VERSION ""

NS_ :

BS_:

BU_: PowertrainControlModule AtmosphericSensor SafetyRestraintSystem2 Aftertreatment_2_GasOutlet Aftertreatment_2_GasIntake DieselParticulateFilterControl Turbocharger SafetyRestraintSystem1 CabDisplay2 Aftertreatment_1_GasOutlet Aftertreatment_1_GasIntake OnBoardDataLogger OffBoardDiagnosticTool2 OffBoardDiagnosticTool1 FileServer ParkingBrakeController SeatController2 FanDriveController SteeringColumnUnit CommunicationUnitRadio CommunicationUnitSatellite CommunicationUnitCellular PropulsionBatteryCharger ChassisController2 ChassisController1 EngineValveControl AuxiliaryHeater2 AuxiliaryHeater1 ClutchUnit RampControl InformationSystem1 SuspensionSystemController2 OilSensor VehicleDynamicStability ExhaustEmissionController TransmissionDisplay2 TransmissionDisplay1 ClimateControl2 WaterPumpController RearAxleSteeringController LightingOperatorControl SeatController1 IgnitionController2 IgnitionController1 TirePressureController CabController2 CabController1 PneumaticSystemController SuspensionSystemController1 HydraulicPumpController EnduranceBrakingSystem RetarderExhaustEngine2 OnBoardDiagnosticUnit HeadwayController RetarderExhaustEngine1 CabDisplay1 ManagementComputer VirtualTerminal OffVehicleGateway PowerTakeOffFront HitchControl AuxiliaryValveControl BodyController TractorTrailerBridge1 StarterSystem ElectricalSystem VehicleSecurity VehicleNavigation AerodynamicControl ElectricalChargingSystem ClimateControl1 TripRecorder InstrumentCluster SuspensionDriveAxle2 SuspensionDriveAxle1 SuspensionSteerAxle SteeringController FuelSystem CruiseControl RetarderDriveline RetarderEngine BrakesDriveAxle2 BrakesDriveAxle1 BrakesSystemController BrakesSteerAxle AxleDrive2 AxleDrive1 AxleSteering PowerTakeOff ShiftConsoleSecondary ShiftConsolePrimary Transmission2 Transmission1 Engine2 Engine1

BO_ 2633669886 HVESP23HIST: 19 Vector__XXX
 SG_ TotalEnergyOut : 120|32@1+ (1,0) [0|4211081215] "kWh" Vector__XXX
 SG_ TotalEnergyInput : 88|32@1+ (1,0) [0|4211081215] "kWh" Vector__XXX
 SG_ TotalAccumulatedCharge : 56|32@1+ (100,0) [0|421108121500] "Ah" Vector__XXX
 SG_ TotalEnergyThroughput : 24|32@1+ (100,0) [0|421108121500] "Wh" Vector__XXX
 SG_ ContactorOpenUnderLoadCount : 8|16@1+ (1,0) [0|64255] "" Vector__XXX
 SG_ StOfHealth : 0|8@1+ (0.4,0) [0|100] "%" Vector__XXX

BO_ 2566560766 HVESP22CFG: 19 Vector__XXX
 SG_ NomRatedCapacity : 128|24@1+ (0.001,0) [0|16449.535] "kWh" Vector__XXX
 SG_ CellMinVLmt : 120|8@1+ (0.02044,0) [0|5.11] "V" Vector__XXX
 SG_ CellMaxVLmt : 112|8@1+ (0.02044,0) [0|5.11] "V" Vector__XXX
 SG_ RecommendedMinOperatingTemp : 96|16@1+ (0.03125,-273) [-273|1734.96875] "°C" Vector__XXX
 SG_ RecommendedMaxOperatingTemp : 80|16@1+ (0.03125,-273) [-273|1734.96875] "°C" Vector__XXX
 SG_ RecommendedMaxStOfCharge : 64|16@1+ (0.0015625,0) [0|100.3984375] "%" Vector__XXX
 SG_ RecommendedMinStOfCharge : 48|16@1+ (0.0015625,0) [0|100.3984375] "%" Vector__XXX
 SG_ RecommendedMaxOperatingV : 32|16@1+ (0.05,0) [0|3212.75] "V" Vector__XXX
 SG_ RecommendedMinOperatingV : 16|16@1+ (0.05,0) [0|3212.75] "V" Vector__XXX
 SG_ NomV : 0|16@1+ (0.05,0) [0|3212.75] "V" Vector__XXX

BO_ 2633669374 HVESP22HIST: 19 Vector__XXX
 SG_ TotalEnergyOut : 120|32@1+ (1,0) [0|4211081215] "kWh" Vector__XXX
 SG_ TotalEnergyInput : 88|32@1+ (1,0) [0|4211081215] "kWh" Vector__XXX
 SG_ TotalAccumulatedCharge : 56|32@1+ (100,0) [0|421108121500] "Ah" Vector__XXX
 SG_ TotalEnergyThroughput : 24|32@1+ (100,0) [0|421108121500] "Wh" Vector__XXX
 SG_ ContactorOpenUnderLoadCount : 8|16@1+ (1,0) [0|64255] "" Vector__XXX
 SG_ StOfHealth : 0|8@1+ (0.4,0) [0|100] "%" Vector__XXX

BO_ 2566560254 HVESP21CFG: 19 Vector__XXX
 SG_ NomRatedCapacity : 128|24@1+ (0.001,0) [0|16449.535] "kWh" Vector__XXX
 SG_ CellMinVLmt : 120|8@1+ (0.02044,0) [0|5.11] "V" Vector__XXX
 SG_ CellMaxVLmt : 112|8@1+ (0.02044,0) [0|5.11] "V" Vector__XXX
 SG_ RecommendedMinOperatingTemp : 96|16@1+ (0.03125,-273) [-273|1734.96875] "°C" Vector__XXX
 SG_ RecommendedMaxOperatingTemp : 80|16@1+ (0.03125,-273) [-273|1734.96875] "°C" Vector__XXX
 SG_ RecommendedMaxStOfCharge : 64|16@1+ (0.0015625,0) [0|100.3984375] "%" Vector__XXX
 SG_ RecommendedMinStOfCharge : 48|16@1+ (0.0015625,0) [0|100.3984375] "%" Vector__XXX
 SG_ RecommendedMaxOperatingV : 32|16@1+ (0.05,0) [0|3212.75] "V" Vector__XXX
 SG_ RecommendedMinOperatingV : 16|16@1+ (0.05,0) [0|3212.75] "V" Vector__XXX
 SG_ NomV : 0|16@1+ (0.05,0) [0|3212.75] "V" Vector__XXX

BO_ 2633668862 HVESP21HIST: 19 Vector__XXX
 SG_ TotalEnergyOut : 120|32@1+ (1,0) [0|4211081215] "kWh" Vector__XXX
 SG_ TotalEnergyInput : 88|32@1+ (1,0) [0|4211081215] "kWh" Vector__XXX
 SG_ TotalAccumulatedCharge : 56|32@1+ (100,0) [0|421108121500] "Ah" Vector__XXX
 SG_ TotalEnergyThroughput : 24|32@1+ (100,0) [0|421108121500] "Wh" Vector__XXX
 SG_ ContactorOpenUnderLoadCount : 8|16@1+ (1,0) [0|64255] "" Vector__XXX
 SG_ StOfHealth : 0|8@1+ (0.4,0) [0|100] "%" Vector__XXX

BO_ 2566559742 HVESP20CFG: 19 Vector__XXX
 SG_ NomRatedCapacity : 128|24@1+ (0.001,0) [0|16449.535] "kWh" Vector__XXX
 SG_ CellMinVLmt : 120|8@1+ (0.02044,0) [0|5.11] "V" Vector__XXX
 SG_ CellMaxVLmt : 112|8@1+ (0.02044,0) [0|5.11] "V" Vector__XXX
 SG_ RecommendedMinOperatingTemp : 96|16@1+ (0.03125,-273) [-273|1734.96875] "°C" Vector__XXX
 SG_ RecommendedMaxOperatingTemp : 80|16@1+ (0.03125,-273) [-273|1734.96875] "°C" Vector__XXX
 SG_ RecommendedMaxStOfCharge : 64|16@1+ (0.0015625,0) [0|100.3984375] "%" Vector__XXX
 SG_ RecommendedMinStOfCharge : 48|16@1+ (0.0015625,0) [0|100.3984375] "%" Vector__XXX
 SG_ RecommendedMaxOperatingV : 32|16@1+ (0.05,0) [0|3212.75] "V" Vector__XXX
 SG_ RecommendedMinOperatingV : 16|16@1+ (0.05,0) [0|3212.75] "V" Vector__XXX
 SG_ NomV : 0|16@1+ (0.05,0) [0|3212.75] "V" Vector__XXX

BO_ 2633668350 HVESP20HIST: 19 Vector__XXX
 SG_ TotalEnergyOut : 120|32@1+ (1,0) [0|4211081215] "kWh" Vector__XXX
 SG_ TotalEnergyInput : 88|32@1+ (1,0) [0|4211081215] "kWh" Vector__XXX
 SG_ TotalAccumulatedCharge : 56|32@1+ (100,0) [0|421108121500] "Ah" Vector__XXX
 SG_ TotalEnergyThroughput : 24|32@1+ (100,0) [0|421108121500] "Wh" Vector__XXX
 SG_ ContactorOpenUnderLoadCount : 8|16@1+ (1,0) [0|64255] "" Vector__XXX
 SG_ StOfHealth : 0|8@1+ (0.4,0) [0|100] "%" Vector__XXX

BO_ 2566559230 HVESP19CFG: 19 Vector__XXX
 SG_ NomRatedCapacity : 128|24@1+ (0.001,0) [0|16449.535] "kWh" Vector__XXX
 SG_ CellMinVLmt : 120|8@1+ (0.02044,0) [0|5.11] "V" Vector__XXX
 SG_ CellMaxVLmt : 112|8@1+ (0.02044,0) [0|5.11] "V" Vector__XXX
 SG_ RecommendedMinOperatingTemp : 96|16@1+ (0.03125,-273) [-273|1734.96875] "°C" Vector__XXX
 SG_ RecommendedMaxOperatingTemp : 80|16@1+ (0.03125,-273) [-273|1734.96875] "°C" Vector__XXX
 SG_ RecommendedMaxStOfCharge : 64|16@1+ (0.0015625,0) [0|100.3984375] "%" Vector__XXX
 SG_ RecommendedMinStOfCharge : 48|16@1+ (0.0015625,0) [0|100.3984375] "%" Vector__XXX
 SG_ RecommendedMaxOperatingV : 32|16@1+ (0.05,0) [0|3212.75] "V" Vector__XXX
 SG_ RecommendedMinOperatingV : 16|16@1+ (0.05,0) [0|3212.75] "V" Vector__XXX
 SG_ NomV : 0|16@1+ (0.05,0) [0|3212.75] "V" Vector__XXX

BO_ 2633667838 HVESP19HIST: 19 Vector__XXX
 SG_ TotalEnergyOut : 120|32@1+ (1,0) [0|4211081215] "kWh" Vector__XXX
 SG_ TotalEnergyInput : 88|32@1+ (1,0) [0|4211081215] "kWh" Vector__XXX
 SG_ TotalAccumulatedCharge : 56|32@1+ (100,0) [0|421108121500] "Ah" Vector__XXX
 SG_ TotalEnergyThroughput : 24|32@1+ (100,0) [0|421108121500] "Wh" Vector__XXX
 SG_ ContactorOpenUnderLoadCount : 8|16@1+ (1,0) [0|64255] "" Vector__XXX
 SG_ StOfHealth : 0|8@1+ (0.4,0) [0|100] "%" Vector__XXX

BO_ 2566558718 HVESP18CFG: 19 Vector__XXX
 SG_ NomRatedCapacity : 128|24@1+ (0.001,0) [0|16449.535] "kWh" Vector__XXX
 SG_ CellMinVLmt : 120|8@1+ (0.02044,0) [0|5.11] "V" Vector__XXX
 SG_ CellMaxVLmt : 112|8@1+ (0.02044,0) [0|5.11] "V" Vector__XXX
 SG_ RecommendedMinOperatingTemp : 96|16@1+ (0.03125,-273) [-273|1734.96875] "°C" Vector__XXX
 SG_ RecommendedMaxOperatingTemp : 80|16@1+ (0.03125,-273) [-273|1734.96875] "°C" Vector__XXX
 SG_ RecommendedMaxStOfCharge : 64|16@1+ (0.0015625,0) [0|100.3984375] "%" Vector__XXX
 SG_ RecommendedMinStOfCharge : 48|16@1+ (0.0015625,0) [0|100.3984375] "%" Vector__XXX
 SG_ RecommendedMaxOperatingV : 32|16@1+ (0.05,0) [0|3212.75] "V" Vector__XXX
 SG_ RecommendedMinOperatingV : 16|16@1+ (0.05,0) [0|3212.75] "V" Vector__XXX
 SG_ NomV : 0|16@1+ (0.05,0) [0|3212.75] "V" Vector__XXX

BO_ 2633667326 HVESP18HIST: 19 Vector__XXX
 SG_ TotalEnergyOut : 120|32@1+ (1,0) [0|4211081215] "kWh" Vector__XXX
 SG_ TotalEnergyInput : 88|32@1+ (1,0) [0|4211081215] "kWh" Vector__XXX
 SG_ TotalAccumulatedCharge : 56|32@1+ (100,0) [0|421108121500] "Ah" Vector__XXX
 SG_ TotalEnergyThroughput : 24|32@1+ (100,0) [0|421108121500] "Wh" Vector__XXX
 SG_ ContactorOpenUnderLoadCount : 8|16@1+ (1,0) [0|64255] "" Vector__XXX
 SG_ StOfHealth : 0|8@1+ (0.4,0) [0|100] "%" Vector__XXX

BO_ 2566558206 HVESP17CFG: 19 Vector__XXX
 SG_ NomRatedCapacity : 128|24@1+ (0.001,0) [0|16449.535] "kWh" Vector__XXX
 SG_ CellMinVLmt : 120|8@1+ (0.02044,0) [0|5.11] "V" Vector__XXX
 SG_ CellMaxVLmt : 112|8@1+ (0.02044,0) [0|5.11] "V" Vector__XXX
 SG_ RecommendedMinOperatingTemp : 96|16@1+ (0.03125,-273) [-273|1734.96875] "°C" Vector__XXX
 SG_ RecommendedMaxOperatingTemp : 80|16@1+ (0.03125,-273) [-273|1734.96875] "°C" Vector__XXX
 SG_ RecommendedMaxStOfCharge : 64|16@1+ (0.0015625,0) [0|100.3984375] "%" Vector__XXX
 SG_ RecommendedMinStOfCharge : 48|16@1+ (0.0015625,0) [0|100.3984375] "%" Vector__XXX
 SG_ RecommendedMaxOperatingV : 32|16@1+ (0.05,0) [0|3212.75] "V" Vector__XXX
 SG_ RecommendedMinOperatingV : 16|16@1+ (0.05,0) [0|3212.75] "V" Vector__XXX
 SG_ NomV : 0|16@1+ (0.05,0) [0|3212.75] "V" Vector__XXX

BO_ 2633666814 HVESP17HIST: 19 Vector__XXX
 SG_ TotalEnergyOut : 120|32@1+ (1,0) [0|4211081215] "kWh" Vector__XXX
 SG_ TotalEnergyInput : 88|32@1+ (1,0) [0|4211081215] "kWh" Vector__XXX
 SG_ TotalAccumulatedCharge : 56|32@1+ (100,0) [0|421108121500] "Ah" Vector__XXX
 SG_ TotalEnergyThroughput : 24|32@1+ (100,0) [0|421108121500] "Wh" Vector__XXX
 SG_ ContactorOpenUnderLoadCount : 8|16@1+ (1,0) [0|64255] "" Vector__XXX
 SG_ StOfHealth : 0|8@1+ (0.4,0) [0|100] "%" Vector__XXX

BO_ 2566557694 HVESP16CFG: 19 Vector__XXX
 SG_ NomRatedCapacity : 128|24@1+ (0.001,0) [0|16449.535] "kWh" Vector__XXX
 SG_ CellMinVLmt : 120|8@1+ (0.02044,0) [0|5.11] "V" Vector__XXX
 SG_ CellMaxVLmt : 112|8@1+ (0.02044,0) [0|5.11] "V" Vector__XXX
 SG_ RecommendedMinOperatingTemp : 96|16@1+ (0.03125,-273) [-273|1734.96875] "°C" Vector__XXX
 SG_ RecommendedMaxOperatingTemp : 80|16@1+ (0.03125,-273) [-273|1734.96875] "°C" Vector__XXX
 SG_ RecommendedMaxStOfCharge : 64|16@1+ (0.0015625,0) [0|100.3984375] "%" Vector__XXX
 SG_ RecommendedMinStOfCharge : 48|16@1+ (0.0015625,0) [0|100.3984375] "%" Vector__XXX
 SG_ RecommendedMaxOperatingV : 32|16@1+ (0.05,0) [0|3212.75] "V" Vector__XXX
 SG_ RecommendedMinOperatingV : 16|16@1+ (0.05,0) [0|3212.75] "V" Vector__XXX
 SG_ NomV : 0|16@1+ (0.05,0) [0|3212.75] "V" Vector__XXX

BO_ 2633666302 HVESP16HIST: 19 Vector__XXX
 SG_ TotalEnergyOut : 120|32@1+ (1,0) [0|4211081215] "kWh" Vector__XXX
 SG_ TotalEnergyInput : 88|32@1+ (1,0) [0|4211081215] "kWh" Vector__XXX
 SG_ TotalAccumulatedCharge : 56|32@1+ (100,0) [0|421108121500] "Ah" Vector__XXX
 SG_ TotalEnergyThroughput : 24|32@1+ (100,0) [0|421108121500] "Wh" Vector__XXX
 SG_ ContactorOpenUnderLoadCount : 8|16@1+ (1,0) [0|64255] "" Vector__XXX
 SG_ StOfHealth : 0|8@1+ (0.4,0) [0|100] "%" Vector__XXX

BO_ 2566557182 HVESP15CFG: 19 Vector__XXX
 SG_ NomRatedCapacity : 128|24@1+ (0.001,0) [0|16449.535] "kWh" Vector__XXX
 SG_ CellMinVLmt : 120|8@1+ (0.02044,0) [0|5.11] "V" Vector__XXX
 SG_ CellMaxVLmt : 112|8@1+ (0.02044,0) [0|5.11] "V" Vector__XXX
 SG_ RecommendedMinOperatingTemp : 96|16@1+ (0.03125,-273) [-273|1734.96875] "°C" Vector__XXX
 SG_ RecommendedMaxOperatingTemp : 80|16@1+ (0.03125,-273) [-273|1734.96875] "°C" Vector__XXX
 SG_ RecommendedMaxStOfCharge : 64|16@1+ (0.0015625,0) [0|100.3984375] "%" Vector__XXX
 SG_ RecommendedMinStOfCharge : 48|16@1+ (0.0015625,0) [0|100.3984375] "%" Vector__XXX
 SG_ RecommendedMaxOperatingV : 32|16@1+ (0.05,0) [0|3212.75] "V" Vector__XXX
 SG_ RecommendedMinOperatingV : 16|16@1+ (0.05,0) [0|3212.75] "V" Vector__XXX
 SG_ NomV : 0|16@1+ (0.05,0) [0|3212.75] "V" Vector__XXX

BO_ 2633665790 HVESP15HIST: 19 Vector__XXX
 SG_ TotalEnergyOut : 120|32@1+ (1,0) [0|4211081215] "kWh" Vector__XXX
 SG_ TotalEnergyInput : 88|32@1+ (1,0) [0|4211081215] "kWh" Vector__XXX
 SG_ TotalAccumulatedCharge : 56|32@1+ (100,0) [0|421108121500] "Ah" Vector__XXX
 SG_ TotalEnergyThroughput : 24|32@1+ (100,0) [0|421108121500] "Wh" Vector__XXX
 SG_ ContactorOpenUnderLoadCount : 8|16@1+ (1,0) [0|64255] "" Vector__XXX
 SG_ StOfHealth : 0|8@1+ (0.4,0) [0|100] "%" Vector__XXX

BO_ 2566556670 HVESP14CFG: 19 Vector__XXX
 SG_ NomRatedCapacity : 128|24@1+ (0.001,0) [0|16449.535] "kWh" Vector__XXX
 SG_ CellMinVLmt : 120|8@1+ (0.02044,0) [0|5.11] "V" Vector__XXX
 SG_ CellMaxVLmt : 112|8@1+ (0.02044,0) [0|5.11] "V" Vector__XXX
 SG_ RecommendedMinOperatingTemp : 96|16@1+ (0.03125,-273) [-273|1734.96875] "°C" Vector__XXX
 SG_ RecommendedMaxOperatingTemp : 80|16@1+ (0.03125,-273) [-273|1734.96875] "°C" Vector__XXX
 SG_ RecommendedMaxStOfCharge : 64|16@1+ (0.0015625,0) [0|100.3984375] "%" Vector__XXX
 SG_ RecommendedMinStOfCharge : 48|16@1+ (0.0015625,0) [0|100.3984375] "%" Vector__XXX
 SG_ RecommendedMaxOperatingV : 32|16@1+ (0.05,0) [0|3212.75] "V" Vector__XXX
 SG_ RecommendedMinOperatingV : 16|16@1+ (0.05,0) [0|3212.75] "V" Vector__XXX
 SG_ NomV : 0|16@1+ (0.05,0) [0|3212.75] "V" Vector__XXX

BO_ 2633665278 HVESP14HIST: 19 Vector__XXX
 SG_ TotalEnergyOut : 120|32@1+ (1,0) [0|4211081215] "kWh" Vector__XXX
 SG_ TotalEnergyInput : 88|32@1+ (1,0) [0|4211081215] "kWh" Vector__XXX
 SG_ TotalAccumulatedCharge : 56|32@1+ (100,0) [0|421108121500] "Ah" Vector__XXX
 SG_ TotalEnergyThroughput : 24|32@1+ (100,0) [0|421108121500] "Wh" Vector__XXX
 SG_ ContactorOpenUnderLoadCount : 8|16@1+ (1,0) [0|64255] "" Vector__XXX
 SG_ StOfHealth : 0|8@1+ (0.4,0) [0|100] "%" Vector__XXX

BO_ 2566556158 HVESP13CFG: 19 Vector__XXX
 SG_ NomRatedCapacity : 128|24@1+ (0.001,0) [0|16449.535] "kWh" Vector__XXX
 SG_ CellMinVLmt : 120|8@1+ (0.02044,0) [0|5.11] "V" Vector__XXX
 SG_ CellMaxVLmt : 112|8@1+ (0.02044,0) [0|5.11] "V" Vector__XXX
 SG_ RecommendedMinOperatingTemp : 96|16@1+ (0.03125,-273) [-273|1734.96875] "°C" Vector__XXX
 SG_ RecommendedMaxOperatingTemp : 80|16@1+ (0.03125,-273) [-273|1734.96875] "°C" Vector__XXX
 SG_ RecommendedMaxStOfCharge : 64|16@1+ (0.0015625,0) [0|100.3984375] "%" Vector__XXX
 SG_ RecommendedMinStOfCharge : 48|16@1+ (0.0015625,0) [0|100.3984375] "%" Vector__XXX
 SG_ RecommendedMaxOperatingV : 32|16@1+ (0.05,0) [0|3212.75] "V" Vector__XXX
 SG_ RecommendedMinOperatingV : 16|16@1+ (0.05,0) [0|3212.75] "V" Vector__XXX
 SG_ NomV : 0|16@1+ (0.05,0) [0|3212.75] "V" Vector__XXX

BO_ 2633664766 HVESP13HIST: 19 Vector__XXX
 SG_ TotalEnergyOut : 120|32@1+ (1,0) [0|4211081215] "kWh" Vector__XXX
 SG_ TotalEnergyInput : 88|32@1+ (1,0) [0|4211081215] "kWh" Vector__XXX
 SG_ TotalAccumulatedCharge : 56|32@1+ (100,0) [0|421108121500] "Ah" Vector__XXX
 SG_ TotalEnergyThroughput : 24|32@1+ (100,0) [0|421108121500] "Wh" Vector__XXX
 SG_ ContactorOpenUnderLoadCount : 8|16@1+ (1,0) [0|64255] "" Vector__XXX
 SG_ StOfHealth : 0|8@1+ (0.4,0) [0|100] "%" Vector__XXX

BO_ 2566555646 HVESP12CFG: 19 Vector__XXX
 SG_ NomRatedCapacity : 128|24@1+ (0.001,0) [0|16449.535] "kWh" Vector__XXX
 SG_ CellMinVLmt : 120|8@1+ (0.02044,0) [0|5.11] "V" Vector__XXX
 SG_ CellMaxVLmt : 112|8@1+ (0.02044,0) [0|5.11] "V" Vector__XXX
 SG_ RecommendedMinOperatingTemp : 96|16@1+ (0.03125,-273) [-273|1734.96875] "°C" Vector__XXX
 SG_ RecommendedMaxOperatingTemp : 80|16@1+ (0.03125,-273) [-273|1734.96875] "°C" Vector__XXX
 SG_ RecommendedMaxStOfCharge : 64|16@1+ (0.0015625,0) [0|100.3984375] "%" Vector__XXX
 SG_ RecommendedMinStOfCharge : 48|16@1+ (0.0015625,0) [0|100.3984375] "%" Vector__XXX
 SG_ RecommendedMaxOperatingV : 32|16@1+ (0.05,0) [0|3212.75] "V" Vector__XXX
 SG_ RecommendedMinOperatingV : 16|16@1+ (0.05,0) [0|3212.75] "V" Vector__XXX
 SG_ NomV : 0|16@1+ (0.05,0) [0|3212.75] "V" Vector__XXX

BO_ 2633664254 HVESP12HIST: 19 Vector__XXX
 SG_ TotalEnergyOut : 120|32@1+ (1,0) [0|4211081215] "kWh" Vector__XXX
 SG_ TotalEnergyInput : 88|32@1+ (1,0) [0|4211081215] "kWh" Vector__XXX
 SG_ TotalAccumulatedCharge : 56|32@1+ (100,0) [0|421108121500] "Ah" Vector__XXX
 SG_ TotalEnergyThroughput : 24|32@1+ (100,0) [0|421108121500] "Wh" Vector__XXX
 SG_ ContactorOpenUnderLoadCount : 8|16@1+ (1,0) [0|64255] "" Vector__XXX
 SG_ StOfHealth : 0|8@1+ (0.4,0) [0|100] "%" Vector__XXX

BO_ 2566555134 HVESP11CFG: 19 Vector__XXX
 SG_ NomRatedCapacity : 128|24@1+ (0.001,0) [0|16449.535] "kWh" Vector__XXX
 SG_ CellMinVLmt : 120|8@1+ (0.02044,0) [0|5.11] "V" Vector__XXX
 SG_ CellMaxVLmt : 112|8@1+ (0.02044,0) [0|5.11] "V" Vector__XXX
 SG_ RecommendedMinOperatingTemp : 96|16@1+ (0.03125,-273) [-273|1734.96875] "°C" Vector__XXX
 SG_ RecommendedMaxOperatingTemp : 80|16@1+ (0.03125,-273) [-273|1734.96875] "°C" Vector__XXX
 SG_ RecommendedMaxStOfCharge : 64|16@1+ (0.0015625,0) [0|100.3984375] "%" Vector__XXX
 SG_ RecommendedMinStOfCharge : 48|16@1+ (0.0015625,0) [0|100.3984375] "%" Vector__XXX
 SG_ RecommendedMaxOperatingV : 32|16@1+ (0.05,0) [0|3212.75] "V" Vector__XXX
 SG_ RecommendedMinOperatingV : 16|16@1+ (0.05,0) [0|3212.75] "V" Vector__XXX
 SG_ NomV : 0|16@1+ (0.05,0) [0|3212.75] "V" Vector__XXX

BO_ 2633663742 HVESP11HIST: 19 Vector__XXX
 SG_ TotalEnergyOut : 120|32@1+ (1,0) [0|4211081215] "kWh" Vector__XXX
 SG_ TotalEnergyInput : 88|32@1+ (1,0) [0|4211081215] "kWh" Vector__XXX
 SG_ TotalAccumulatedCharge : 56|32@1+ (100,0) [0|421108121500] "Ah" Vector__XXX
 SG_ TotalEnergyThroughput : 24|32@1+ (100,0) [0|421108121500] "Wh" Vector__XXX
 SG_ ContactorOpenUnderLoadCount : 8|16@1+ (1,0) [0|64255] "" Vector__XXX
 SG_ StOfHealth : 0|8@1+ (0.4,0) [0|100] "%" Vector__XXX

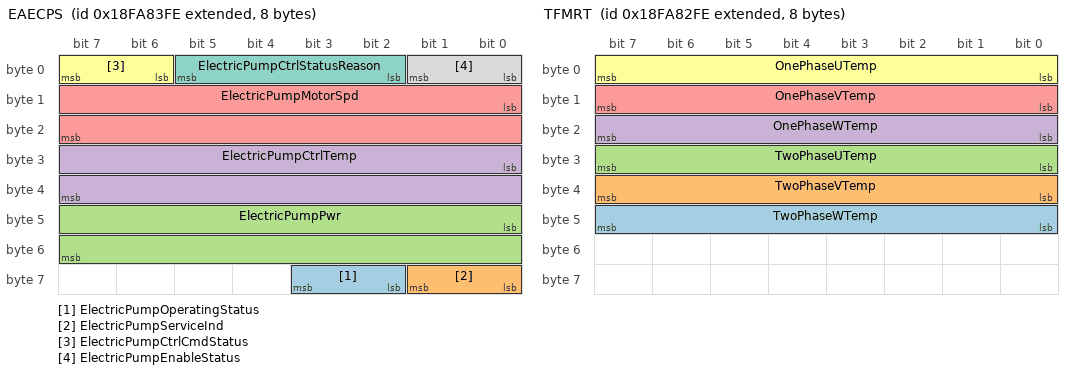
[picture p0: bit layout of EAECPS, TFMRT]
BO_ 2566554622 EAECPS: 8 Vector__XXX
 SG_ ElectricPumpOperatingStatus : 58|2@1+ (1,0) [0|3] "" Vector__XXX
 SG_ ElectricPumpServiceInd : 56|2@1+ (1,0) [0|3] "" Vector__XXX
 SG_ ElectricPumpPwr : 40|16@1+ (0.5,0) [0|32127.5] "W" Vector__XXX
 SG_ ElectricPumpCtrlTemp : 24|16@1+ (0.03125,-273) [-273|1734.96875] "°C" Vector__XXX
 SG_ ElectricPumpMotorSpd : 8|16@1+ (0.5,0) [0|32127.5] "rpm" Vector__XXX
 SG_ ElectricPumpCtrlCmdStatus : 6|2@1+ (1,0) [0|3] "" Vector__XXX
 SG_ ElectricPumpCtrlStatusReason : 2|4@1+ (1,0) [0|15] "" Vector__XXX
 SG_ ElectricPumpEnableStatus : 0|2@1+ (1,0) [0|3] "" Vector__XXX

BO_ 2566554366 TFMRT: 8 Vector__XXX
 SG_ TwoPhaseWTemp : 40|8@1+ (1,-40) [-40|210] "°C" Vector__XXX
 SG_ TwoPhaseVTemp : 32|8@1+ (1,-40) [-40|210] "°C" Vector__XXX
 SG_ TwoPhaseUTemp : 24|8@1+ (1,-40) [-40|210] "°C" Vector__XXX
 SG_ OnePhaseWTemp : 16|8@1+ (1,-40) [-40|210] "°C" Vector__XXX
 SG_ OnePhaseVTemp : 8|8@1+ (1,-40) [-40|210] "°C" Vector__XXX
 SG_ OnePhaseUTemp : 0|8@1+ (1,-40) [-40|210] "°C" Vector__XXX

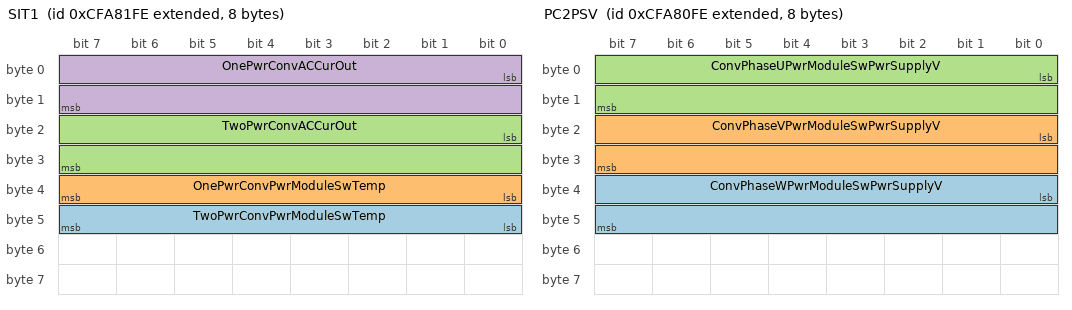
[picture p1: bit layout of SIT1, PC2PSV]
BO_ 2365227518 SIT1: 8 Vector__XXX
 SG_ TwoPwrConvPwrModuleSwTemp : 40|8@1+ (1,-40) [-40|210] "°C" Vector__XXX
 SG_ OnePwrConvPwrModuleSwTemp : 32|8@1+ (1,-40) [-40|210] "°C" Vector__XXX
 SG_ TwoPwrConvACCurOut : 16|16@1+ (0.125,0) [0|8031.875] "A" Vector__XXX
 SG_ OnePwrConvACCurOut : 0|16@1+ (0.125,0) [0|8031.875] "A" Vector__XXX

BO_ 2365227262 PC2PSV: 8 Vector__XXX
 SG_ ConvPhaseWPwrModuleSwPwrSupplyV : 32|16@1+ (0.125,0) [0|8031.875] "V" Vector__XXX
 SG_ ConvPhaseVPwrModuleSwPwrSupplyV : 16|16@1+ (0.125,0) [0|8031.875] "V" Vector__XXX
 SG_ ConvPhaseUPwrModuleSwPwrSupplyV : 0|16@1+ (0.125,0) [0|8031.875] "V" Vector__XXX

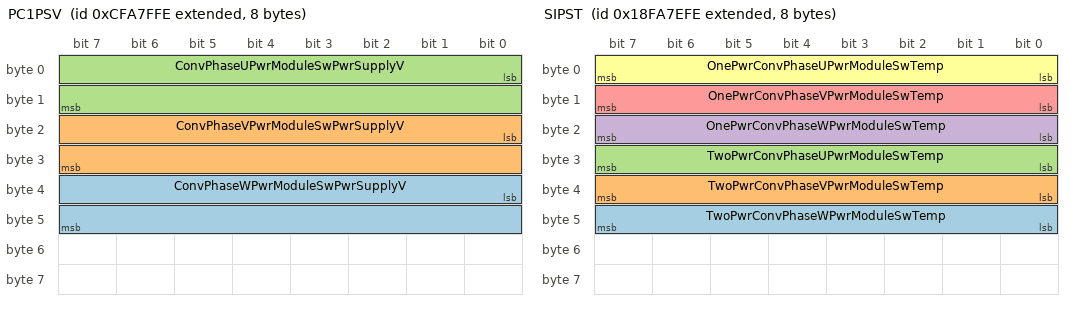
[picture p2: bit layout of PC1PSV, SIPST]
BO_ 2365227006 PC1PSV: 8 Vector__XXX
 SG_ ConvPhaseWPwrModuleSwPwrSupplyV : 32|16@1+ (0.125,0) [0|8031.875] "V" Vector__XXX
 SG_ ConvPhaseVPwrModuleSwPwrSupplyV : 16|16@1+ (0.125,0) [0|8031.875] "V" Vector__XXX
 SG_ ConvPhaseUPwrModuleSwPwrSupplyV : 0|16@1+ (0.125,0) [0|8031.875] "V" Vector__XXX

BO_ 2566553342 SIPST: 8 Vector__XXX
 SG_ TwoPwrConvPhaseWPwrModuleSwTemp : 40|8@1+ (1,-40) [-40|210] "°C" Vector__XXX
 SG_ TwoPwrConvPhaseVPwrModuleSwTemp : 32|8@1+ (1,-40) [-40|210] "°C" Vector__XXX
 SG_ TwoPwrConvPhaseUPwrModuleSwTemp : 24|8@1+ (1,-40) [-40|210] "°C" Vector__XXX
 SG_ OnePwrConvPhaseWPwrModuleSwTemp : 16|8@1+ (1,-40) [-40|210] "°C" Vector__XXX
 SG_ OnePwrConvPhaseVPwrModuleSwTemp : 8|8@1+ (1,-40) [-40|210] "°C" Vector__XXX
 SG_ OnePwrConvPhaseUPwrModuleSwTemp : 0|8@1+ (1,-40) [-40|210] "°C" Vector__XXX

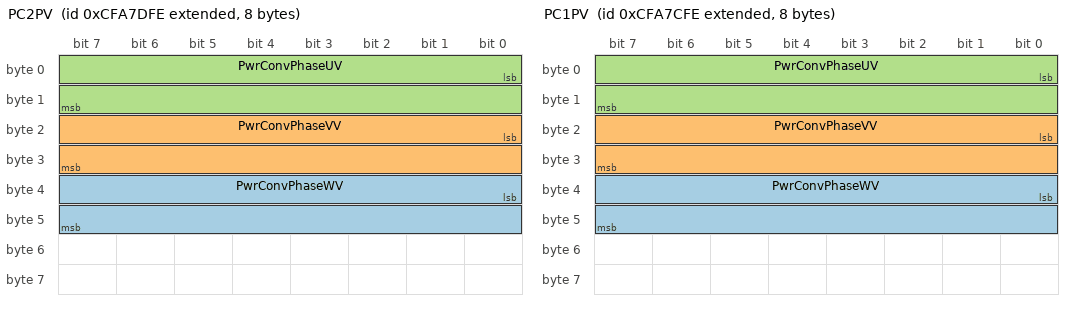
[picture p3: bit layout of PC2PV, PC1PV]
BO_ 2365226494 PC2PV: 8 Vector__XXX
 SG_ PwrConvPhaseWV : 32|16@1+ (0.125,0) [0|8031.875] "V" Vector__XXX
 SG_ PwrConvPhaseVV : 16|16@1+ (0.125,0) [0|8031.875] "V" Vector__XXX
 SG_ PwrConvPhaseUV : 0|16@1+ (0.125,0) [0|8031.875] "V" Vector__XXX

BO_ 2365226238 PC1PV: 8 Vector__XXX
 SG_ PwrConvPhaseWV : 32|16@1+ (0.125,0) [0|8031.875] "V" Vector__XXX
 SG_ PwrConvPhaseVV : 16|16@1+ (0.125,0) [0|8031.875] "V" Vector__XXX
 SG_ PwrConvPhaseUV : 0|16@1+ (0.125,0) [0|8031.875] "V" Vector__XXX

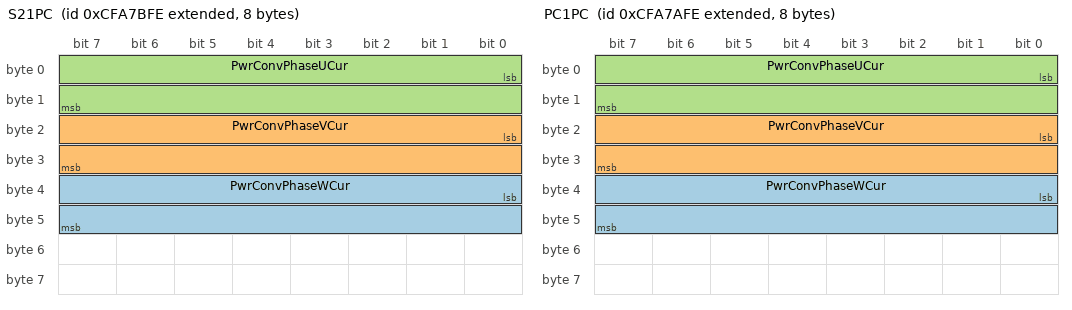
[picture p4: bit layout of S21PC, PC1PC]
BO_ 2365225982 S21PC: 8 Vector__XXX
 SG_ PwrConvPhaseWCur : 32|16@1+ (0.125,0) [0|8031.875] "A" Vector__XXX
 SG_ PwrConvPhaseVCur : 16|16@1+ (0.125,0) [0|8031.875] "A" Vector__XXX
 SG_ PwrConvPhaseUCur : 0|16@1+ (0.125,0) [0|8031.875] "A" Vector__XXX

BO_ 2365225726 PC1PC: 8 Vector__XXX
 SG_ PwrConvPhaseWCur : 32|16@1+ (0.125,0) [0|8031.875] "A" Vector__XXX
 SG_ PwrConvPhaseVCur : 16|16@1+ (0.125,0) [0|8031.875] "A" Vector__XXX
 SG_ PwrConvPhaseUCur : 0|16@1+ (0.125,0) [0|8031.875] "A" Vector__XXX

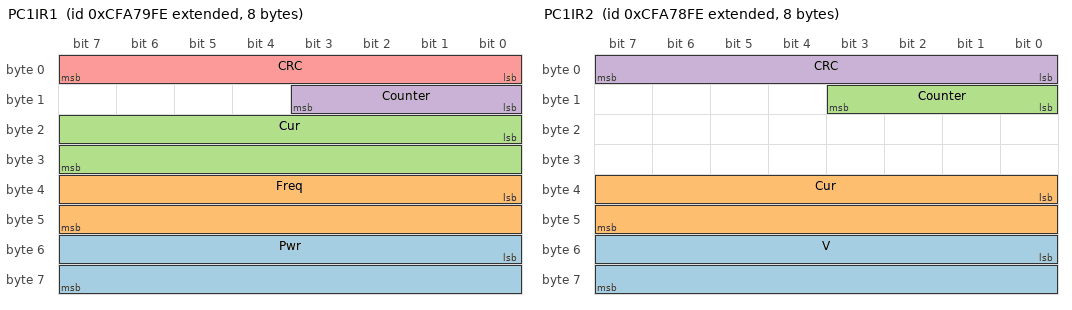
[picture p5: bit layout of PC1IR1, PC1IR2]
BO_ 2365225470 PC1IR1: 8 Vector__XXX
 SG_ Pwr : 48|16@1+ (0.0625,0) [0|4015.9375] "kW" Vector__XXX
 SG_ Freq : 32|16@1+ (4,0) [0|257020] "rpm" Vector__XXX
 SG_ Cur : 16|16@1+ (0.5,0) [0|32127.5] "Nm" Vector__XXX
 SG_ Counter : 8|4@1+ (1,0) [0|15] "" Vector__XXX
 SG_ CRC : 0|8@1+ (1,0) [0|255] "" Vector__XXX

BO_ 2365225214 PC1IR2: 8 Vector__XXX
 SG_ V : 48|16@1+ (0.125,0) [0|8031.875] "V" Vector__XXX
 SG_ Cur : 32|16@1+ (0.125,0) [0|8031.875] "A" Vector__XXX
 SG_ Counter : 8|4@1+ (1,0) [0|15] "" Vector__XXX
 SG_ CRC : 0|8@1+ (1,0) [0|255] "" Vector__XXX

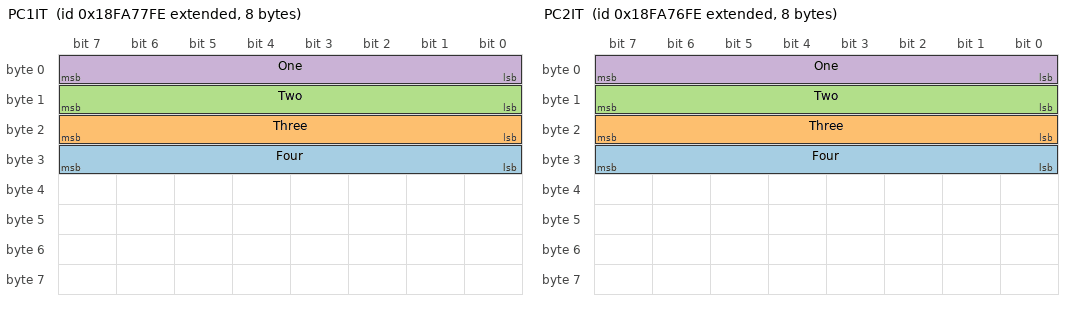
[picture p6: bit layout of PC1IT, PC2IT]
BO_ 2566551550 PC1IT: 8 Vector__XXX
 SG_ Four : 24|8@1+ (1,-40) [-40|210] "°C" Vector__XXX
 SG_ Three : 16|8@1+ (1,-40) [-40|210] "°C" Vector__XXX
 SG_ Two : 8|8@1+ (1,-40) [-40|210] "°C" Vector__XXX
 SG_ One : 0|8@1+ (1,-40) [-40|210] "°C" Vector__XXX

BO_ 2566551294 PC2IT: 8 Vector__XXX
 SG_ Four : 24|8@1+ (1,-40) [-40|210] "°C" Vector__XXX
 SG_ Three : 16|8@1+ (1,-40) [-40|210] "°C" Vector__XXX
 SG_ Two : 8|8@1+ (1,-40) [-40|210] "°C" Vector__XXX
 SG_ One : 0|8@1+ (1,-40) [-40|210] "°C" Vector__XXX

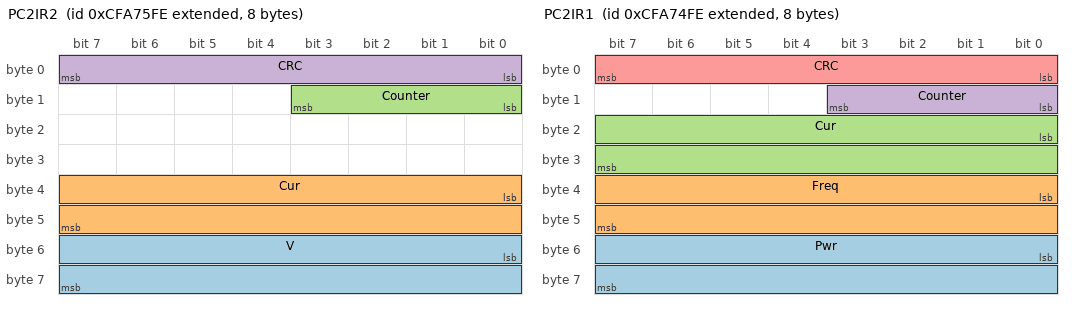
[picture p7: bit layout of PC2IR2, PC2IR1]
BO_ 2365224446 PC2IR2: 8 Vector__XXX
 SG_ V : 48|16@1+ (0.125,0) [0|8031.875] "V" Vector__XXX
 SG_ Cur : 32|16@1+ (0.125,0) [0|8031.875] "A" Vector__XXX
 SG_ Counter : 8|4@1+ (1,0) [0|15] "" Vector__XXX
 SG_ CRC : 0|8@1+ (1,0) [0|255] "" Vector__XXX

BO_ 2365224190 PC2IR1: 8 Vector__XXX
 SG_ Pwr : 48|16@1+ (0.0625,0) [0|4015.9375] "kW" Vector__XXX
 SG_ Freq : 32|16@1+ (4,0) [0|257020] "rpm" Vector__XXX
 SG_ Cur : 16|16@1+ (0.5,0) [0|32127.5] "Nm" Vector__XXX
 SG_ Counter : 8|4@1+ (1,0) [0|15] "" Vector__XXX
 SG_ CRC : 0|8@1+ (1,0) [0|255] "" Vector__XXX

BO_ 2566550526 PC1IAPL: 8 Vector__XXX
 SG_ CurLimDueToMachineCharac : 38|2@1+ (1,0) [0|3] "" Vector__XXX
 SG_ PLedDueToActiveCurRateLmt : 34|2@1+ (1,0) [0|3] "" Vector__XXX
 SG_ PLedDueToFaultCondition : 32|2@1+ (1,0) [0|3] "" Vector__XXX
 SG_ PLedDueToTemp : 30|2@1+ (1,0) [0|3] "" Vector__XXX
 SG_ PLedDueToInvTemp : 28|2@1+ (1,0) [0|3] "" Vector__XXX
 SG_ PLedDueToFreqMin : 24|2@1+ (1,0) [0|3] "" Vector__XXX
 SG_ PLedDueToFreqMax : 22|2@1+ (1,0) [0|3] "" Vector__XXX
 SG_ PLedDueToCurMin : 20|2@1+ (1,0) [0|3] "" Vector__XXX
 SG_ PLedDueToCurMax : 18|2@1+ (1,0) [0|3] "" Vector__XXX
 SG_ PLedDueToDCES1PwrMin : 16|2@1+ (1,0) [0|3] "" Vector__XXX
 SG_ PLedDueToDCES1PwrMax : 14|2@1+ (1,0) [0|3] "" Vector__XXX
 SG_ PLedDueToElectricalPwrMin : 12|2@1+ (1,0) [0|3] "" Vector__XXX
 SG_ PLedDueToElectricalPwrMax : 10|2@1+ (1,0) [0|3] "" Vector__XXX
 SG_ PLedDueToDCES1VMin : 8|2@1+ (1,0) [0|3] "" Vector__XXX
 SG_ PLedDueToDCES1VMax : 6|2@1+ (1,0) [0|3] "" Vector__XXX
 SG_ PLedDueToDCES1CurMin : 4|2@1+ (1,0) [0|3] "" Vector__XXX
 SG_ PLedDueToDCES1CurMax : 2|2@1+ (1,0) [0|3] "" Vector__XXX
 SG_ PLedDueToUndefinedReason : 0|2@1+ (1,0) [0|3] "" Vector__XXX

BO_ 2566550270 PC2IAPL: 8 Vector__XXX
 SG_ CurLimDueToMachineCharac : 38|2@1+ (1,0) [0|3] "" Vector__XXX
 SG_ PLedDueToActiveCurRateLmt : 34|2@1+ (1,0) [0|3] "" Vector__XXX
 SG_ PLedDueToFaultCondition : 32|2@1+ (1,0) [0|3] "" Vector__XXX
 SG_ PLedDueToTemp : 30|2@1+ (1,0) [0|3] "" Vector__XXX
 SG_ PLedDueToInvTemp : 28|2@1+ (1,0) [0|3] "" Vector__XXX
 SG_ PLedDueToFreqMin : 24|2@1+ (1,0) [0|3] "" Vector__XXX
 SG_ PLedDueToFreqMax : 22|2@1+ (1,0) [0|3] "" Vector__XXX
 SG_ PLedDueToCurMin : 20|2@1+ (1,0) [0|3] "" Vector__XXX
 SG_ PLedDueToCurMax : 18|2@1+ (1,0) [0|3] "" Vector__XXX
 SG_ PLedDueToDCES1PwrMin : 16|2@1+ (1,0) [0|3] "" Vector__XXX
 SG_ PLedDueToDCES1PwrMax : 14|2@1+ (1,0) [0|3] "" Vector__XXX
 SG_ PLedDueToElectricalPwrMin : 12|2@1+ (1,0) [0|3] "" Vector__XXX
 SG_ PLedDueToElectricalPwrMax : 10|2@1+ (1,0) [0|3] "" Vector__XXX
 SG_ PLedDueToDCES1VMin : 8|2@1+ (1,0) [0|3] "" Vector__XXX
 SG_ PLedDueToDCES1VMax : 6|2@1+ (1,0) [0|3] "" Vector__XXX
 SG_ PLedDueToDCES1CurMin : 4|2@1+ (1,0) [0|3] "" Vector__XXX
 SG_ PLedDueToDCES1CurMax : 2|2@1+ (1,0) [0|3] "" Vector__XXX
 SG_ PLedDueToUndefinedReason : 0|2@1+ (1,0) [0|3] "" Vector__XXX

BO_ 2566550014 PC2LD: 16 Vector__XXX
 SG_ PwrConv2TotalChargeGenerated : 96|32@1+ (100,0) [0|421108121500] "Ah" Vector__XXX
 SG_ PwrConv2TotalChargeConsumed : 64|32@1+ (100,0) [0|421108121500] "Ah" Vector__XXX
 SG_ PwrConv2TotalEnergyGenerated : 32|32@1+ (100,0) [0|421108121500] "Wh" Vector__XXX
 SG_ PwrConv2TotalEnergyConsumed : 0|32@1+ (100,0) [0|421108121500] "Wh" Vector__XXX

BO_ 2566549758 PC1LD: 16 Vector__XXX
 SG_ PwrConv1TotalChargeGenerated : 96|32@1+ (100,0) [0|421108121500] "Ah" Vector__XXX
 SG_ PwrConv1TotalChargeConsumed : 64|32@1+ (100,0) [0|421108121500] "Ah" Vector__XXX
 SG_ PwrConv1TotalEnergyGenerated : 32|32@1+ (100,0) [0|421108121500] "Wh" Vector__XXX
 SG_ PwrConv1TotalEnergyConsumed : 0|32@1+ (100,0) [0|421108121500] "Wh" Vector__XXX

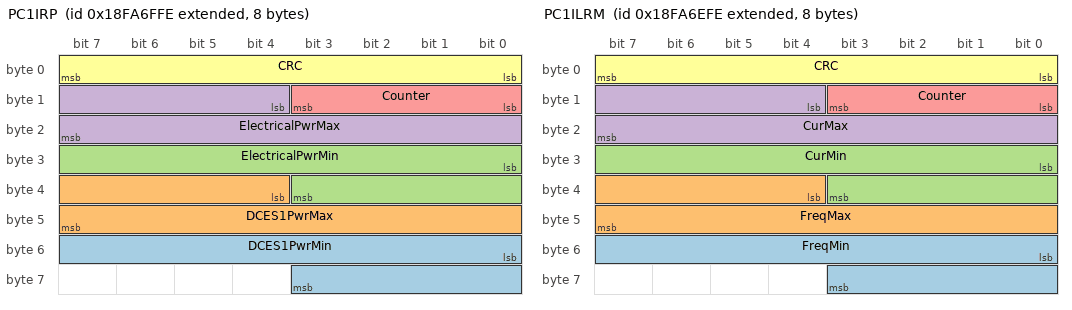
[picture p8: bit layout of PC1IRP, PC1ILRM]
BO_ 2566549502 PC1IRP: 8 Vector__XXX
 SG_ DCES1PwrMin : 48|12@1+ (0.0625,-125) [-125|125.9375] "%" Vector__XXX
 SG_ DCES1PwrMax : 36|12@1+ (0.0625,-125) [-125|125.9375] "%" Vector__XXX
 SG_ ElectricalPwrMin : 24|12@1+ (0.0625,-125) [-125|125.9375] "%" Vector__XXX
 SG_ ElectricalPwrMax : 12|12@1+ (0.0625,-125) [-125|125.9375] "%" Vector__XXX
 SG_ Counter : 8|4@1+ (1,0) [0|15] "" Vector__XXX
 SG_ CRC : 0|8@1+ (1,0) [0|255] "" Vector__XXX

BO_ 2566549246 PC1ILRM: 8 Vector__XXX
 SG_ FreqMin : 48|12@1+ (0.0625,-125) [-125|125.9375] "%" Vector__XXX
 SG_ FreqMax : 36|12@1+ (0.0625,-125) [-125|125.9375] "%" Vector__XXX
 SG_ CurMin : 24|12@1+ (0.0625,-125) [-125|125.9375] "%" Vector__XXX
 SG_ CurMax : 12|12@1+ (0.0625,-125) [-125|125.9375] "%" Vector__XXX
 SG_ Counter : 8|4@1+ (1,0) [0|15] "" Vector__XXX
 SG_ CRC : 0|8@1+ (1,0) [0|255] "" Vector__XXX

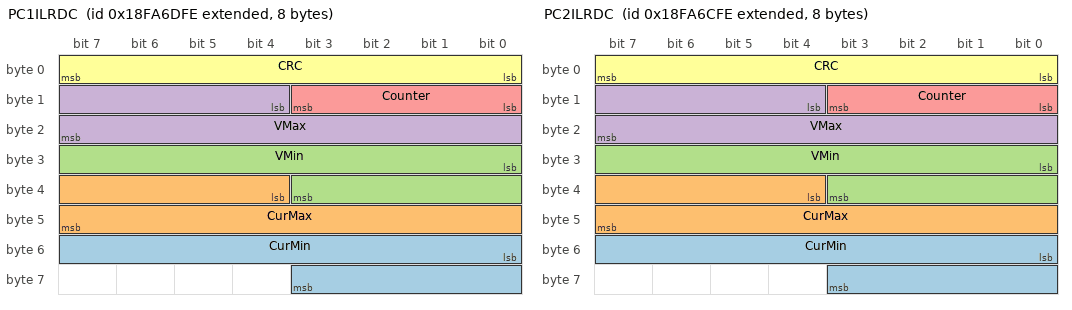
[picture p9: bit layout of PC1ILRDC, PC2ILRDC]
BO_ 2566548990 PC1ILRDC: 8 Vector__XXX
 SG_ CurMin : 48|12@1+ (0.0625,-125) [-125|125.9375] "%" Vector__XXX
 SG_ CurMax : 36|12@1+ (0.0625,-125) [-125|125.9375] "%" Vector__XXX
 SG_ VMin : 24|12@1+ (0.0625,-125) [-125|125.9375] "%" Vector__XXX
 SG_ VMax : 12|12@1+ (0.0625,-125) [-125|125.9375] "%" Vector__XXX
 SG_ Counter : 8|4@1+ (1,0) [0|15] "" Vector__XXX
 SG_ CRC : 0|8@1+ (1,0) [0|255] "" Vector__XXX

BO_ 2566548734 PC2ILRDC: 8 Vector__XXX
 SG_ CurMin : 48|12@1+ (0.0625,-125) [-125|125.9375] "%" Vector__XXX
 SG_ CurMax : 36|12@1+ (0.0625,-125) [-125|125.9375] "%" Vector__XXX
 SG_ VMin : 24|12@1+ (0.0625,-125) [-125|125.9375] "%" Vector__XXX
 SG_ VMax : 12|12@1+ (0.0625,-125) [-125|125.9375] "%" Vector__XXX
 SG_ Counter : 8|4@1+ (1,0) [0|15] "" Vector__XXX
 SG_ CRC : 0|8@1+ (1,0) [0|255] "" Vector__XXX

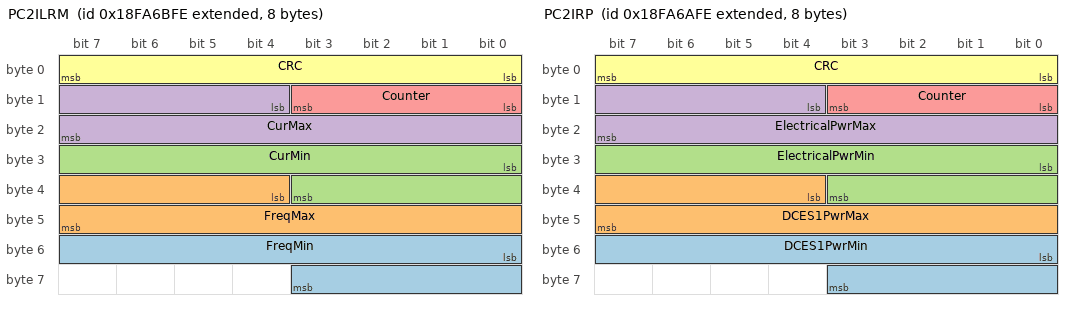
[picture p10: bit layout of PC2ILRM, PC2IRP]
BO_ 2566548478 PC2ILRM: 8 Vector__XXX
 SG_ FreqMin : 48|12@1+ (0.0625,-125) [-125|125.9375] "%" Vector__XXX
 SG_ FreqMax : 36|12@1+ (0.0625,-125) [-125|125.9375] "%" Vector__XXX
 SG_ CurMin : 24|12@1+ (0.0625,-125) [-125|125.9375] "%" Vector__XXX
 SG_ CurMax : 12|12@1+ (0.0625,-125) [-125|125.9375] "%" Vector__XXX
 SG_ Counter : 8|4@1+ (1,0) [0|15] "" Vector__XXX
 SG_ CRC : 0|8@1+ (1,0) [0|255] "" Vector__XXX

BO_ 2566548222 PC2IRP: 8 Vector__XXX
 SG_ DCES1PwrMin : 48|12@1+ (0.0625,-125) [-125|125.9375] "%" Vector__XXX
 SG_ DCES1PwrMax : 36|12@1+ (0.0625,-125) [-125|125.9375] "%" Vector__XXX
 SG_ ElectricalPwrMin : 24|12@1+ (0.0625,-125) [-125|125.9375] "%" Vector__XXX
 SG_ ElectricalPwrMax : 12|12@1+ (0.0625,-125) [-125|125.9375] "%" Vector__XXX
 SG_ Counter : 8|4@1+ (1,0) [0|15] "" Vector__XXX
 SG_ CRC : 0|8@1+ (1,0) [0|255] "" Vector__XXX

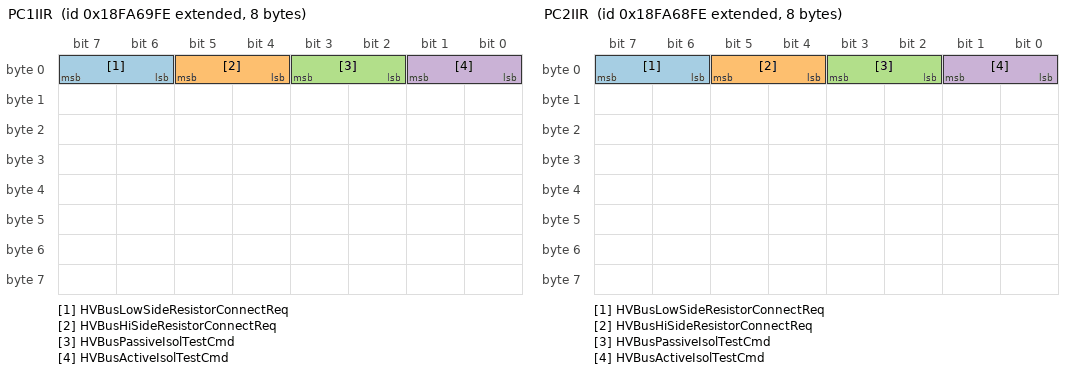
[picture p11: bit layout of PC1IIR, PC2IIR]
BO_ 2566547966 PC1IIR: 8 Vector__XXX
 SG_ HVBusLowSideResistorConnectReq : 6|2@1+ (1,0) [0|3] "" Vector__XXX
 SG_ HVBusHiSideResistorConnectReq : 4|2@1+ (1,0) [0|3] "" Vector__XXX
 SG_ HVBusPassiveIsolTestCmd : 2|2@1+ (1,0) [0|3] "" Vector__XXX
 SG_ HVBusActiveIsolTestCmd : 0|2@1+ (1,0) [0|3] "" Vector__XXX

BO_ 2566547710 PC2IIR: 8 Vector__XXX
 SG_ HVBusLowSideResistorConnectReq : 6|2@1+ (1,0) [0|3] "" Vector__XXX
 SG_ HVBusHiSideResistorConnectReq : 4|2@1+ (1,0) [0|3] "" Vector__XXX
 SG_ HVBusPassiveIsolTestCmd : 2|2@1+ (1,0) [0|3] "" Vector__XXX
 SG_ HVBusActiveIsolTestCmd : 0|2@1+ (1,0) [0|3] "" Vector__XXX

BO_ 2633656318 FR1: 8 Vector__XXX
 SG_ HydOilRes : 32|32@1+ (1000,0) [0|4211081215000] "Ohm" Vector__XXX
 SG_ EngOilRes : 0|32@1+ (1000,0) [0|4211081215000] "Ohm" Vector__XXX

BO_ 2566547198 ASI3: 8 Vector__XXX
 SG_ DEFQualityMalfunctionCount : 32|32@1+ (1,0) [0|4211081215] "" Vector__XXX
 SG_ DEFTank1EmptyCount : 0|32@1+ (1,0) [0|4211081215] "" Vector__XXX

BO_ 2566546942 ASI4: 8 Vector__XXX
 SG_ DEFFrozenCount : 32|32@1+ (1,0) [0|4211081215] "" Vector__XXX
 SG_ SCRMalfunctionCount : 0|32@1+ (1,0) [0|4211081215] "" Vector__XXX

BO_ 2566546686 ASI5: 8 Vector__XXX
 SG_ OneTotalEventCountWithNoDEFDel : 32|32@1+ (1,0) [0|4211081215] "" Vector__XXX
 SG_ OneSCRInHiTempCount : 0|32@1+ (1,0) [0|4211081215] "" Vector__XXX

BO_ 2365219838 LCMD2: 8 Vector__XXX
 SG_ TractorHazardLightsCmd : 2|2@1+ (1,0) [0|3] "" Vector__XXX
 SG_ Data2ReqCmd : 0|2@1+ (1,0) [0|3] "" Vector__XXX

BO_ 2566546174 LD2: 8 Vector__XXX
 SG_ TractorHazardLights : 0|2@1+ (1,0) [0|3] "" Vector__XXX

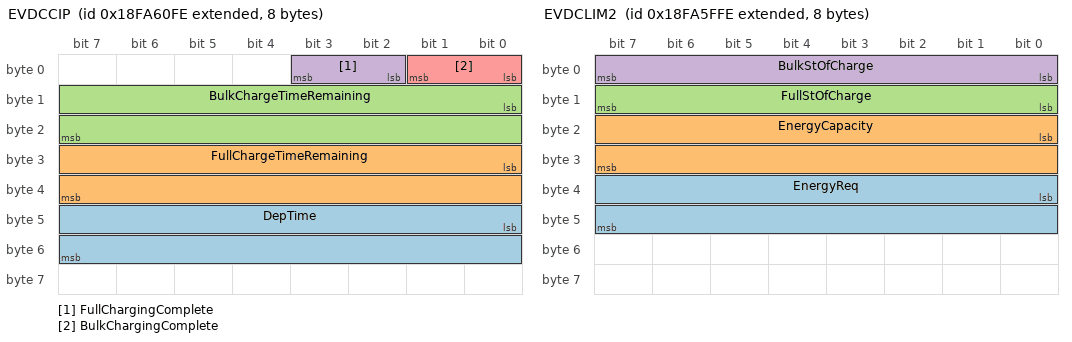
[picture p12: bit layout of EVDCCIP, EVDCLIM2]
BO_ 2566545662 EVDCCIP: 8 Vector__XXX
 SG_ DepTime : 40|16@1+ (10,0) [0|642550] "s" Vector__XXX
 SG_ FullChargeTimeRemaining : 24|16@1+ (10,0) [0|642550] "s" Vector__XXX
 SG_ BulkChargeTimeRemaining : 8|16@1+ (10,0) [0|642550] "s" Vector__XXX
 SG_ FullChargingComplete : 2|2@1+ (1,0) [0|3] "" Vector__XXX
 SG_ BulkChargingComplete : 0|2@1+ (1,0) [0|3] "" Vector__XXX

BO_ 2566545406 EVDCLIM2: 8 Vector__XXX
 SG_ EnergyReq : 32|16@1+ (1,0) [0|64255] "kWh" Vector__XXX
 SG_ EnergyCapacity : 16|16@1+ (1,0) [0|64255] "kWh" Vector__XXX
 SG_ FullStOfCharge : 8|8@1+ (0.5,0) [0|125] "%" Vector__XXX
 SG_ BulkStOfCharge : 0|8@1+ (0.5,0) [0|125] "%" Vector__XXX

BO_ 2566545150 EVCHGPROF: 8 Vector__XXX
 SG_ ProfileEntryStart : 0|32@1+ (1,0) [0|4211081215] "s" Vector__XXX
 SG_ ProfileEntryMaxPwr : 0|32@1+ (1,-2000000000) [-2000000000|2211081215] "W" Vector__XXX
 SG_ SelectedScheduleID : 0|16@1+ (1,0) [0|65535] "" Vector__XXX

BO_ 2566544894 EVSESCHED: 8 Vector__XXX
 SG_ EntryDur : 0|32@1+ (1,0) [0|4211081215] "s" Vector__XXX
 SG_ EntryStartTime : 0|32@1+ (1,0) [0|4211081215] "s" Vector__XXX
 SG_ EntryPwrMax : 0|32@1+ (1,-2000000000) [-2000000000|2211081215] "W" Vector__XXX
 SG_ PMaxScheduleId : 32|16@1+ (1,0) [0|65535] "" Vector__XXX
 SG_ ScheduleId : 16|16@1+ (1,0) [0|65535] "" Vector__XXX
 SG_ MaxScheduleIndex : 8|8@1+ (1,0) [0|250] "" Vector__XXX
 SG_ ScheduleIndex : 0|8@1+ (1,0) [0|250] "" Vector__XXX

BO_ 2566544638 EVSEDCLIM3: 8 Vector__XXX
 SG_ EnergyToBeDelivered : 0|24@1+ (0.001,0) [0|16449.535] "kWh" Vector__XXX

CM_ BO_ 2633669886 "High Voltage Energy Storage Pack 23 History
Historical data for High Voltage Energy Storage Pack 23.";
CM_ SG_ 2633669886 TotalEnergyOut "The cumulative energy which has flowed out of this High Voltage Energy Storage Pack instance over the lifetime of the battery pack. This parameter is the sum of the Energy out of this HVES instance. This value is reset when the pack is replaced. For ...";
CM_ SG_ 2633669886 TotalEnergyInput "The cumulative energy which has flowed into this High Voltage Energy Storage Pack instance over the lifetime of the battery pack. This parameter is the sum of the Energy into this HVES instance.
This value is reset when the pack is replaced. For ...";
CM_ SG_ 2633669886 TotalAccumulatedCharge "The total accumulated amp hours which have flowed through this High Voltage Energy Storage Pack instance.  This parameter is the sum of the absolute values of the Ampere hours into and out of this HVES instance.
This parameter is for one of ...";
CM_ SG_ 2633669886 TotalEnergyThroughput "The total energy throughput which has flowed through this High Voltage Energy Storage Pack instance.  This parameter is the sum of the absolute values of the Energy into and out of this HVES instance.
This parameter is for one of multiple packs in ...";
CM_ SG_ 2633669886 ContactorOpenUnderLoadCount "This signal represents the number of times the contactors inside this High Voltage Energy Storage Pack instance have opened while current is flowing through them.  The current level (that determines if an opening event will be counted) shall be ...";
CM_ SG_ 2633669886 StOfHealth "This signal represents the expected remaining \"Life\" of this High Voltage Energy Storage Pack instance, in percent.  Battery life is a manufacturer-specific measure of how well the energy storage system is functioning relative to its nominal (rated) ...";
CM_ BO_ 2566560766 "High Voltage Energy Storage Pack 22 Configuration
Configuration data for High Voltage Energy Storage Pack 22.  Note that configuration data should not dynamically change during vehicle operation.";
CM_ SG_ 2566560766 NomRatedCapacity "Per the HVES manufacturer, this is the manufacturer's nominal rated capacity of this instance of the energy storage system.  The rated capacity does not change over the life of the HVES.
This parameter is for one of multiple packs in an HVESS.  If ...";
CM_ SG_ 2566560766 CellMinVLmt "Per the HVES manufacturer, this is the minimum cell voltage for this High Voltage Energy Storage Pack instance operation.  Operating below this value may damage HVES hardware, or compromise HVES life.
This parameter is for one of multiple packs in ...";
CM_ SG_ 2566560766 CellMaxVLmt "Per the HVES manufacturer, this is the maximum cell voltage for this High Voltage Energy Storage Pack instance operation.  Operating above this value may damage HVES hardware, or compromise HVES life.
This parameter is for one of multiple packs in ...";
CM_ SG_ 2566560766 RecommendedMinOperatingTemp "Per the HVES manufacturer, this is the recommended minimum temperature for this High Voltage Energy Storage Pack instance operation.  Operating below this value may damage HVES hardware, or compromise HVES life.
This parameter is for one of ...";
CM_ SG_ 2566560766 RecommendedMaxOperatingTemp "Per the HVES manufacturer, this is the recommended maximum temperature for this High Voltage Energy Storage Pack instance operation.  Operating above this value may damage HVES hardware, or compromise HVES life.
This parameter is for one of ...";
CM_ SG_ 2566560766 RecommendedMaxStOfCharge "Per the HVES manufacturer, this is the recommended maximum state of charge for this High Voltage Energy Storage Pack instance operation.  Operating above this value may compromise HVES life.
This parameter is for one of multiple packs in an HVESS ...";
CM_ SG_ 2566560766 RecommendedMinStOfCharge "Per the HVES manufacturer, this is the recommended minimum state of charge for this High Voltage Energy Storage Pack instance operation.  Operating below this value may compromise HVES life.
This parameter is for one of multiple packs in an HVESS ...";
CM_ SG_ 2566560766 RecommendedMaxOperatingV "Per the HVES manufacturer, this is the maximum recommended voltage level for this High Voltage Energy Storage Pack instance operation.  Operating above this value may compromise HVES life.
This parameter is for one of multiple packs in an HVESS ...";
CM_ SG_ 2566560766 RecommendedMinOperatingV "Per the HVES manufacturer, this is the minimum recommended voltage level for this High Voltage Energy Storage Pack instance operation.  Operating below this value may compromise HVES life.
This parameter is for one of multiple packs in an HVESS ...";
CM_ SG_ 2566560766 NomV "Per the HVES manufacturer, this is the nominal operating voltage of this High Voltage Energy Storage Pack instance, e.g. “300V” or “600V”.
This parameter is for one of multiple packs in an HVESS.  If there is only one pack in the system, the HVESS ...";
CM_ BO_ 2633669374 "High Voltage Energy Storage Pack 22 History
Historical data for High Voltage Energy Storage Pack 22.";
CM_ SG_ 2633669374 TotalEnergyOut "The cumulative energy which has flowed out of this High Voltage Energy Storage Pack instance over the lifetime of the battery pack. This parameter is the sum of the Energy out of this HVES instance. This value is reset when the pack is replaced. For ...";
CM_ SG_ 2633669374 TotalEnergyInput "The cumulative energy which has flowed into this High Voltage Energy Storage Pack instance over the lifetime of the battery pack. This parameter is the sum of the Energy into this HVES instance.
This value is reset when the pack is replaced. For ...";
CM_ SG_ 2633669374 TotalAccumulatedCharge "The total accumulated amp hours which have flowed through this High Voltage Energy Storage Pack instance.  This parameter is the sum of the absolute values of the Ampere hours into and out of this HVES instance.
This parameter is for one of ...";
CM_ SG_ 2633669374 TotalEnergyThroughput "The total energy throughput which has flowed through this High Voltage Energy Storage Pack instance.  This parameter is the sum of the absolute values of the Energy into and out of this HVES instance.
This parameter is for one of multiple packs in ...";
CM_ SG_ 2633669374 ContactorOpenUnderLoadCount "This signal represents the number of times the contactors inside this High Voltage Energy Storage Pack instance have opened while current is flowing through them.  The current level (that determines if an opening event will be counted) shall be ...";
CM_ SG_ 2633669374 StOfHealth "This signal represents the expected remaining \"Life\" of this High Voltage Energy Storage Pack instance, in percent.  Battery life is a manufacturer-specific measure of how well the energy storage system is functioning relative to its nominal (rated) ...";
CM_ BO_ 2566560254 "High Voltage Energy Storage Pack 21 Configuration
Configuration data for High Voltage Energy Storage Pack 21.  Note that configuration data should not dynamically change during vehicle operation.";
CM_ SG_ 2566560254 NomRatedCapacity "Per the HVES manufacturer, this is the manufacturer's nominal rated capacity of this instance of the energy storage system.  The rated capacity does not change over the life of the HVES.
This parameter is for one of multiple packs in an HVESS.  If ...";
CM_ SG_ 2566560254 CellMinVLmt "Per the HVES manufacturer, this is the minimum cell voltage for this High Voltage Energy Storage Pack instance operation.  Operating below this value may damage HVES hardware, or compromise HVES life.
This parameter is for one of multiple packs in ...";
CM_ SG_ 2566560254 CellMaxVLmt "Per the HVES manufacturer, this is the maximum cell voltage for this High Voltage Energy Storage Pack instance operation.  Operating above this value may damage HVES hardware, or compromise HVES life.
This parameter is for one of multiple packs in ...";
CM_ SG_ 2566560254 RecommendedMinOperatingTemp "Per the HVES manufacturer, this is the recommended minimum temperature for this High Voltage Energy Storage Pack instance operation.  Operating below this value may damage HVES hardware, or compromise HVES life.
This parameter is for one of ...";
CM_ SG_ 2566560254 RecommendedMaxOperatingTemp "Per the HVES manufacturer, this is the recommended maximum temperature for this High Voltage Energy Storage Pack instance operation.  Operating above this value may damage HVES hardware, or compromise HVES life.
This parameter is for one of ...";
CM_ SG_ 2566560254 RecommendedMaxStOfCharge "Per the HVES manufacturer, this is the recommended maximum state of charge for this High Voltage Energy Storage Pack instance operation.  Operating above this value may compromise HVES life.
This parameter is for one of multiple packs in an HVESS ...";
CM_ SG_ 2566560254 RecommendedMinStOfCharge "Per the HVES manufacturer, this is the recommended minimum state of charge for this High Voltage Energy Storage Pack instance operation.  Operating below this value may compromise HVES life.
This parameter is for one of multiple packs in an HVESS ...";
CM_ SG_ 2566560254 RecommendedMaxOperatingV "Per the HVES manufacturer, this is the maximum recommended voltage level for this High Voltage Energy Storage Pack instance operation.  Operating above this value may compromise HVES life.
This parameter is for one of multiple packs in an HVESS ...";
CM_ SG_ 2566560254 RecommendedMinOperatingV "Per the HVES manufacturer, this is the minimum recommended voltage level for this High Voltage Energy Storage Pack instance operation.  Operating below this value may compromise HVES life.
This parameter is for one of multiple packs in an HVESS ...";
CM_ SG_ 2566560254 NomV "Per the HVES manufacturer, this is the nominal operating voltage of this High Voltage Energy Storage Pack instance, e.g. “300V” or “600V”.
This parameter is for one of multiple packs in an HVESS.  If there is only one pack in the system, the HVESS ...";
CM_ BO_ 2633668862 "High Voltage Energy Storage Pack 21 History
Historical data for High Voltage Energy Storage Pack 21.";
CM_ SG_ 2633668862 TotalEnergyOut "The cumulative energy which has flowed out of this High Voltage Energy Storage Pack instance over the lifetime of the battery pack. This parameter is the sum of the Energy out of this HVES instance. This value is reset when the pack is replaced. For ...";
CM_ SG_ 2633668862 TotalEnergyInput "The cumulative energy which has flowed into this High Voltage Energy Storage Pack instance over the lifetime of the battery pack. This parameter is the sum of the Energy into this HVES instance.
This value is reset when the pack is replaced. For ...";
CM_ SG_ 2633668862 TotalAccumulatedCharge "The total accumulated amp hours which have flowed through this High Voltage Energy Storage Pack instance.  This parameter is the sum of the absolute values of the Ampere hours into and out of this HVES instance.
This parameter is for one of ...";
CM_ SG_ 2633668862 TotalEnergyThroughput "The total energy throughput which has flowed through this High Voltage Energy Storage Pack instance.  This parameter is the sum of the absolute values of the Energy into and out of this HVES instance.
This parameter is for one of multiple packs in ...";
CM_ SG_ 2633668862 ContactorOpenUnderLoadCount "This signal represents the number of times the contactors inside this High Voltage Energy Storage Pack instance have opened while current is flowing through them.  The current level (that determines if an opening event will be counted) shall be ...";
CM_ SG_ 2633668862 StOfHealth "This signal represents the expected remaining \"Life\" of this High Voltage Energy Storage Pack instance, in percent.  Battery life is a manufacturer-specific measure of how well the energy storage system is functioning relative to its nominal (rated) ...";
CM_ BO_ 2566559742 "High Voltage Energy Storage Pack 20 Configuration
Configuration data for High Voltage Energy Storage Pack 20.  Note that configuration data should not dynamically change during vehicle operation.";
CM_ SG_ 2566559742 NomRatedCapacity "Per the HVES manufacturer, this is the manufacturer's nominal rated capacity of this instance of the energy storage system.  The rated capacity does not change over the life of the HVES.
This parameter is for one of multiple packs in an HVESS.  If ...";
CM_ SG_ 2566559742 CellMinVLmt "Per the HVES manufacturer, this is the minimum cell voltage for this High Voltage Energy Storage Pack instance operation.  Operating below this value may damage HVES hardware, or compromise HVES life.
This parameter is for one of multiple packs in ...";
CM_ SG_ 2566559742 CellMaxVLmt "Per the HVES manufacturer, this is the maximum cell voltage for this High Voltage Energy Storage Pack instance operation.  Operating above this value may damage HVES hardware, or compromise HVES life.
This parameter is for one of multiple packs in ...";
CM_ SG_ 2566559742 RecommendedMinOperatingTemp "Per the HVES manufacturer, this is the recommended minimum temperature for this High Voltage Energy Storage Pack instance operation.  Operating below this value may damage HVES hardware, or compromise HVES life.
This parameter is for one of ...";
CM_ SG_ 2566559742 RecommendedMaxOperatingTemp "Per the HVES manufacturer, this is the recommended maximum temperature for this High Voltage Energy Storage Pack instance operation.  Operating above this value may damage HVES hardware, or compromise HVES life.
This parameter is for one of ...";
CM_ SG_ 2566559742 RecommendedMaxStOfCharge "Per the HVES manufacturer, this is the recommended maximum state of charge for this High Voltage Energy Storage Pack instance operation.  Operating above this value may compromise HVES life.
This parameter is for one of multiple packs in an HVESS ...";
CM_ SG_ 2566559742 RecommendedMinStOfCharge "Per the HVES manufacturer, this is the recommended minimum state of charge for this High Voltage Energy Storage Pack instance operation.  Operating below this value may compromise HVES life.
This parameter is for one of multiple packs in an HVESS ...";
CM_ SG_ 2566559742 RecommendedMaxOperatingV "Per the HVES manufacturer, this is the maximum recommended voltage level for this High Voltage Energy Storage Pack instance operation.  Operating above this value may compromise HVES life.
This parameter is for one of multiple packs in an HVESS ...";
CM_ SG_ 2566559742 RecommendedMinOperatingV "Per the HVES manufacturer, this is the minimum recommended voltage level for this High Voltage Energy Storage Pack instance operation.  Operating below this value may compromise HVES life.
This parameter is for one of multiple packs in an HVESS ...";
CM_ SG_ 2566559742 NomV "Per the HVES manufacturer, this is the nominal operating voltage of this High Voltage Energy Storage Pack instance, e.g. “300V” or “600V”.
This parameter is for one of multiple packs in an HVESS.  If there is only one pack in the system, the HVESS ...";
CM_ BO_ 2633668350 "High Voltage Energy Storage Pack 20 History
Historical data for High Voltage Energy Storage Pack 20.";
CM_ SG_ 2633668350 TotalEnergyOut "The cumulative energy which has flowed out of this High Voltage Energy Storage Pack instance over the lifetime of the battery pack. This parameter is the sum of the Energy out of this HVES instance. This value is reset when the pack is replaced. For ...";
CM_ SG_ 2633668350 TotalEnergyInput "The cumulative energy which has flowed into this High Voltage Energy Storage Pack instance over the lifetime of the battery pack. This parameter is the sum of the Energy into this HVES instance.
This value is reset when the pack is replaced. For ...";
CM_ SG_ 2633668350 TotalAccumulatedCharge "The total accumulated amp hours which have flowed through this High Voltage Energy Storage Pack instance.  This parameter is the sum of the absolute values of the Ampere hours into and out of this HVES instance.
This parameter is for one of ...";
CM_ SG_ 2633668350 TotalEnergyThroughput "The total energy throughput which has flowed through this High Voltage Energy Storage Pack instance.  This parameter is the sum of the absolute values of the Energy into and out of this HVES instance.
This parameter is for one of multiple packs in ...";
CM_ SG_ 2633668350 ContactorOpenUnderLoadCount "This signal represents the number of times the contactors inside this High Voltage Energy Storage Pack instance have opened while current is flowing through them.  The current level (that determines if an opening event will be counted) shall be ...";
CM_ SG_ 2633668350 StOfHealth "This signal represents the expected remaining \"Life\" of this High Voltage Energy Storage Pack instance, in percent.  Battery life is a manufacturer-specific measure of how well the energy storage system is functioning relative to its nominal (rated) ...";
CM_ BO_ 2566559230 "High Voltage Energy Storage Pack 19 Configuration
Configuration data for High Voltage Energy Storage Pack 19.  Note that configuration data should not dynamically change during vehicle operation.";
CM_ SG_ 2566559230 NomRatedCapacity "Per the HVES manufacturer, this is the manufacturer's nominal rated capacity of this instance of the energy storage system.  The rated capacity does not change over the life of the HVES.
This parameter is for one of multiple packs in an HVESS.  If ...";
CM_ SG_ 2566559230 CellMinVLmt "Per the HVES manufacturer, this is the minimum cell voltage for this High Voltage Energy Storage Pack instance operation.  Operating below this value may damage HVES hardware, or compromise HVES life.
This parameter is for one of multiple packs in ...";
CM_ SG_ 2566559230 CellMaxVLmt "Per the HVES manufacturer, this is the maximum cell voltage for this High Voltage Energy Storage Pack instance operation.  Operating above this value may damage HVES hardware, or compromise HVES life.
This parameter is for one of multiple packs in ...";
CM_ SG_ 2566559230 RecommendedMinOperatingTemp "Per the HVES manufacturer, this is the recommended minimum temperature for this High Voltage Energy Storage Pack instance operation.  Operating below this value may damage HVES hardware, or compromise HVES life.
This parameter is for one of ...";
CM_ SG_ 2566559230 RecommendedMaxOperatingTemp "Per the HVES manufacturer, this is the recommended maximum temperature for this High Voltage Energy Storage Pack instance operation.  Operating above this value may damage HVES hardware, or compromise HVES life.
This parameter is for one of ...";
CM_ SG_ 2566559230 RecommendedMaxStOfCharge "Per the HVES manufacturer, this is the recommended maximum state of charge for this High Voltage Energy Storage Pack instance operation.  Operating above this value may compromise HVES life.
This parameter is for one of multiple packs in an HVESS ...";
CM_ SG_ 2566559230 RecommendedMinStOfCharge "Per the HVES manufacturer, this is the recommended minimum state of charge for this High Voltage Energy Storage Pack instance operation.  Operating below this value may compromise HVES life.
This parameter is for one of multiple packs in an HVESS ...";
CM_ SG_ 2566559230 RecommendedMaxOperatingV "Per the HVES manufacturer, this is the maximum recommended voltage level for this High Voltage Energy Storage Pack instance operation.  Operating above this value may compromise HVES life.
This parameter is for one of multiple packs in an HVESS ...";
CM_ SG_ 2566559230 RecommendedMinOperatingV "Per the HVES manufacturer, this is the minimum recommended voltage level for this High Voltage Energy Storage Pack instance operation.  Operating below this value may compromise HVES life.
This parameter is for one of multiple packs in an HVESS ...";
CM_ SG_ 2566559230 NomV "Per the HVES manufacturer, this is the nominal operating voltage of this High Voltage Energy Storage Pack instance, e.g. “300V” or “600V”.
This parameter is for one of multiple packs in an HVESS.  If there is only one pack in the system, the HVESS ...";
CM_ BO_ 2633667838 "High Voltage Energy Storage Pack 19 History
Historical data for High Voltage Energy Storage Pack 19.";
CM_ SG_ 2633667838 TotalEnergyOut "The cumulative energy which has flowed out of this High Voltage Energy Storage Pack instance over the lifetime of the battery pack. This parameter is the sum of the Energy out of this HVES instance. This value is reset when the pack is replaced. For ...";
CM_ SG_ 2633667838 TotalEnergyInput "The cumulative energy which has flowed into this High Voltage Energy Storage Pack instance over the lifetime of the battery pack. This parameter is the sum of the Energy into this HVES instance.
This value is reset when the pack is replaced. For ...";
CM_ SG_ 2633667838 TotalAccumulatedCharge "The total accumulated amp hours which have flowed through this High Voltage Energy Storage Pack instance.  This parameter is the sum of the absolute values of the Ampere hours into and out of this HVES instance.
This parameter is for one of ...";
CM_ SG_ 2633667838 TotalEnergyThroughput "The total energy throughput which has flowed through this High Voltage Energy Storage Pack instance.  This parameter is the sum of the absolute values of the Energy into and out of this HVES instance.
This parameter is for one of multiple packs in ...";
CM_ SG_ 2633667838 ContactorOpenUnderLoadCount "This signal represents the number of times the contactors inside this High Voltage Energy Storage Pack instance have opened while current is flowing through them.  The current level (that determines if an opening event will be counted) shall be ...";
CM_ SG_ 2633667838 StOfHealth "This signal represents the expected remaining \"Life\" of this High Voltage Energy Storage Pack instance, in percent.  Battery life is a manufacturer-specific measure of how well the energy storage system is functioning relative to its nominal (rated) ...";
CM_ BO_ 2566558718 "High Voltage Energy Storage Pack 18 Configuration
Configuration data for High Voltage Energy Storage Pack 18.  Note that configuration data should not dynamically change during vehicle operation.";
CM_ SG_ 2566558718 NomRatedCapacity "Per the HVES manufacturer, this is the manufacturer's nominal rated capacity of this instance of the energy storage system.  The rated capacity does not change over the life of the HVES.
This parameter is for one of multiple packs in an HVESS.  If ...";
CM_ SG_ 2566558718 CellMinVLmt "Per the HVES manufacturer, this is the minimum cell voltage for this High Voltage Energy Storage Pack instance operation.  Operating below this value may damage HVES hardware, or compromise HVES life.
This parameter is for one of multiple packs in ...";
CM_ SG_ 2566558718 CellMaxVLmt "Per the HVES manufacturer, this is the maximum cell voltage for this High Voltage Energy Storage Pack instance operation.  Operating above this value may damage HVES hardware, or compromise HVES life.
This parameter is for one of multiple packs in ...";
CM_ SG_ 2566558718 RecommendedMinOperatingTemp "Per the HVES manufacturer, this is the recommended minimum temperature for this High Voltage Energy Storage Pack instance operation.  Operating below this value may damage HVES hardware, or compromise HVES life.
This parameter is for one of ...";
CM_ SG_ 2566558718 RecommendedMaxOperatingTemp "Per the HVES manufacturer, this is the recommended maximum temperature for this High Voltage Energy Storage Pack instance operation.  Operating above this value may damage HVES hardware, or compromise HVES life.
This parameter is for one of ...";
CM_ SG_ 2566558718 RecommendedMaxStOfCharge "Per the HVES manufacturer, this is the recommended maximum state of charge for this High Voltage Energy Storage Pack instance operation.  Operating above this value may compromise HVES life.
This parameter is for one of multiple packs in an HVESS ...";
CM_ SG_ 2566558718 RecommendedMinStOfCharge "Per the HVES manufacturer, this is the recommended minimum state of charge for this High Voltage Energy Storage Pack instance operation.  Operating below this value may compromise HVES life.
This parameter is for one of multiple packs in an HVESS ...";
CM_ SG_ 2566558718 RecommendedMaxOperatingV "Per the HVES manufacturer, this is the maximum recommended voltage level for this High Voltage Energy Storage Pack instance operation.  Operating above this value may compromise HVES life.
This parameter is for one of multiple packs in an HVESS ...";
CM_ SG_ 2566558718 RecommendedMinOperatingV "Per the HVES manufacturer, this is the minimum recommended voltage level for this High Voltage Energy Storage Pack instance operation.  Operating below this value may compromise HVES life.
This parameter is for one of multiple packs in an HVESS ...";
CM_ SG_ 2566558718 NomV "Per the HVES manufacturer, this is the nominal operating voltage of this High Voltage Energy Storage Pack instance, e.g. “300V” or “600V”.
This parameter is for one of multiple packs in an HVESS.  If there is only one pack in the system, the HVESS ...";
CM_ BO_ 2633667326 "High Voltage Energy Storage Pack 18 History
Historical data for High Voltage Energy Storage Pack 18.";
CM_ SG_ 2633667326 TotalEnergyOut "The cumulative energy which has flowed out of this High Voltage Energy Storage Pack instance over the lifetime of the battery pack. This parameter is the sum of the Energy out of this HVES instance. This value is reset when the pack is replaced. For ...";
CM_ SG_ 2633667326 TotalEnergyInput "The cumulative energy which has flowed into this High Voltage Energy Storage Pack instance over the lifetime of the battery pack. This parameter is the sum of the Energy into this HVES instance.
This value is reset when the pack is replaced. For ...";
CM_ SG_ 2633667326 TotalAccumulatedCharge "The total accumulated amp hours which have flowed through this High Voltage Energy Storage Pack instance.  This parameter is the sum of the absolute values of the Ampere hours into and out of this HVES instance.
This parameter is for one of ...";
CM_ SG_ 2633667326 TotalEnergyThroughput "The total energy throughput which has flowed through this High Voltage Energy Storage Pack instance.  This parameter is the sum of the absolute values of the Energy into and out of this HVES instance.
This parameter is for one of multiple packs in ...";
CM_ SG_ 2633667326 ContactorOpenUnderLoadCount "This signal represents the number of times the contactors inside this High Voltage Energy Storage Pack instance have opened while current is flowing through them.  The current level (that determines if an opening event will be counted) shall be ...";
CM_ SG_ 2633667326 StOfHealth "This signal represents the expected remaining \"Life\" of this High Voltage Energy Storage Pack instance, in percent.  Battery life is a manufacturer-specific measure of how well the energy storage system is functioning relative to its nominal (rated) ...";
CM_ BO_ 2566558206 "High Voltage Energy Storage Pack 17 Configuration
Configuration data for High Voltage Energy Storage Pack 17.  Note that configuration data should not dynamically change during vehicle operation.";
CM_ SG_ 2566558206 NomRatedCapacity "Per the HVES manufacturer, this is the manufacturer's nominal rated capacity of this instance of the energy storage system.  The rated capacity does not change over the life of the HVES.
This parameter is for one of multiple packs in an HVESS.  If ...";
CM_ SG_ 2566558206 CellMinVLmt "Per the HVES manufacturer, this is the minimum cell voltage for this High Voltage Energy Storage Pack instance operation.  Operating below this value may damage HVES hardware, or compromise HVES life.
This parameter is for one of multiple packs in ...";
CM_ SG_ 2566558206 CellMaxVLmt "Per the HVES manufacturer, this is the maximum cell voltage for this High Voltage Energy Storage Pack instance operation.  Operating above this value may damage HVES hardware, or compromise HVES life.
This parameter is for one of multiple packs in ...";
CM_ SG_ 2566558206 RecommendedMinOperatingTemp "Per the HVES manufacturer, this is the recommended minimum temperature for this High Voltage Energy Storage Pack instance operation.  Operating below this value may damage HVES hardware, or compromise HVES life.
This parameter is for one of ...";
CM_ SG_ 2566558206 RecommendedMaxOperatingTemp "Per the HVES manufacturer, this is the recommended maximum temperature for this High Voltage Energy Storage Pack instance operation.  Operating above this value may damage HVES hardware, or compromise HVES life.
This parameter is for one of ...";
CM_ SG_ 2566558206 RecommendedMaxStOfCharge "Per the HVES manufacturer, this is the recommended maximum state of charge for this High Voltage Energy Storage Pack instance operation.  Operating above this value may compromise HVES life.
This parameter is for one of multiple packs in an HVESS ...";
CM_ SG_ 2566558206 RecommendedMinStOfCharge "Per the HVES manufacturer, this is the recommended minimum state of charge for this High Voltage Energy Storage Pack instance operation.  Operating below this value may compromise HVES life.
This parameter is for one of multiple packs in an HVESS ...";
CM_ SG_ 2566558206 RecommendedMaxOperatingV "Per the HVES manufacturer, this is the maximum recommended voltage level for this High Voltage Energy Storage Pack instance operation.  Operating above this value may compromise HVES life.
This parameter is for one of multiple packs in an HVESS ...";
CM_ SG_ 2566558206 RecommendedMinOperatingV "Per the HVES manufacturer, this is the minimum recommended voltage level for this High Voltage Energy Storage Pack instance operation.  Operating below this value may compromise HVES life.
This parameter is for one of multiple packs in an HVESS ...";
CM_ SG_ 2566558206 NomV "Per the HVES manufacturer, this is the nominal operating voltage of this High Voltage Energy Storage Pack instance, e.g. “300V” or “600V”.
This parameter is for one of multiple packs in an HVESS.  If there is only one pack in the system, the HVESS ...";
CM_ BO_ 2633666814 "High Voltage Energy Storage Pack 17 History
Historical data for High Voltage Energy Storage Pack 17.";
CM_ SG_ 2633666814 TotalEnergyOut "The cumulative energy which has flowed out of this High Voltage Energy Storage Pack instance over the lifetime of the battery pack. This parameter is the sum of the Energy out of this HVES instance. This value is reset when the pack is replaced. For ...";
CM_ SG_ 2633666814 TotalEnergyInput "The cumulative energy which has flowed into this High Voltage Energy Storage Pack instance over the lifetime of the battery pack. This parameter is the sum of the Energy into this HVES instance.
This value is reset when the pack is replaced. For ...";
CM_ SG_ 2633666814 TotalAccumulatedCharge "The total accumulated amp hours which have flowed through this High Voltage Energy Storage Pack instance.  This parameter is the sum of the absolute values of the Ampere hours into and out of this HVES instance.
This parameter is for one of ...";
CM_ SG_ 2633666814 TotalEnergyThroughput "The total energy throughput which has flowed through this High Voltage Energy Storage Pack instance.  This parameter is the sum of the absolute values of the Energy into and out of this HVES instance.
This parameter is for one of multiple packs in ...";
CM_ SG_ 2633666814 ContactorOpenUnderLoadCount "This signal represents the number of times the contactors inside this High Voltage Energy Storage Pack instance have opened while current is flowing through them.  The current level (that determines if an opening event will be counted) shall be ...";
CM_ SG_ 2633666814 StOfHealth "This signal represents the expected remaining \"Life\" of this High Voltage Energy Storage Pack instance, in percent.  Battery life is a manufacturer-specific measure of how well the energy storage system is functioning relative to its nominal (rated) ...";
CM_ BO_ 2566557694 "High Voltage Energy Storage Pack 16 Configuration
Configuration data for High Voltage Energy Storage Pack 16.  Note that configuration data should not dynamically change during vehicle operation.";
CM_ SG_ 2566557694 NomRatedCapacity "Per the HVES manufacturer, this is the manufacturer's nominal rated capacity of this instance of the energy storage system.  The rated capacity does not change over the life of the HVES.
This parameter is for one of multiple packs in an HVESS.  If ...";
CM_ SG_ 2566557694 CellMinVLmt "Per the HVES manufacturer, this is the minimum cell voltage for this High Voltage Energy Storage Pack instance operation.  Operating below this value may damage HVES hardware, or compromise HVES life.
This parameter is for one of multiple packs in ...";
CM_ SG_ 2566557694 CellMaxVLmt "Per the HVES manufacturer, this is the maximum cell voltage for this High Voltage Energy Storage Pack instance operation.  Operating above this value may damage HVES hardware, or compromise HVES life.
This parameter is for one of multiple packs in ...";
CM_ SG_ 2566557694 RecommendedMinOperatingTemp "Per the HVES manufacturer, this is the recommended minimum temperature for this High Voltage Energy Storage Pack instance operation.  Operating below this value may damage HVES hardware, or compromise HVES life.
This parameter is for one of ...";
CM_ SG_ 2566557694 RecommendedMaxOperatingTemp "Per the HVES manufacturer, this is the recommended maximum temperature for this High Voltage Energy Storage Pack instance operation.  Operating above this value may damage HVES hardware, or compromise HVES life.
This parameter is for one of ...";
CM_ SG_ 2566557694 RecommendedMaxStOfCharge "Per the HVES manufacturer, this is the recommended maximum state of charge for this High Voltage Energy Storage Pack instance operation.  Operating above this value may compromise HVES life.
This parameter is for one of multiple packs in an HVESS ...";
CM_ SG_ 2566557694 RecommendedMinStOfCharge "Per the HVES manufacturer, this is the recommended minimum state of charge for this High Voltage Energy Storage Pack instance operation.  Operating below this value may compromise HVES life.
This parameter is for one of multiple packs in an HVESS ...";
CM_ SG_ 2566557694 RecommendedMaxOperatingV "Per the HVES manufacturer, this is the maximum recommended voltage level for this High Voltage Energy Storage Pack instance operation.  Operating above this value may compromise HVES life.
This parameter is for one of multiple packs in an HVESS ...";
CM_ SG_ 2566557694 RecommendedMinOperatingV "Per the HVES manufacturer, this is the minimum recommended voltage level for this High Voltage Energy Storage Pack instance operation.  Operating below this value may compromise HVES life.
This parameter is for one of multiple packs in an HVESS ...";
CM_ SG_ 2566557694 NomV "Per the HVES manufacturer, this is the nominal operating voltage of this High Voltage Energy Storage Pack instance, e.g. “300V” or “600V”.
This parameter is for one of multiple packs in an HVESS.  If there is only one pack in the system, the HVESS ...";
CM_ BO_ 2633666302 "High Voltage Energy Storage Pack 16 History
Historical data for High Voltage Energy Storage Pack 16.";
CM_ SG_ 2633666302 TotalEnergyOut "The cumulative energy which has flowed out of this High Voltage Energy Storage Pack instance over the lifetime of the battery pack. This parameter is the sum of the Energy out of this HVES instance. This value is reset when the pack is replaced. For ...";
CM_ SG_ 2633666302 TotalEnergyInput "The cumulative energy which has flowed into this High Voltage Energy Storage Pack instance over the lifetime of the battery pack. This parameter is the sum of the Energy into this HVES instance.
This value is reset when the pack is replaced. For ...";
CM_ SG_ 2633666302 TotalAccumulatedCharge "The total accumulated amp hours which have flowed through this High Voltage Energy Storage Pack instance.  This parameter is the sum of the absolute values of the Ampere hours into and out of this HVES instance.
This parameter is for one of ...";
CM_ SG_ 2633666302 TotalEnergyThroughput "The total energy throughput which has flowed through this High Voltage Energy Storage Pack instance.  This parameter is the sum of the absolute values of the Energy into and out of this HVES instance.
This parameter is for one of multiple packs in ...";
CM_ SG_ 2633666302 ContactorOpenUnderLoadCount "This signal represents the number of times the contactors inside this High Voltage Energy Storage Pack instance have opened while current is flowing through them.  The current level (that determines if an opening event will be counted) shall be ...";
CM_ SG_ 2633666302 StOfHealth "This signal represents the expected remaining \"Life\" of this High Voltage Energy Storage Pack instance, in percent.  Battery life is a manufacturer-specific measure of how well the energy storage system is functioning relative to its nominal (rated) ...";
CM_ BO_ 2566557182 "High Voltage Energy Storage Pack 15 Configuration
Configuration data for High Voltage Energy Storage Pack 15.  Note that configuration data should not dynamically change during vehicle operation.";
CM_ SG_ 2566557182 NomRatedCapacity "Per the HVES manufacturer, this is the manufacturer's nominal rated capacity of this instance of the energy storage system.  The rated capacity does not change over the life of the HVES.
This parameter is for one of multiple packs in an HVESS.  If ...";
CM_ SG_ 2566557182 CellMinVLmt "Per the HVES manufacturer, this is the minimum cell voltage for this High Voltage Energy Storage Pack instance operation.  Operating below this value may damage HVES hardware, or compromise HVES life.
This parameter is for one of multiple packs in ...";
CM_ SG_ 2566557182 CellMaxVLmt "Per the HVES manufacturer, this is the maximum cell voltage for this High Voltage Energy Storage Pack instance operation.  Operating above this value may damage HVES hardware, or compromise HVES life.
This parameter is for one of multiple packs in ...";
CM_ SG_ 2566557182 RecommendedMinOperatingTemp "Per the HVES manufacturer, this is the recommended minimum temperature for this High Voltage Energy Storage Pack instance operation.  Operating below this value may damage HVES hardware, or compromise HVES life.
This parameter is for one of ...";
CM_ SG_ 2566557182 RecommendedMaxOperatingTemp "Per the HVES manufacturer, this is the recommended maximum temperature for this High Voltage Energy Storage Pack instance operation.  Operating above this value may damage HVES hardware, or compromise HVES life.
This parameter is for one of ...";
CM_ SG_ 2566557182 RecommendedMaxStOfCharge "Per the HVES manufacturer, this is the recommended maximum state of charge for this High Voltage Energy Storage Pack instance operation.  Operating above this value may compromise HVES life.
This parameter is for one of multiple packs in an HVESS ...";
CM_ SG_ 2566557182 RecommendedMinStOfCharge "Per the HVES manufacturer, this is the recommended minimum state of charge for this High Voltage Energy Storage Pack instance operation.  Operating below this value may compromise HVES life.
This parameter is for one of multiple packs in an HVESS ...";
CM_ SG_ 2566557182 RecommendedMaxOperatingV "Per the HVES manufacturer, this is the maximum recommended voltage level for this High Voltage Energy Storage Pack instance operation.  Operating above this value may compromise HVES life.
This parameter is for one of multiple packs in an HVESS ...";
CM_ SG_ 2566557182 RecommendedMinOperatingV "Per the HVES manufacturer, this is the minimum recommended voltage level for this High Voltage Energy Storage Pack instance operation.  Operating below this value may compromise HVES life.
This parameter is for one of multiple packs in an HVESS ...";
CM_ SG_ 2566557182 NomV "Per the HVES manufacturer, this is the nominal operating voltage of this High Voltage Energy Storage Pack instance, e.g. “300V” or “600V”.
This parameter is for one of multiple packs in an HVESS.  If there is only one pack in the system, the HVESS ...";
CM_ BO_ 2633665790 "High Voltage Energy Storage Pack 15 History
Historical data for High Voltage Energy Storage Pack 15.";
CM_ SG_ 2633665790 TotalEnergyOut "The cumulative energy which has flowed out of this High Voltage Energy Storage Pack instance over the lifetime of the battery pack. This parameter is the sum of the Energy out of this HVES instance. This value is reset when the pack is replaced. For ...";
CM_ SG_ 2633665790 TotalEnergyInput "The cumulative energy which has flowed into this High Voltage Energy Storage Pack instance over the lifetime of the battery pack. This parameter is the sum of the Energy into this HVES instance.
This value is reset when the pack is replaced. For ...";
CM_ SG_ 2633665790 TotalAccumulatedCharge "The total accumulated amp hours which have flowed through this High Voltage Energy Storage Pack instance.  This parameter is the sum of the absolute values of the Ampere hours into and out of this HVES instance.
This parameter is for one of ...";
CM_ SG_ 2633665790 TotalEnergyThroughput "The total energy throughput which has flowed through this High Voltage Energy Storage Pack instance.  This parameter is the sum of the absolute values of the Energy into and out of this HVES instance.
This parameter is for one of multiple packs in ...";
CM_ SG_ 2633665790 ContactorOpenUnderLoadCount "This signal represents the number of times the contactors inside this High Voltage Energy Storage Pack instance have opened while current is flowing through them.  The current level (that determines if an opening event will be counted) shall be ...";
CM_ SG_ 2633665790 StOfHealth "This signal represents the expected remaining \"Life\" of this High Voltage Energy Storage Pack instance, in percent.  Battery life is a manufacturer-specific measure of how well the energy storage system is functioning relative to its nominal (rated) ...";
CM_ BO_ 2566556670 "High Voltage Energy Storage Pack 14 Configuration
Configuration data for High Voltage Energy Storage Pack 14.  Note that configuration data should not dynamically change during vehicle operation.";
CM_ SG_ 2566556670 NomRatedCapacity "Per the HVES manufacturer, this is the manufacturer's nominal rated capacity of this instance of the energy storage system.  The rated capacity does not change over the life of the HVES.
This parameter is for one of multiple packs in an HVESS.  If ...";
CM_ SG_ 2566556670 CellMinVLmt "Per the HVES manufacturer, this is the minimum cell voltage for this High Voltage Energy Storage Pack instance operation.  Operating below this value may damage HVES hardware, or compromise HVES life.
This parameter is for one of multiple packs in ...";
CM_ SG_ 2566556670 CellMaxVLmt "Per the HVES manufacturer, this is the maximum cell voltage for this High Voltage Energy Storage Pack instance operation.  Operating above this value may damage HVES hardware, or compromise HVES life.
This parameter is for one of multiple packs in ...";
CM_ SG_ 2566556670 RecommendedMinOperatingTemp "Per the HVES manufacturer, this is the recommended minimum temperature for this High Voltage Energy Storage Pack instance operation.  Operating below this value may damage HVES hardware, or compromise HVES life.
This parameter is for one of ...";
CM_ SG_ 2566556670 RecommendedMaxOperatingTemp "Per the HVES manufacturer, this is the recommended maximum temperature for this High Voltage Energy Storage Pack instance operation.  Operating above this value may damage HVES hardware, or compromise HVES life.
This parameter is for one of ...";
CM_ SG_ 2566556670 RecommendedMaxStOfCharge "Per the HVES manufacturer, this is the recommended maximum state of charge for this High Voltage Energy Storage Pack instance operation.  Operating above this value may compromise HVES life.
This parameter is for one of multiple packs in an HVESS ...";
CM_ SG_ 2566556670 RecommendedMinStOfCharge "Per the HVES manufacturer, this is the recommended minimum state of charge for this High Voltage Energy Storage Pack instance operation.  Operating below this value may compromise HVES life.
This parameter is for one of multiple packs in an HVESS ...";
CM_ SG_ 2566556670 RecommendedMaxOperatingV "Per the HVES manufacturer, this is the maximum recommended voltage level for this High Voltage Energy Storage Pack instance operation.  Operating above this value may compromise HVES life.
This parameter is for one of multiple packs in an HVESS ...";
CM_ SG_ 2566556670 RecommendedMinOperatingV "Per the HVES manufacturer, this is the minimum recommended voltage level for this High Voltage Energy Storage Pack instance operation.  Operating below this value may compromise HVES life.
This parameter is for one of multiple packs in an HVESS ...";
CM_ SG_ 2566556670 NomV "Per the HVES manufacturer, this is the nominal operating voltage of this High Voltage Energy Storage Pack instance, e.g. “300V” or “600V”.
This parameter is for one of multiple packs in an HVESS.  If there is only one pack in the system, the HVESS ...";
CM_ BO_ 2633665278 "High Voltage Energy Storage Pack 14 History
Historical data for High Voltage Energy Storage Pack 14.";
CM_ SG_ 2633665278 TotalEnergyOut "The cumulative energy which has flowed out of this High Voltage Energy Storage Pack instance over the lifetime of the battery pack. This parameter is the sum of the Energy out of this HVES instance. This value is reset when the pack is replaced. For ...";
CM_ SG_ 2633665278 TotalEnergyInput "The cumulative energy which has flowed into this High Voltage Energy Storage Pack instance over the lifetime of the battery pack. This parameter is the sum of the Energy into this HVES instance.
This value is reset when the pack is replaced. For ...";
CM_ SG_ 2633665278 TotalAccumulatedCharge "The total accumulated amp hours which have flowed through this High Voltage Energy Storage Pack instance.  This parameter is the sum of the absolute values of the Ampere hours into and out of this HVES instance.
This parameter is for one of ...";
CM_ SG_ 2633665278 TotalEnergyThroughput "The total energy throughput which has flowed through this High Voltage Energy Storage Pack instance.  This parameter is the sum of the absolute values of the Energy into and out of this HVES instance.
This parameter is for one of multiple packs in ...";
CM_ SG_ 2633665278 ContactorOpenUnderLoadCount "This signal represents the number of times the contactors inside this High Voltage Energy Storage Pack instance have opened while current is flowing through them.  The current level (that determines if an opening event will be counted) shall be ...";
CM_ SG_ 2633665278 StOfHealth "This signal represents the expected remaining \"Life\" of this High Voltage Energy Storage Pack instance, in percent.  Battery life is a manufacturer-specific measure of how well the energy storage system is functioning relative to its nominal (rated) ...";
CM_ BO_ 2566556158 "High Voltage Energy Storage Pack 13 Configuration
Configuration data for High Voltage Energy Storage Pack 13.  Note that configuration data should not dynamically change during vehicle operation.";
CM_ SG_ 2566556158 NomRatedCapacity "Per the HVES manufacturer, this is the manufacturer's nominal rated capacity of this instance of the energy storage system.  The rated capacity does not change over the life of the HVES.
This parameter is for one of multiple packs in an HVESS.  If ...";
CM_ SG_ 2566556158 CellMinVLmt "Per the HVES manufacturer, this is the minimum cell voltage for this High Voltage Energy Storage Pack instance operation.  Operating below this value may damage HVES hardware, or compromise HVES life.
This parameter is for one of multiple packs in ...";
CM_ SG_ 2566556158 CellMaxVLmt "Per the HVES manufacturer, this is the maximum cell voltage for this High Voltage Energy Storage Pack instance operation.  Operating above this value may damage HVES hardware, or compromise HVES life.
This parameter is for one of multiple packs in ...";
CM_ SG_ 2566556158 RecommendedMinOperatingTemp "Per the HVES manufacturer, this is the recommended minimum temperature for this High Voltage Energy Storage Pack instance operation.  Operating below this value may damage HVES hardware, or compromise HVES life.
This parameter is for one of ...";
CM_ SG_ 2566556158 RecommendedMaxOperatingTemp "Per the HVES manufacturer, this is the recommended maximum temperature for this High Voltage Energy Storage Pack instance operation.  Operating above this value may damage HVES hardware, or compromise HVES life.
This parameter is for one of ...";
CM_ SG_ 2566556158 RecommendedMaxStOfCharge "Per the HVES manufacturer, this is the recommended maximum state of charge for this High Voltage Energy Storage Pack instance operation.  Operating above this value may compromise HVES life.
This parameter is for one of multiple packs in an HVESS ...";
CM_ SG_ 2566556158 RecommendedMinStOfCharge "Per the HVES manufacturer, this is the recommended minimum state of charge for this High Voltage Energy Storage Pack instance operation.  Operating below this value may compromise HVES life.
This parameter is for one of multiple packs in an HVESS ...";
CM_ SG_ 2566556158 RecommendedMaxOperatingV "Per the HVES manufacturer, this is the maximum recommended voltage level for this High Voltage Energy Storage Pack instance operation.  Operating above this value may compromise HVES life.
This parameter is for one of multiple packs in an HVESS ...";
CM_ SG_ 2566556158 RecommendedMinOperatingV "Per the HVES manufacturer, this is the minimum recommended voltage level for this High Voltage Energy Storage Pack instance operation.  Operating below this value may compromise HVES life.
This parameter is for one of multiple packs in an HVESS ...";
CM_ SG_ 2566556158 NomV "Per the HVES manufacturer, this is the nominal operating voltage of this High Voltage Energy Storage Pack instance, e.g. “300V” or “600V”.
This parameter is for one of multiple packs in an HVESS.  If there is only one pack in the system, the HVESS ...";
CM_ BO_ 2633664766 "High Voltage Energy Storage Pack 13 History
Historical data for High Voltage Energy Storage Pack 13.";
CM_ SG_ 2633664766 TotalEnergyOut "The cumulative energy which has flowed out of this High Voltage Energy Storage Pack instance over the lifetime of the battery pack. This parameter is the sum of the Energy out of this HVES instance. This value is reset when the pack is replaced. For ...";
CM_ SG_ 2633664766 TotalEnergyInput "The cumulative energy which has flowed into this High Voltage Energy Storage Pack instance over the lifetime of the battery pack. This parameter is the sum of the Energy into this HVES instance.
This value is reset when the pack is replaced. For ...";
CM_ SG_ 2633664766 TotalAccumulatedCharge "The total accumulated amp hours which have flowed through this High Voltage Energy Storage Pack instance.  This parameter is the sum of the absolute values of the Ampere hours into and out of this HVES instance.
This parameter is for one of ...";
CM_ SG_ 2633664766 TotalEnergyThroughput "The total energy throughput which has flowed through this High Voltage Energy Storage Pack instance.  This parameter is the sum of the absolute values of the Energy into and out of this HVES instance.
This parameter is for one of multiple packs in ...";
CM_ SG_ 2633664766 ContactorOpenUnderLoadCount "This signal represents the number of times the contactors inside this High Voltage Energy Storage Pack instance have opened while current is flowing through them.  The current level (that determines if an opening event will be counted) shall be ...";
CM_ SG_ 2633664766 StOfHealth "This signal represents the expected remaining \"Life\" of this High Voltage Energy Storage Pack instance, in percent.  Battery life is a manufacturer-specific measure of how well the energy storage system is functioning relative to its nominal (rated) ...";
CM_ BO_ 2566555646 "High Voltage Energy Storage Pack 12 Configuration
Configuration data for High Voltage Energy Storage Pack 12.  Note that configuration data should not dynamically change during vehicle operation.";
CM_ SG_ 2566555646 NomRatedCapacity "Per the HVES manufacturer, this is the manufacturer's nominal rated capacity of this instance of the energy storage system.  The rated capacity does not change over the life of the HVES.
This parameter is for one of multiple packs in an HVESS.  If ...";
CM_ SG_ 2566555646 CellMinVLmt "Per the HVES manufacturer, this is the minimum cell voltage for this High Voltage Energy Storage Pack instance operation.  Operating below this value may damage HVES hardware, or compromise HVES life.
This parameter is for one of multiple packs in ...";
CM_ SG_ 2566555646 CellMaxVLmt "Per the HVES manufacturer, this is the maximum cell voltage for this High Voltage Energy Storage Pack instance operation.  Operating above this value may damage HVES hardware, or compromise HVES life.
This parameter is for one of multiple packs in ...";
CM_ SG_ 2566555646 RecommendedMinOperatingTemp "Per the HVES manufacturer, this is the recommended minimum temperature for this High Voltage Energy Storage Pack instance operation.  Operating below this value may damage HVES hardware, or compromise HVES life.
This parameter is for one of ...";
CM_ SG_ 2566555646 RecommendedMaxOperatingTemp "Per the HVES manufacturer, this is the recommended maximum temperature for this High Voltage Energy Storage Pack instance operation.  Operating above this value may damage HVES hardware, or compromise HVES life.
This parameter is for one of ...";
CM_ SG_ 2566555646 RecommendedMaxStOfCharge "Per the HVES manufacturer, this is the recommended maximum state of charge for this High Voltage Energy Storage Pack instance operation.  Operating above this value may compromise HVES life.
This parameter is for one of multiple packs in an HVESS ...";
CM_ SG_ 2566555646 RecommendedMinStOfCharge "Per the HVES manufacturer, this is the recommended minimum state of charge for this High Voltage Energy Storage Pack instance operation.  Operating below this value may compromise HVES life.
This parameter is for one of multiple packs in an HVESS ...";
CM_ SG_ 2566555646 RecommendedMaxOperatingV "Per the HVES manufacturer, this is the maximum recommended voltage level for this High Voltage Energy Storage Pack instance operation.  Operating above this value may compromise HVES life.
This parameter is for one of multiple packs in an HVESS ...";
CM_ SG_ 2566555646 RecommendedMinOperatingV "Per the HVES manufacturer, this is the minimum recommended voltage level for this High Voltage Energy Storage Pack instance operation.  Operating below this value may compromise HVES life.
This parameter is for one of multiple packs in an HVESS ...";
CM_ SG_ 2566555646 NomV "Per the HVES manufacturer, this is the nominal operating voltage of this High Voltage Energy Storage Pack instance, e.g. “300V” or “600V”.
This parameter is for one of multiple packs in an HVESS.  If there is only one pack in the system, the HVESS ...";
CM_ BO_ 2633664254 "High Voltage Energy Storage Pack 12 History
Historical data for High Voltage Energy Storage Pack 12.";
CM_ SG_ 2633664254 TotalEnergyOut "The cumulative energy which has flowed out of this High Voltage Energy Storage Pack instance over the lifetime of the battery pack. This parameter is the sum of the Energy out of this HVES instance. This value is reset when the pack is replaced. For ...";
CM_ SG_ 2633664254 TotalEnergyInput "The cumulative energy which has flowed into this High Voltage Energy Storage Pack instance over the lifetime of the battery pack. This parameter is the sum of the Energy into this HVES instance.
This value is reset when the pack is replaced. For ...";
CM_ SG_ 2633664254 TotalAccumulatedCharge "The total accumulated amp hours which have flowed through this High Voltage Energy Storage Pack instance.  This parameter is the sum of the absolute values of the Ampere hours into and out of this HVES instance.
This parameter is for one of ...";
CM_ SG_ 2633664254 TotalEnergyThroughput "The total energy throughput which has flowed through this High Voltage Energy Storage Pack instance.  This parameter is the sum of the absolute values of the Energy into and out of this HVES instance.
This parameter is for one of multiple packs in ...";
CM_ SG_ 2633664254 ContactorOpenUnderLoadCount "This signal represents the number of times the contactors inside this High Voltage Energy Storage Pack instance have opened while current is flowing through them.  The current level (that determines if an opening event will be counted) shall be ...";
CM_ SG_ 2633664254 StOfHealth "This signal represents the expected remaining \"Life\" of this High Voltage Energy Storage Pack instance, in percent.  Battery life is a manufacturer-specific measure of how well the energy storage system is functioning relative to its nominal (rated) ...";
CM_ BO_ 2566555134 "High Voltage Energy Storage Pack 11 Configuration
Configuration data for High Voltage Energy Storage Pack 11.  Note that configuration data should not dynamically change during vehicle operation.";
CM_ SG_ 2566555134 NomRatedCapacity "Per the HVES manufacturer, this is the manufacturer's nominal rated capacity of this instance of the energy storage system.  The rated capacity does not change over the life of the HVES.
This parameter is for one of multiple packs in an HVESS.  If ...";
CM_ SG_ 2566555134 CellMinVLmt "Per the HVES manufacturer, this is the minimum cell voltage for this High Voltage Energy Storage Pack instance operation.  Operating below this value may damage HVES hardware, or compromise HVES life.
This parameter is for one of multiple packs in ...";
CM_ SG_ 2566555134 CellMaxVLmt "Per the HVES manufacturer, this is the maximum cell voltage for this High Voltage Energy Storage Pack instance operation.  Operating above this value may damage HVES hardware, or compromise HVES life.
This parameter is for one of multiple packs in ...";
CM_ SG_ 2566555134 RecommendedMinOperatingTemp "Per the HVES manufacturer, this is the recommended minimum temperature for this High Voltage Energy Storage Pack instance operation.  Operating below this value may damage HVES hardware, or compromise HVES life.
This parameter is for one of ...";
CM_ SG_ 2566555134 RecommendedMaxOperatingTemp "Per the HVES manufacturer, this is the recommended maximum temperature for this High Voltage Energy Storage Pack instance operation.  Operating above this value may damage HVES hardware, or compromise HVES life.
This parameter is for one of ...";
CM_ SG_ 2566555134 RecommendedMaxStOfCharge "Per the HVES manufacturer, this is the recommended maximum state of charge for this High Voltage Energy Storage Pack instance operation.  Operating above this value may compromise HVES life.
This parameter is for one of multiple packs in an HVESS ...";
CM_ SG_ 2566555134 RecommendedMinStOfCharge "Per the HVES manufacturer, this is the recommended minimum state of charge for this High Voltage Energy Storage Pack instance operation.  Operating below this value may compromise HVES life.
This parameter is for one of multiple packs in an HVESS ...";
CM_ SG_ 2566555134 RecommendedMaxOperatingV "Per the HVES manufacturer, this is the maximum recommended voltage level for this High Voltage Energy Storage Pack instance operation.  Operating above this value may compromise HVES life.
This parameter is for one of multiple packs in an HVESS ...";
CM_ SG_ 2566555134 RecommendedMinOperatingV "Per the HVES manufacturer, this is the minimum recommended voltage level for this High Voltage Energy Storage Pack instance operation.  Operating below this value may compromise HVES life.
This parameter is for one of multiple packs in an HVESS ...";
CM_ SG_ 2566555134 NomV "Per the HVES manufacturer, this is the nominal operating voltage of this High Voltage Energy Storage Pack instance, e.g. “300V” or “600V”.
This parameter is for one of multiple packs in an HVESS.  If there is only one pack in the system, the HVESS ...";
CM_ BO_ 2633663742 "High Voltage Energy Storage Pack 11 History
Historical data for High Voltage Energy Storage Pack 11.";
CM_ SG_ 2633663742 TotalEnergyOut "The cumulative energy which has flowed out of this High Voltage Energy Storage Pack instance over the lifetime of the battery pack. This parameter is the sum of the Energy out of this HVES instance. This value is reset when the pack is replaced. For ...";
CM_ SG_ 2633663742 TotalEnergyInput "The cumulative energy which has flowed into this High Voltage Energy Storage Pack instance over the lifetime of the battery pack. This parameter is the sum of the Energy into this HVES instance.
This value is reset when the pack is replaced. For ...";
CM_ SG_ 2633663742 TotalAccumulatedCharge "The total accumulated amp hours which have flowed through this High Voltage Energy Storage Pack instance.  This parameter is the sum of the absolute values of the Ampere hours into and out of this HVES instance.
This parameter is for one of ...";
CM_ SG_ 2633663742 TotalEnergyThroughput "The total energy throughput which has flowed through this High Voltage Energy Storage Pack instance.  This parameter is the sum of the absolute values of the Energy into and out of this HVES instance.
This parameter is for one of multiple packs in ...";
CM_ SG_ 2633663742 ContactorOpenUnderLoadCount "This signal represents the number of times the contactors inside this High Voltage Energy Storage Pack instance have opened while current is flowing through them.  The current level (that determines if an opening event will be counted) shall be ...";
CM_ SG_ 2633663742 StOfHealth "This signal represents the expected remaining \"Life\" of this High Voltage Energy Storage Pack instance, in percent.  Battery life is a manufacturer-specific measure of how well the energy storage system is functioning relative to its nominal (rated) ...";
CM_ BO_ 2566554622 "Electrified Accessory Engine Coolant Pump Status
The status of electrified Accessory: Engine Coolant Pump.

See PGN 19456 for the corresponding command message.";
CM_ SG_ 2566554622 ElectricPumpOperatingStatus "Indicates the operating status of the Engine Coolant Electric Pump system or component.
This parameter is used to inform other devices that this system or component is no longer performing to its operational capacity and that reduced, or no flow, ...";
CM_ SG_ 2566554622 ElectricPumpServiceInd "Indicates that service is required for the Engine Coolant Electric Pump system or component.
An active indication may convey a need for component replacement or periodic service. The Engine Coolant Electric Pump Controller Status Reason (SPN 20177) ...";
CM_ SG_ 2566554622 ElectricPumpPwr "Calculated electrical power consumed by the Engine Coolant Electric Pump.";
CM_ SG_ 2566554622 ElectricPumpCtrlTemp "A temperature measured and reported by the device.
It may be used for direct or remote (e.g. by another controller) control of the pump. For example, this may be the temperature of the fluid flowing through the pump, or some other temperature ...";
CM_ SG_ 2566554622 ElectricPumpMotorSpd "Motor Speed of the Engine Coolant Electric Pump.";
CM_ SG_ 2566554622 ElectricPumpCtrlCmdStatus "Indicates the source of the speed command to the Engine Electric Coolant Pump system or component.
00b = Internal Command
01b = External Command
10b = Default Command
11b = Not Available
Note:
00b is communicated when the controller is ...";
CM_ SG_ 2566554622 ElectricPumpCtrlStatusReason "Provides the reason code describing the unique failure of the Engine Coolant Electric Pump system or component.
If a detailed reason code is not used by the supporting application, or this reason code is Not Available, the Engine Coolant Electric ...";
CM_ SG_ 2566554622 ElectricPumpEnableStatus "Enable and direction status of the Engine Coolant Electric Pump system or component.

00b = Motor Off
01b = Motor On - Normal, Forward, or Default Direction
10b = Motor On - Reverse Direction
11b = Not available";
CM_ BO_ 2566554366 "Transformer Temperatures
Transformer Temperature Status Message";
CM_ SG_ 2566554366 TwoPhaseWTemp "Indicates the temperature of the Phase W in transformer 2.

Note:  Manufacturer-specific phase nomenclature (e.g. 1,2,3 or a,b,c) may differ.";
CM_ SG_ 2566554366 TwoPhaseVTemp "Indicates the temperature of the Phase V in transformer 2.

Note:  Manufacturer-specific phase nomenclature (e.g. 1,2,3 or a,b,c) may differ.";
CM_ SG_ 2566554366 TwoPhaseUTemp "Indicates the temperature of the Phase U in transformer 2.

Note:  Manufacturer-specific phase nomenclature (e.g. 1,2,3 or a,b,c) may differ.";
CM_ SG_ 2566554366 OnePhaseWTemp "Indicates the temperature of the Phase W in transformer 1.

Note:  Manufacturer-specific phase nomenclature (e.g. 1,2,3 or a,b,c) may differ.";
CM_ SG_ 2566554366 OnePhaseVTemp "Indicates the temperature of the Phase V in transformer 1.

Note:  Manufacturer-specific phase nomenclature (e.g. 1,2,3 or a,b,c) may differ.";
CM_ SG_ 2566554366 OnePhaseUTemp "Indicates the temperature of the Phase U in this transformer instance.

Note:  Manufacturer-specific phase nomenclature (e.g. 1,2,3 or a,b,c) may differ.";
CM_ BO_ 2365227518 "Power Converter Totals 1
Power Converter Overall Current and Temperature Status Message";
CM_ SG_ 2365227518 TwoPwrConvPwrModuleSwTemp "Indicates the overall power module switch (e.g. transistor, IGBT or MOSFET) temperature in Inverter 2.";
CM_ SG_ 2365227518 OnePwrConvPwrModuleSwTemp "Indicates the overall power module switch (e.g. transistor, IGBT or MOSFET) temperature in Inverter 1.";
CM_ SG_ 2365227518 TwoPwrConvACCurOut "The AC current being produced by Inverter 2.";
CM_ SG_ 2365227518 OnePwrConvACCurOut "The AC current being produced by Inverter 1.";
CM_ BO_ 2365227262 "Power Converter 2 Power Module Switch Power Supply Voltage
Power Converter 2 Power Module Switch Power Supply Status Message";
CM_ SG_ 2365227262 ConvPhaseWPwrModuleSwPwrSupplyV "Indicates the voltage being supplied to the Phase W power module switch (e.g. transistor, IGBT or MOSFET) in Inverter 2.

Note:  Manufacturer-specific phase nomenclature (e.g. 1,2,3 or a,b,c) may differ.";
CM_ SG_ 2365227262 ConvPhaseVPwrModuleSwPwrSupplyV "Indicates the voltage being supplied to the Phase V power module switch (e.g. transistor, IGBT or MOSFET) in Inverter 2.

Note:  Manufacturer-specific phase nomenclature (e.g. 1,2,3 or a,b,c) may differ.";
CM_ SG_ 2365227262 ConvPhaseUPwrModuleSwPwrSupplyV "Indicates the voltage being supplied to the Phase U power module switch (e.g. transistor, IGBT or MOSFET) in Inverter 2.

Note:  Manufacturer-specific phase nomenclature (e.g. 1,2,3 or a,b,c) may differ.";
CM_ BO_ 2365227006 "Power Converter 1 Power Module Switch Power Supply Voltage
Power Converter 1 Power Module Switch Power Supply Status Message";
CM_ SG_ 2365227006 ConvPhaseWPwrModuleSwPwrSupplyV "Indicates the voltage being supplied to the Phase W power module switch (e.g. transistor, IGBT or MOSFET) in Inverter 1.

Note:  Manufacturer-specific phase nomenclature (e.g. 1,2,3 or a,b,c) may differ.";
CM_ SG_ 2365227006 ConvPhaseVPwrModuleSwPwrSupplyV "Indicates the voltage being supplied to the Phase V power module switch (e.g. transistor, IGBT or MOSFET) in Inverter 1.

Note:  Manufacturer-specific phase nomenclature (e.g. 1,2,3 or a,b,c) may differ.";
CM_ SG_ 2365227006 ConvPhaseUPwrModuleSwPwrSupplyV "Indicates the voltage being supplied to the Phase U power module switch (e.g. transistor, IGBT or MOSFET) in Inverter 1.

Note:  Manufacturer-specific phase nomenclature (e.g. 1,2,3 or a,b,c) may differ.";
CM_ BO_ 2566553342 "Power Converter Power Module Switch Temperatures
Power Converter Power Module Switch Temperatures Status Message";
CM_ SG_ 2566553342 TwoPwrConvPhaseWPwrModuleSwTemp "Indicates the temperature of the Phase W power module switch (e.g. transistor, IGBT or MOSFET) in Inverter 2.

Note:  Manufacturer-specific phase nomenclature (e.g. 1,2,3 or a,b,c) may differ.";
CM_ SG_ 2566553342 TwoPwrConvPhaseVPwrModuleSwTemp "Indicates the temperature of the Phase V power module switch (e.g. transistor, IGBT or MOSFET) in Inverter 2.

Note:  Manufacturer-specific phase nomenclature (e.g. 1,2,3 or a,b,c) may differ.";
CM_ SG_ 2566553342 TwoPwrConvPhaseUPwrModuleSwTemp "Indicates the temperature of the Phase U power module switch (e.g. transistor, IGBT or MOSFET) in Inverter 2.

Note:  Manufacturer-specific phase nomenclature (e.g. 1,2,3 or a,b,c) may differ.";
CM_ SG_ 2566553342 OnePwrConvPhaseWPwrModuleSwTemp "Indicates the temperature of the Phase W power module switch (e.g. transistor, IGBT or MOSFET) in Inverter 1.

Note:  Manufacturer-specific phase nomenclature (e.g. 1,2,3 or a,b,c) may differ.";
CM_ SG_ 2566553342 OnePwrConvPhaseVPwrModuleSwTemp "Indicates the temperature of the Phase V power module switch (e.g. transistor, IGBT or MOSFET) in Inverter 1.

Note:  Manufacturer-specific phase nomenclature (e.g. 1,2,3 or a,b,c) may differ.";
CM_ SG_ 2566553342 OnePwrConvPhaseUPwrModuleSwTemp "Indicates the temperature of the Phase U power module switch (e.g. transistor, IGBT or MOSFET) in this inverter instance.

Note:  Manufacturer-specific phase nomenclature (e.g. 1,2,3 or a,b,c) may differ.";
CM_ BO_ 2365226494 "Power Converter 2 Phase Voltage
Power Converter 2 Phase Voltage Status Message";
CM_ SG_ 2365226494 PwrConvPhaseWV "Voltage output of phase W of Inverter 2.  Note:  Manufacturer-specific phase nomenclature (e.g. 1,2,3 or a,b,c) may differ.";
CM_ SG_ 2365226494 PwrConvPhaseVV "Voltage output of phase V of Inverter 2.  Note:  Manufacturer-specific phase nomenclature (e.g. 1,2,3 or a,b,c) may differ.";
CM_ SG_ 2365226494 PwrConvPhaseUV "Voltage output of phase U of Inverter 2.  Note:  Manufacturer-specific phase nomenclature (e.g. 1,2,3 or a,b,c) may differ.";
CM_ BO_ 2365226238 "Power Converter 1 Phase Voltage
Power Converter 1 Phase Voltage Status Message";
CM_ SG_ 2365226238 PwrConvPhaseWV "Voltage output of phase W of Inverter 1.  Note:  Manufacturer-specific phase nomenclature (e.g. 1,2,3 or a,b,c) may differ.";
CM_ SG_ 2365226238 PwrConvPhaseVV "Voltage output of phase V of Inverter 1.  Note:  Manufacturer-specific phase nomenclature (e.g. 1,2,3 or a,b,c) may differ.";
CM_ SG_ 2365226238 PwrConvPhaseUV "Voltage output of phase U of Inverter 1.  Note:  Manufacturer-specific phase nomenclature (e.g. 1,2,3 or a,b,c) may differ.";
CM_ BO_ 2365225982 "Power Converter 2 Phase Current
Power Converter 2 Phase Current Status Message";
CM_ SG_ 2365225982 PwrConvPhaseWCur "Current output of phase W of Inverter 2.  Note:  Manufacturer-specific phase nomenclature (e.g. 1,2,3 or a,b,c) may differ.";
CM_ SG_ 2365225982 PwrConvPhaseVCur "Current output of phase V of Inverter 2.  Note:  Manufacturer-specific phase nomenclature (e.g. 1,2,3 or a,b,c) may differ.";
CM_ SG_ 2365225982 PwrConvPhaseUCur "Current output of phase U of Inverter 2.  Note:  Manufacturer-specific phase nomenclature (e.g. 1,2,3 or a,b,c) may differ.";
CM_ BO_ 2365225726 "Power Converter 1 Phase Current
Power Converter 1 Phase Current Status Message";
CM_ SG_ 2365225726 PwrConvPhaseWCur "Current output of phase W of Inverter 1.  Note:  Manufacturer-specific phase nomenclature (e.g. 1,2,3 or a,b,c) may differ.";
CM_ SG_ 2365225726 PwrConvPhaseVCur "Current output of phase V of Inverter 1.  Note:  Manufacturer-specific phase nomenclature (e.g. 1,2,3 or a,b,c) may differ.";
CM_ SG_ 2365225726 PwrConvPhaseUCur "Current output of phase U of Inverter 1.  Note:  Manufacturer-specific phase nomenclature (e.g. 1,2,3 or a,b,c) may differ.";
CM_ BO_ 2365225470 "Power Converter 1 Reference 1
The current and frequency reference values from this inverter.";
CM_ SG_ 2365225470 Pwr "This value is used for converting power in percent to units of kW.  It is applicable to both electrical and electrical power.
(Value in kW) = (Percent Value)/(100%) * (Reference Power)
For example, if this parameter has a value of 400 kW and the ...";
CM_ SG_ 2365225470 Freq "This value is used for converting Frequency in percent to units of Hz.
Value in Hz = (Percent Value)/(100%) * (Reference Frequency)
For example, if this parameter has a value of 8192 Hz and the percent value is equal to 75%, then the value in Hz ...";
CM_ SG_ 2365225470 Cur "This value is used for converting torque in percent to units of Nm.
Value in Nm = (Percent Value)/(100%) * (Reference Torque)
For example, if this parameter has a value of 4000 Nm and the percent value is equal to 75%, then the value in Nm will be ...";
CM_ SG_ 2365225470 Counter "The message counter is used to detect situations where the transmitting ECU malfunction repeats the same frame all the time. The receiver of the information may use the counter parameter to detect this situation. The transmitting device will ...";
CM_ SG_ 2365225470 CRC "The CRC is defined as follows:
• Length: 8 bits
• Polynomial: x^8+x^5+x^3+x^2+x+1
• Initial Value: FFh
• Input Data Reflection: Not reflected
• Result Data Reflection: Not reflected
• XOR value: FFh
SAE makes no claim of the functional safety ...";
CM_ BO_ 2365225214 "Power Converter 1 Reference 2
The electrical reference values from this inverter.";
CM_ SG_ 2365225214 V "This value is used for converting inverter voltage in percent to units of Volts (RMS or DC).
(Value in Volts) = (Percent Value)/(100%) * (Reference Voltage)
For example, if this parameter has a value of 400 V and the percent value is equal to 75%, ...";
CM_ SG_ 2365225214 Cur "This value is used for converting inverter current in percent to units of Amps (RMS or DC).
(Value in Amps) = (Percent Value)/(100%) * (Reference Current)
For example, if this parameter has a value of 200 A and the percent value is equal to 75%, ...";
CM_ SG_ 2365225214 Counter "The message counter is used to detect situations where the transmitting ECU malfunction repeats the same frame all the time. The receiver of the information may use the counter parameter to detect this situation. The transmitting device will ...";
CM_ SG_ 2365225214 CRC "The CRC is defined as follows:
• Length: 8 bits
• Polynomial: x^8+x^5+x^3+x^2+x+1
• Initial Value: FFh
• Input Data Reflection: Not reflected
• Result Data Reflection: Not reflected
• XOR value: FFh
SAE makes no claim of the functional safety ...";
CM_ BO_ 2566551550 "Power Converter 1 Temperature
Inverter Temperature Status Message";
CM_ SG_ 2566551550 Four "The exact location of this temperature can be defined by the manufacturer.  It is intended to be located somewhere on the Power Converter.";
CM_ SG_ 2566551550 Three "The exact location of this temperature can be defined by the manufacturer.  It is intended to be located somewhere on the Power Converter.";
CM_ SG_ 2566551550 Two "The exact location of this temperature can be defined by the manufacturer.  It is intended to be located somewhere on the Power Converter.";
CM_ SG_ 2566551550 One "The exact location of this temperature can be defined by the manufacturer.  It is intended to be located somewhere on the Power Converter.";
CM_ BO_ 2566551294 "Power Converter 2 Temperature
Inverter Temperature Status Message";
CM_ SG_ 2566551294 Four "The exact location of this temperature can be defined by the manufacturer.  It is intended to be located somewhere on the Power Converter.";
CM_ SG_ 2566551294 Three "The exact location of this temperature can be defined by the manufacturer.  It is intended to be located somewhere on the Power Converter.";
CM_ SG_ 2566551294 Two "The exact location of this temperature can be defined by the manufacturer.  It is intended to be located somewhere on the Power Converter.";
CM_ SG_ 2566551294 One "The exact location of this temperature can be defined by the manufacturer.  It is intended to be located somewhere on the Power Converter.";
CM_ BO_ 2365224446 "Power Converter 2 Reference 2
The electrical reference values from this inverter.";
CM_ SG_ 2365224446 V "This value is used for converting inverter voltage in percent to units of Volts (RMS or DC).
(Value in Volts) = (Percent Value)/(100%) * (Reference Voltage)
For example, if this parameter has a value of 400 V and the percent value is equal to 75%, ...";
CM_ SG_ 2365224446 Cur "This value is used for converting inverter current in percent to units of Amps (RMS or DC).
(Value in Amps) = (Percent Value)/(100%) * (Reference Current)
For example, if this parameter has a value of 200 A and the percent value is equal to 75%, ...";
CM_ SG_ 2365224446 Counter "The message counter is used to detect situations where the transmitting ECU malfunction repeats the same frame all the time. The receiver of the information may use the counter parameter to detect this situation. The transmitting device will ...";
CM_ SG_ 2365224446 CRC "The CRC is defined as follows:
• Length: 8 bits
• Polynomial: x^8+x^5+x^3+x^2+x+1
• Initial Value: FFh
• Input Data Reflection: Not reflected
• Result Data Reflection: Not reflected
• XOR value: FFh
SAE makes no claim of the functional safety ...";
CM_ BO_ 2365224190 "Power Converter 2 Reference 1
The current and frequency reference values from this inverter.";
CM_ SG_ 2365224190 Pwr "This value is used for converting power in percent to units of kW.  It is applicable to both electrical and electrical power.
(Value in kW) = (Percent Value)/(100%) * (Reference Power)
For example, if this parameter has a value of 400 kW and the ...";
CM_ SG_ 2365224190 Freq "This value is used for converting Frequency in percent to units of Hz.
Value in Hz = (Percent Value)/(100%) * (Reference Frequency)
For example, if this parameter has a value of 8192 Hz and the percent value is equal to 75%, then the value in Hz ...";
CM_ SG_ 2365224190 Cur "This value is used for converting torque in percent to units of Nm.
Value in Nm = (Percent Value)/(100%) * (Reference Torque)
For example, if this parameter has a value of 4000 Nm and the percent value is equal to 75%, then the value in Nm will be ...";
CM_ SG_ 2365224190 Counter "The message counter is used to detect situations where the transmitting ECU malfunction repeats the same frame all the time. The receiver of the information may use the counter parameter to detect this situation. The transmitting device will ...";
CM_ SG_ 2365224190 CRC "The CRC is defined as follows:
• Length: 8 bits
• Polynomial: x^8+x^5+x^3+x^2+x+1
• Initial Value: FFh
• Input Data Reflection: Not reflected
• Result Data Reflection: Not reflected
• XOR value: FFh
SAE makes no claim of the functional safety ...";
CM_ BO_ 2566550526 "Power Converter 1 Active Power Limits
Sent by this Power Converter instance and contains the current operating conditions of the Power Converter.  This message would be received by a controller application that is responsible for controlling this ...";
CM_ SG_ 2566550526 CurLimDueToMachineCharac "Output current is being limited due to SPN 20694(Power Converter 1 Current) approaching or exceeding a system design characteristic.  For example, for permanent magnet machines, this would be in the field weakening area.
00b = No current limit for ...";
CM_ SG_ 2566550526 PLedDueToActiveCurRateLmt "Output power is being limited due to exceeding internally defined current rate limit(s) or SPN 20482 (Power Converter 1 Rate Limits Request Absolute Current Rate Limit).
00b = No power limit for this reason
01b = Power limited for this reason
10b ...";
CM_ SG_ 2566550526 PLedDueToFaultCondition "Output power is being limited due to an fault condition that requires a current limitation to prevent further damage (e.g. “limp home mode”).  For example, this could be in case of temperature sensor defects.  Typically, this parameter would be ...";
CM_ SG_ 2566550526 PLedDueToTemp "Output power is being limited due to one or more temperature(s), see SPNs 9059 and 10220 through 10222 (Temperature 1-4) approaching or exceeding internally defined limit(s).
00b = No power limit for this reason
01b = Power limited for this reason
 ...";
CM_ SG_ 2566550526 PLedDueToInvTemp "Output power is being limited due to one or more inverter temperature(s), see SPNs 10216 through 10219 (Power Converter 1 Temperature 1-4) approaching or exceeding internally defined limit(s).
00b = No power limit for this reason
01b = Power ...";
CM_ SG_ 2566550526 PLedDueToFreqMin "Output power is being limited due to SPN 20695(Power Converter 1 Frequency) approaching or falling below the SPN 20559 (Power Converter 1 Limits Active Frequency Minimum).
00b = No power limit for this reason
01b = Power limited for this reason
 ...";
CM_ SG_ 2566550526 PLedDueToFreqMax "Output power is being limited due to SPN 20695(Power Converter 1 Frequency) approaching or exceeding the SPN 20558 (Power Converter 1 Limits Active Frequency Maximum).
00b = No power limit for this reason
01b = Power limited for this reason
10b = ...";
CM_ SG_ 2566550526 PLedDueToCurMin "Output power is being limited due to SPN 20694(Power Converter 1 Current) approaching or falling below the SPN 20557 (Power Converter 1 Limits Active Current Minimum).
00b = No power limit for this reason
01b = Power limited for this reason
10b = ...";
CM_ SG_ 2566550526 PLedDueToCurMax "Output power is being limited due to SPN 20694(Power Converter 1 Current) approaching or exceeding the SPN 20556 (Power Converter 1 Limits Active Current Maximum).
00b = No power limit for this reason
01b = Power limited for this reason
10b = ...";
CM_ SG_ 2566550526 PLedDueToDCES1PwrMin "Output power is being limited due to DC Energy Source 1 Power (product of SPN 20696 (Power Converter 1 DC Energy Source 1 Current) and SPN 20697(Power Converter 1 DC Energy Source 1 Voltage)) approaching or falling below the SPN 20553 (Power ...";
CM_ SG_ 2566550526 PLedDueToDCES1PwrMax "Output power is being limited due to DC Energy Source 1 Power (product of SPN 20696 (Power Converter 1 DC Energy Source 1 Current) and SPN 20697(Power Converter 1 DC Energy Source 1 Voltage)) approaching or exceeding the SPN 20552 (Power Converter 1 ...";
CM_ SG_ 2566550526 PLedDueToElectricalPwrMin "Output power is being limited due to Electrical Power (product of SPN 20694(Power Converter 1 Current) and SPN 20695(Power Converter 1 Frequency)) approaching or falling below the SPN 20551 (Power Converter 1 Limits Active Electrical Power Minimum).
 ...";
CM_ SG_ 2566550526 PLedDueToElectricalPwrMax "Output power is being limited due to Electrical Power (product of SPN 20694(Power Converter 1 Current) and SPN 20695(Power Converter 1 Frequency)) approaching or exceeding the SPN 20550 (Power Converter 1 Limits Active Electrical Power Maximum).
 ...";
CM_ SG_ 2566550526 PLedDueToDCES1VMin "Output power is being limited due to SPN 20697(Power Converter 1 DC Energy Source 1 Voltage) approaching or falling below the SPN 20563 (Power Converter 1 Limits Active DC Energy Source 1 Voltage Minimum).
00b = No power limit for this reason
01b ...";
CM_ SG_ 2566550526 PLedDueToDCES1VMax "Output power is being limited due to SPN 20697(Power Converter 1 DC Energy Source 1 Voltage) approaching or exceeding the SPN 20562 (Power Converter 1 Limits Active DC Energy Source 1 Voltage Maximum).
00b = No power limit for this reason
01b = ...";
CM_ SG_ 2566550526 PLedDueToDCES1CurMin "Output power is being limited due to SPN 20696 (Power Converter 1 DC Energy Source 1 Current) approaching or falling below the SPN 20565 (Power Converter 1 Limits Active DC Energy Source 1 Current Minimum).
00b = No power limit for this reason
01b ...";
CM_ SG_ 2566550526 PLedDueToDCES1CurMax "Output power is being limited due to SPN 20696 (Power Converter 1 DC Energy Source 1 Current) approaching or exceeding the SPN 20564 (Power Converter 1 Limits Active DC Energy Source 1 Current Maximum).
00b = No power limit for this reason
01b = ...";
CM_ SG_ 2566550526 PLedDueToUndefinedReason "Output power is being limited due to an undefined reason.

00b = No power limit for this reason
01b = Power limited for this reason
10b = Error
11b = Not Available";
CM_ BO_ 2566550270 "Power Converter 2 Active Power Limits
Sent by this Power Converter instance and contains the current operating conditions of the Power Converter.  This message would be received by a controller application that is responsible for controlling this ...";
CM_ SG_ 2566550270 CurLimDueToMachineCharac "Output current is being limited due to SPN 20672(Power Converter 2 Current) approaching or exceeding a system design characteristic.  For example, for permanent magnet machines, this would be in the field weakening area.
00b = No current limit for ...";
CM_ SG_ 2566550270 PLedDueToActiveCurRateLmt "Output power is being limited due to exceeding internally defined current rate limit(s) or SPN 20486 (Power Converter 2 Rate Limits Request Absolute Current Rate Limit).
00b = No power limit for this reason
01b = Power limited for this reason
10b ...";
CM_ SG_ 2566550270 PLedDueToFaultCondition "Output power is being limited due to an fault condition that requires a current limitation to prevent further damage (e.g. “limp home mode”).  For example, this could be in case of temperature sensor defects.  Typically, this parameter would be ...";
CM_ SG_ 2566550270 PLedDueToTemp "Output power is being limited due to one or more temperature(s), see SPNs 9060 and 10286 through 10288 (Temperature 1-4) approaching or exceeding internally defined limit(s).
00b = No power limit for this reason
01b = Power limited for this reason
 ...";
CM_ SG_ 2566550270 PLedDueToInvTemp "Output power is being limited due to one or more inverter temperature(s), see SPNs 10282 through 10285 (Inverter Temperature 1-4) approaching or exceeding internally defined limit(s).
00b = No power limit for this reason
01b = Power limited for ...";
CM_ SG_ 2566550270 PLedDueToFreqMin "Output power is being limited due to SPN 20673(Power Converter 2 Frequency) approaching or falling below the SPN 20584 (Power Converter 2 Limits Active Frequency Minimum).
00b = No power limit for this reason
01b = Power limited for this reason
 ...";
CM_ SG_ 2566550270 PLedDueToFreqMax "Output power is being limited due to SPN 20673(Power Converter 2 Frequency) approaching or exceeding the SPN 20583 (Power Converter 2 Limits Active Frequency Maximum).
00b = No power limit for this reason
01b = Power limited for this reason
10b = ...";
CM_ SG_ 2566550270 PLedDueToCurMin "Output power is being limited due to SPN 20672(Power Converter 2 Current) approaching or falling below the SPN 20582 (Power Converter 2 Limits Active Current Minimum).
00b = No power limit for this reason
01b = Power limited for this reason
10b = ...";
CM_ SG_ 2566550270 PLedDueToCurMax "Output power is being limited due to SPN 20672(Power Converter 2 Current) approaching or exceeding the SPN 20581 (Power Converter 2 Limits Active Current Maximum).
00b = No power limit for this reason
01b = Power limited for this reason
10b = ...";
CM_ SG_ 2566550270 PLedDueToDCES1PwrMin "Output power is being limited due to DC Energy Source 1 Power (product of SPN 20674 (Power Converter 2 DC Energy Source 1 Current) and SPN 20675(Power Converter 2 DC Energy Source 1 Voltage)) approaching or falling below the SPN 20578 (Power ...";
CM_ SG_ 2566550270 PLedDueToDCES1PwrMax "Output power is being limited due to DC Energy Source 1 Power (product of SPN 20674 (Power Converter 2 DC Energy Source 1 Current) and SPN 20675(Power Converter 2 DC Energy Source 1 Voltage)) approaching or exceeding the SPN 20577 (Power Converter 2 ...";
CM_ SG_ 2566550270 PLedDueToElectricalPwrMin "Output power is being limited due to Electrical Power (product of SPN 20672(Power Converter 2 Current) and SPN 20673(Power Converter 2 Frequency)) approaching or falling below the SPN 20576 (Power Converter 2 Limits Active Electrical Power Minimum).
 ...";
CM_ SG_ 2566550270 PLedDueToElectricalPwrMax "Output power is being limited due to Electrical Power (product of SPN 20672(Power Converter 2 Current) and SPN 20673(Power Converter 2 Frequency)) approaching or exceeding the SPN 20575 (Power Converter 2 Limits Active Electrical Power Maximum).
 ...";
CM_ SG_ 2566550270 PLedDueToDCES1VMin "Output power is being limited due to SPN 20675(Power Converter 2 DC Energy Source 1 Voltage) approaching or falling below the SPN 20588 (Power Converter 2 Limits Active DC Energy Source 1 Voltage Minimum).
00b = No power limit for this reason
01b ...";
CM_ SG_ 2566550270 PLedDueToDCES1VMax "Output power is being limited due to SPN 20675(Power Converter 2 DC Energy Source 1 Voltage) approaching or exceeding the SPN 20587 (Power Converter 2 Limits Active DC Energy Source 1 Voltage Maximum).
00b = No power limit for this reason
01b = ...";
CM_ SG_ 2566550270 PLedDueToDCES1CurMin "Output power is being limited due to SPN 20674 (Power Converter 2 DC Energy Source 1 Current) approaching or falling below the SPN 20590 (Power Converter 2 Limits Active DC Energy Source 1 Current Minimum).
00b = No power limit for this reason
01b ...";
CM_ SG_ 2566550270 PLedDueToDCES1CurMax "Output power is being limited due to SPN 20674 (Power Converter 2 DC Energy Source 1 Current) approaching or exceeding the SPN 20589 (Power Converter 2 Limits Active DC Energy Source 1 Current Maximum).
00b = No power limit for this reason
01b = ...";
CM_ SG_ 2566550270 PLedDueToUndefinedReason "Output power is being limited due to an undefined reason.

00b = No power limit for this reason
01b = Power limited for this reason
10b = Error
11b = Not Available";
CM_ BO_ 2566550014 "Inverter 2 Lifetime Data
Contains data accumulated over the lifetime of this Inverter.";
CM_ SG_ 2566550014 PwrConv2TotalChargeGenerated "Indicates the total lifetime charge generated by this Inverter.  For example, this would include the charge created during regerative braking in a propulsion system.";
CM_ SG_ 2566550014 PwrConv2TotalChargeConsumed "Indicates the total lifetime charge consumed by this Inverter.  For example, this would include the charge used for propulsion in a propulsion system.";
CM_ SG_ 2566550014 PwrConv2TotalEnergyGenerated "Indicates the total lifetime energy generated by this Inverter.  For example, this would include the energy created during regerative braking in a propulsion system.";
CM_ SG_ 2566550014 PwrConv2TotalEnergyConsumed "Indicates the total lifetime energy consumed by this Inverter.  For example, this would include the energy used for propulsion in a propulsion system.";
CM_ BO_ 2566549758 "Inverter 1 Lifetime Data
Contains data accumulated over the lifetime of this Inverter.";
CM_ SG_ 2566549758 PwrConv1TotalChargeGenerated "Indicates the total lifetime charge generated by this Inverter.  For example, this would include the charge created during regerative braking in a propulsion system.";
CM_ SG_ 2566549758 PwrConv1TotalChargeConsumed "Indicates the total lifetime charge consumed by this Inverter.  For example, this would include the charge used for propulsion in a propulsion system.";
CM_ SG_ 2566549758 PwrConv1TotalEnergyGenerated "Indicates the total lifetime energy generated by this Inverter.  For example, this would include the energy created during regerative braking in a propulsion system.";
CM_ SG_ 2566549758 PwrConv1TotalEnergyConsumed "Indicates the total lifetime energy consumed by this Inverter.  For example, this would include the energy used for propulsion in a propulsion system.";
CM_ BO_ 2566549502 "Power Converter 1 Limits Request Power
Sets the electrical and electrical power limits for the Power Converter being controlled.   An example would be for use with an HVESS.";
CM_ SG_ 2566549502 DCES1PwrMin "This requests a minimum limit for the DC Energy Source 1 power.
Refer to SPN 20702 (Power Converter 1 Reference Power) to convert % to kW.
Request a value of FBFh to instruct the Power Converter to use its default values.
For example, in a ...";
CM_ SG_ 2566549502 DCES1PwrMax "This requests a maximum limit for the DC Energy Source 1 power.
Refer to SPN 20702 (Power Converter 1 Reference Power) to convert % to kW.
Request a value of FBFh to instruct the Power Converter to use its default values.
For example, in a ...";
CM_ SG_ 2566549502 ElectricalPwrMin "This requests a minimum limit for the electrical power.
Refer to SPN 20702 (Power Converter 1 Reference Power) to convert % to kW.
Request a value of FBFh to instruct the Power Converter to use its default values.
For example, in a typical ...";
CM_ SG_ 2566549502 ElectricalPwrMax "This requests a maximum limit for the electrical power.
Refer to SPN 20702 (Power Converter 1 Reference Power) to convert % to kW.
Request a value of FBFh to instruct the Power Converter to use its default values.
For example, in a typical ...";
CM_ SG_ 2566549502 Counter "The message counter is used to detect situations where the transmitting ECU malfunction repeats the same frame all the time. The receiver of the information may use the counter parameter to detect this situation. The transmitting device will ...";
CM_ SG_ 2566549502 CRC "The CRC is defined as follows:
• Length: 8 bits
• Polynomial: x^8+x^5+x^3+x^2+x+1
• Initial Value: FFh
• Input Data Reflection: Not reflected
• Result Data Reflection: Not reflected
• XOR value: FFh
SAE makes no claim of the functional safety ...";
CM_ BO_ 2566549246 "Power Converter 1 Limits Request Electrical
Sets the current and frequency limits for the Power Converter being controlled.  An example would be for use with an HVESS.";
CM_ SG_ 2566549246 FreqMin "This is a request to the Power Converter to set a minimum frequency limit for this device.
Refer to SPN 20701 (Power Converter 1 Reference Frequency) to convert % to Hz.
Request a value of FBFh to instruct the Power Converter to use its default ...";
CM_ SG_ 2566549246 FreqMax "This is a request to the Power Converter to set a maximum frequency limit for this device.
Refer to SPN 20701 (Power Converter 1 Reference Frequency) to convert % to Hz.
Request a value of FBFh to instruct the Power Converter to use its default ...";
CM_ SG_ 2566549246 CurMin "This requests a minimum current the Power Converter should command for this device.
Refer to SPN 20690 (Power Converter 1 Reference Current) to convert % to A.
Request a value of FBFh to instruct the Power Converter to use its default values.
For ...";
CM_ SG_ 2566549246 CurMax "This requests a maximum current the Power Converter should command for this device.
Refer to SPN 20690 (Power Converter 1 Reference Current) to convert % to A.
Request a value of FBFh to instruct the Power Converter to use its default values.
For ...";
CM_ SG_ 2566549246 Counter "The message counter is used to detect situations where the transmitting ECU malfunction repeats the same frame all the time. The receiver of the information may use the counter parameter to detect this situation. The transmitting device will ...";
CM_ SG_ 2566549246 CRC "The CRC is defined as follows:
• Length: 8 bits
• Polynomial: x^8+x^5+x^3+x^2+x+1
• Initial Value: FFh
• Input Data Reflection: Not reflected
• Result Data Reflection: Not reflected
• XOR value: FFh
SAE makes no claim of the functional safety ...";
CM_ BO_ 2566548990 "Power Converter 1 Limits Request DC Energy Source 1
Sets the DC Energy Source 1 Voltage and Current limits for the Power Converter being controlled.   An example would be for use with an HVESS.";
CM_ SG_ 2566548990 CurMin "This is a request to the Power Converter to set a minimum DC Energy Source 1 Current limit for this device instance.
Refer to SPN 20690 (Power Converter 1 Reference Current) to convert % to Amps.
Request a value of FBFh to instruct the Power ...";
CM_ SG_ 2566548990 CurMax "This is a request to the Power Converter to set a maximum DC Energy Source 1 Current limit for this device instance.
Refer to SPN 20690 (Power Converter 1 Reference Current) to convert % to Amps.
Request a value of FBFh to instruct the Power ...";
CM_ SG_ 2566548990 VMin "This is a request to the Power Converter to set a minimum DC Energy Source 1 Voltage limit for this device instance.
Refer to SPN 20691 (Power Converter 1 Reference Voltage) to convert % to Volts.
Request a value of FBFh to instruct the Power ...";
CM_ SG_ 2566548990 VMax "This is a request to the Power Converter to set a maximum DC Energy Source 1 Voltage limit for this device instance.
Refer to SPN 20691 (Power Converter 1 Reference Voltage) to convert % to Volts.
Request a value of FBFh to instruct the Power ...";
CM_ SG_ 2566548990 Counter "The message counter is used to detect situations where the transmitting ECU malfunction repeats the same frame all the time. The receiver of the information may use the counter parameter to detect this situation. The transmitting device will ...";
CM_ SG_ 2566548990 CRC "The CRC is defined as follows:
• Length: 8 bits
• Polynomial: x^8+x^5+x^3+x^2+x+1
• Initial Value: FFh
• Input Data Reflection: Not reflected
• Result Data Reflection: Not reflected
• XOR value: FFh
SAE makes no claim of the functional safety ...";
CM_ BO_ 2566548734 "Power Converter 2 Limits Request DC Energy Source 1
Sets the DC Energy Source 1 Voltage and Current limits for the Power Converter being controlled.   An example would be for use with an HVESS.";
CM_ SG_ 2566548734 CurMin "This is a request to the Power Converter to set a minimum DC Energy Source 1 Current limit for this device instance.
Refer to SPN 20667 (Power Converter 2 Reference Current) to convert % to Amps.
Request a value of FBFh to instruct the Power ...";
CM_ SG_ 2566548734 CurMax "This is a request to the Power Converter to set a maximum DC Energy Source 1 Current limit for this device instance.
Refer to SPN 20667 (Power Converter 2 Reference Current) to convert % to Amps.
Request a value of FBFh to instruct the Power ...";
CM_ SG_ 2566548734 VMin "This is a request to the Power Converter to set a minimum DC Energy Source 1 Voltage limit for this device instance.
Refer to SPN 20679 (Power Converter 2 Reference Voltage) to convert % to Volts.
Request a value of FBFh to instruct the Power ...";
CM_ SG_ 2566548734 VMax "This is a request to the Power Converter to set a maximum DC Energy Source 1 Voltage limit for this device instance.
Refer to SPN 20679 (Power Converter 2 Reference Voltage) to convert % to Volts.
Request a value of FBFh to instruct the Power ...";
CM_ SG_ 2566548734 Counter "The message counter is used to detect situations where the transmitting ECU malfunction repeats the same frame all the time. The receiver of the information may use the counter parameter to detect this situation. The transmitting device will ...";
CM_ SG_ 2566548734 CRC "The CRC is defined as follows:
• Length: 8 bits
• Polynomial: x^8+x^5+x^3+x^2+x+1
• Initial Value: FFh
• Input Data Reflection: Not reflected
• Result Data Reflection: Not reflected
• XOR value: FFh
SAE makes no claim of the functional safety ...";
CM_ BO_ 2566548478 "Power Converter 2 Limits Request Electrical
Sets the current and frequency limits for the Power Converter being controlled.  An example would be for use with an HVESS.";
CM_ SG_ 2566548478 FreqMin "This is a request to the Power Converter to set a minimum frequency limit for this device.
Refer to SPN 20668 (Power Converter 2 Reference Frequency) to convert % to Hz.
Request a value of FBFh to instruct the Power Converter to use its default ...";
CM_ SG_ 2566548478 FreqMax "This is a request to the Power Converter to set a maximum frequency limit for this device.
Refer to SPN 20668 (Power Converter 2 Reference Frequency) to convert % to Hz.
Request a value of FBFh to instruct the Power Converter to use its default ...";
CM_ SG_ 2566548478 CurMin "This requests a minimum current the Power Converter should command for this device.
Refer to SPN 20667 (Power Converter 2 Reference Current) to convert % to A.
Request a value of FBFh to instruct the Power Converter to use its default values.
For ...";
CM_ SG_ 2566548478 CurMax "This requests a maximum current the Power Converter should command for this device.
Refer to SPN 20667 (Power Converter 2 Reference Current) to convert % to A.
Request a value of FBFh to instruct the Power Converter to use its default values.
For ...";
CM_ SG_ 2566548478 Counter "The message counter is used to detect situations where the transmitting ECU malfunction repeats the same frame all the time. The receiver of the information may use the counter parameter to detect this situation. The transmitting device will ...";
CM_ SG_ 2566548478 CRC "The CRC is defined as follows:
• Length: 8 bits
• Polynomial: x^8+x^5+x^3+x^2+x+1
• Initial Value: FFh
• Input Data Reflection: Not reflected
• Result Data Reflection: Not reflected
• XOR value: FFh
SAE makes no claim of the functional safety ...";
CM_ BO_ 2566548222 "Power Converter 2 Limits Request Power
Sets the electrical and electrical power limits for the Power Converter being controlled.   An example would be for use with an HVESS.";
CM_ SG_ 2566548222 DCES1PwrMin "This requests a minimum limit for the DC Energy Source 1 power.
Refer to SPN 20669 (Power Converter 2 Reference Power) to convert % to kW.
Request a value of FBFh to instruct the Power Converter to use its default values.
For example, in a ...";
CM_ SG_ 2566548222 DCES1PwrMax "This requests a maximum limit for the DC Energy Source 1 power.
Refer to SPN 20669 (Power Converter 2 Reference Power) to convert % to kW.
Request a value of FBFh to instruct the Power Converter to use its default values.
For example, in a ...";
CM_ SG_ 2566548222 ElectricalPwrMin "This requests a minimum limit for the electrical power.
Refer to SPN 20702 (Power Converter 1 Reference Power) to convert % to kW.
Request a value of FBFh to instruct the Power Converter to use its default values.
For example, in a typical ...";
CM_ SG_ 2566548222 ElectricalPwrMax "This requests a maximum limit for the electrical power.
Refer to SPN 20669 (Power Converter 2 Reference Power) to convert % to kW.
Request a value of FBFh to instruct the Power Converter to use its default values.
For example, in a typical ...";
CM_ SG_ 2566548222 Counter "The message counter is used to detect situations where the transmitting ECU malfunction repeats the same frame all the time. The receiver of the information may use the counter parameter to detect this situation. The transmitting device will ...";
CM_ SG_ 2566548222 CRC "The CRC is defined as follows:
• Length: 8 bits
• Polynomial: x^8+x^5+x^3+x^2+x+1
• Initial Value: FFh
• Input Data Reflection: Not reflected
• Result Data Reflection: Not reflected
• XOR value: FFh
SAE makes no claim of the functional safety ...";
CM_ BO_ 2566547966 "Power Converter 1 Isolation Integrity Request
Requests the Power Converter to perform isolation integrity related tests.";
CM_ SG_ 2566547966 HVBusLowSideResistorConnectReq "This parameter is used to request connection of the Power Converter High-Voltage bus low side resistor in order to perform an isolation test.
00b = Connection not Requested
01b = Connection Requested
10b = Reserved
11b = Don’t care/take no ...";
CM_ SG_ 2566547966 HVBusHiSideResistorConnectReq "This parameter is used to request connection of the Power Converter High-Voltage bus high side resistor in order to perform an isolation test.
00b = Connection not Requested
01b = Connection Requested
10b = Reserved
11b = Don’t care/take no ...";
CM_ SG_ 2566547966 HVBusPassiveIsolTestCmd "Command for the Power Converter to perform a passive electrical isolation test on the high voltage bus.
A passive isolation test uses additional circuitry (e.g. a high impedance network) to monitor the delta between the high voltage connections ...";
CM_ SG_ 2566547966 HVBusActiveIsolTestCmd "Command for the Power Converter to perform an active electrical isolation test on the high voltage bus.
An active isolation test might use a generated signal (e.g. an injected AC signal) and then monitor changes in the measurements of the isolated ...";
CM_ BO_ 2566547710 "Power Converter 2 Isolation Integrity Request
Requests the Power Converter to perform isolation integrity related tests.";
CM_ SG_ 2566547710 HVBusLowSideResistorConnectReq "This parameter is used to request connection of the Power Converter High-Voltage bus low side resistor in order to perform an isolation test.
00b = Connection not Requested
01b = Connection Requested
10b = Reserved
11b = Don’t care/take no ...";
CM_ SG_ 2566547710 HVBusHiSideResistorConnectReq "This parameter is used to request connection of the Power Converter High-Voltage bus high side resistor in order to perform an isolation test.
00b = Connection not Requested
01b = Connection Requested
10b = Reserved
11b = Don’t care/take no ...";
CM_ SG_ 2566547710 HVBusPassiveIsolTestCmd "Command for the Power Converter to perform a passive electrical isolation test on the high voltage bus.
A passive isolation test uses additional circuitry (e.g. a high impedance network) to monitor the delta between the high voltage connections ...";
CM_ SG_ 2566547710 HVBusActiveIsolTestCmd "Command for the Power Converter to perform an active electrical isolation test on the high voltage bus.
An active isolation test might use a generated signal (e.g. an injected AC signal) and then monitor changes in the measurements of the isolated ...";
CM_ BO_ 2633656318 "Fluid Resistance 1";
CM_ SG_ 2633656318 HydOilRes "Electric resistance of hydraulic oil";
CM_ SG_ 2633656318 EngOilRes "Electric resistance of engine oil";
CM_ BO_ 2566547198 "Aftertreatment System Information 3
Contains information which relates to the exhaust particulate control system on the engine.";
CM_ SG_ 2566547198 DEFQualityMalfunctionCount "The total occurrences of diagnostic code for the Diesel Exhaust Fluid Quality Malfunction that have been active above a predetermined time threshold. A bucket that has been active less than the predetermined time threshold (for example, 20 hours) ...";
CM_ SG_ 2566547198 DEFTank1EmptyCount "The total occurrences of diagnostic code for the Diesel Exhaust Fluid Tank 1 Empty. This parameter will accumulate over the life of the product and will never be reset.

(Reference EU Commission Delegated Regulation 2016-8381 final ANNEXES 1-5)";
CM_ BO_ 2566546942 "Aftertreatment System Information 4
Contains information which relates to the exhaust particulate control system on the engine.";
CM_ SG_ 2566546942 DEFFrozenCount "The total occurrences of diagnostic code for the Diesel Exhaust Fluid Frozen.

This parameter will accumulate over the life of the product and will never be reset.

(Reference EU Commission Delegated Regulation 2016-8381 final ANNEXES 1-5)";
CM_ SG_ 2566546942 SCRMalfunctionCount "The total occurrences of diagnostic code for the Aftertreatment SCR Malfunction that have been active above a predetermined time threshold. A bucket that has been active less than the predetermined time threshold (for example, 20 hours) will not be ...";
CM_ BO_ 2566546686 "Aftertreatment System Information 5
Contains information which relates to the exhaust particulate control system on the engine.";
CM_ SG_ 2566546686 OneTotalEventCountWithNoDEFDel "The total occurrences of diagnostic code for the Aftertreatment With No DEF Delivery that have been active above a predetermined time threshold. A bucket that has been active less than the predetermined time threshold (for example, 20 hours) will ...";
CM_ SG_ 2566546686 OneSCRInHiTempCount "The total occurrences of diagnostic code for the Aftertreatment 1 SCR Intake High Temperature.
This parameter will accumulate over the life of the product and will never be reset.
(Reference EU Commission Delegated Regulation 2016-8381 final ...";
CM_ BO_ 2365219838 "Lighting Command 2
This message is used to control the state of lighting functions. The message shall be sent on each change of state of a lamp. The state values indicate the lights is to be turned ON or OFF. Flashing is accomplished by sending the ...";
CM_ SG_ 2365219838 TractorHazardLightsCmd "Command to activate or de-activate the tractor hazard lights.

00b = De-activate
01b = Activate
10b = Reserved
11b = Don't Care";
CM_ SG_ 2365219838 Data2ReqCmd "Command to provide a response of the light state for the light commands in this message.

00b = Response not requested
01b = Response requested
10b = Reserved
11b = Don't Care";
CM_ BO_ 2566546174 "Lighting Data 2
This lighting message is a response to the request for lighting data in the corresponding lighting command message. Each lighting controller on the tractor and attached implements must transmit this message when requested. The ...";
CM_ SG_ 2566546174 TractorHazardLights "This parameter provides measured data from the vehicle's hazard lights.

00b = De-activated
01b = Activated
10b = Fault Detected
11b = Not Available";
CM_ BO_ 2566545662 "EV DC Charging In Progress
Optional information on the present charge cycle that may be sent to the EVSE from the EV for display purposes.
This PG may be used on systems that only support a single connection to a DC EVSE. Or where all DC EVSEs ...";
CM_ SG_ 2566545662 DepTime "Time remaining until the vehicle's expected departure.

See ISO 15118-2/Figure 92 Ref. V2G2-371";
CM_ SG_ 2566545662 FullChargeTimeRemaining "Remaining time to complete full charging.

See SAE J2847-2 201504 Sect 4.2.77";
CM_ SG_ 2566545662 BulkChargeTimeRemaining "Remaining time to complete bulk charging.

See SAE J2847-2 201504 Sect 4.2.76";
CM_ SG_ 2566545662 FullChargingComplete "For EVSE display purposes, this parameter indicates if full charging is complete.

00b = Full charging not complete
01b = Full charging complete
10b = Error
11b = Not available

See SAE J2847-2 201504 Sect 4.2.5";
CM_ SG_ 2566545662 BulkChargingComplete "Optional, for EVSE display purposes, this parameter indicates if bulk charging is complete.

00b = Bulk charging not complete
01b = Bulk charging complete
10b = Error
11b = Not available

See SAE J2847-2 201504 Sect 4.2.2";
CM_ BO_ 2566545406 "EV DC Charging Limits 2
Optional data used by the EVCC when initializing a new connection with an EVSE that supports DC charging.
This PG may be used on systems that only support a single connection to a DC EVSE.
It has been superseded by PGN ...";
CM_ SG_ 2566545406 EnergyReq "Amount of energy the EV requests from the EVSE

See SAE J2847-2 201504 Sect 4.2.25";
CM_ SG_ 2566545406 EnergyCapacity "Maximum energy capacity supported by the EV.

See SAE J2847-2 201504 Sect 4.2.24";
CM_ SG_ 2566545406 FullStOfCharge "State of charge value, as indicated by SPN 7895, where charging is considered to be complete. (Typically 100%)

See SAE J2847-2 201504 Sect. 4.2.57";
CM_ SG_ 2566545406 BulkStOfCharge "State of charge value, as indicated by SPN 7895, where \"bulk\" charging is considered to be complete. (For example 80%)

See SAE J2847-2 201504 Sect. 4.2.3";
CM_ BO_ 2566545150 "EV Charge Profile
This message may be sent to the EVCC from the EV just prior to requesting power and starting the charge cycle. It is used to select one of the schedules returned by EVSE1SCHED and to indicate the vehicle's power requirements ...";
CM_ SG_ 2566545150 ProfileEntryStart "Optional Starting time from now when this profile entry becomes active.
There may be zero to 24 parameter pairs of EV Profile Entry Max Power and EV Profile Entry Start  in this PG

See J2847-2 201504 Sect 4.2.8";
CM_ SG_ 2566545150 ProfileEntryMaxPwr "Optional Maximum power to be used in this section of the charging profile.
There may be zero to 24 parameter pairs of EV Profile Entry Max Power and EV Profile Entry Start  in this PG

See J2847-2 201504 Sect 4.2.7";
CM_ SG_ 2566545150 SelectedScheduleID "16-bit ID for the schedule to be used. This will be a SPN 21067 (EVSE1 Schedule Id) value as read from an earlier EVSE1SCHED1 PG

See J2847-2 201504 Sect 4.2.82";
CM_ BO_ 2566544894 "EVSE Power Max Schedule
EVCC sends on request. Contains data on the connected DC EVSE's power availability.
During initialization the EVSE will send 1 to 3 power availability schedules. The first of these schedules is the default schedule.
If ...";
CM_ SG_ 2566544894 EntryDur "Duration of section of the schedule.
Only valid for the last entry in the schedule. For all other entries it shall be set to FFFFFFFFh.

See J2847-2 201504 Sect 4.2.21";
CM_ SG_ 2566544894 EntryStartTime "Time from now when this section of the schedule starts.

See J2847-2 2015 Sect 4.2.101";
CM_ SG_ 2566544894 EntryPwrMax "Maximum Power allowed in this section of the schedule.

See J2847-2 201504 Sect 4.2.62";
CM_ SG_ 2566544894 PMaxScheduleId "16-bit ID value supplied by the EVSE

See J2847-2 201504 Sect 4.2.66";
CM_ SG_ 2566544894 ScheduleId "16-bit ID value used by the EVSE to identify the schedule.

See J2847-2 201504 Sect 4.2.82";
CM_ SG_ 2566544894 MaxScheduleIndex "This indicates the number of available schedules. 

The vehicle should first request the default schedule, (index=1) and then use this parameter to determine how many other schedules are available.";
CM_ SG_ 2566544894 ScheduleIndex "The index number of the schedule.
1 indicates the default schedule.

This value may be considered as an Extended Id value when using RQST2 to request a specific Power Max Schedule.";
CM_ BO_ 2566544638 "EVSE DC Charging Limits 3
This message is sent from the EVCC to the EV. Contains status information received from the DC EVSE.
If this PG is requested, e.g. using RQST, when no EVSE is connected then specific values or states are provided in each ...";
CM_ SG_ 2566544638 EnergyToBeDelivered "This signal represents the allowed or requested units of energy to be delivered during charging (a charging target). This allows public charging stations to limit charging session by limiting the energy transfer (i.e., for a prepaid amount).
 ...";
BA_DEF_ SG_  "GenSigInactiveValue" INT 0 0;
BA_DEF_ SG_  "SigType" ENUM  "Default","Range","RangeSigned","ASCII","Discrete","Control","ReferencePGN","DTC","StringDelimiter","StringLength","StringLengthControl","MessageCounter","MessageChecksum";
BA_DEF_ SG_  "GenSigStartValue" INT 0 2147483647;
BA_DEF_ SG_  "GenSigSendType" ENUM  "Cyclic","OnWrite","OnWriteWithRepetition","OnChange","OnChangeWithRepetition","IfActive","IfActiveWithRepetition","NoSigSendType";
BA_DEF_ SG_  "GenSigILSupport" ENUM  "No","Yes";
BA_DEF_ SG_  "SPN" INT 0 524287;
BA_DEF_ BO_  "J1939CPgSendTimeout" INT -1 3600000;
BA_DEF_ BO_  "J1939CPgTOS" INT 0 7;
BA_DEF_ BO_  "J1939PgAppearanceOnBus" ENUM  "Default","CAN_Extended","CANFD_Extended";
BA_DEF_ BO_  "FsJ1939UseCrcAndCounter" STRING ;
BA_DEF_ BO_  "TpJ1939VarDlc" ENUM  "No","Yes";
BA_DEF_ BO_  "GenMsgNrOfRepetition" INT 0 1000000;
BA_DEF_ BO_  "GenMsgCycleTimeFast" INT 0 3600000;
BA_DEF_ BO_  "GenMsgFastOnStart" INT 0 100000;
BA_DEF_ BO_  "GenMsgStartDelayTime" INT 0 100000;
BA_DEF_ BO_  "GenMsgILSupport" ENUM  "No","Yes";
BA_DEF_ BO_  "GenMsgDelayTime" INT 0 1000;
BA_DEF_ BO_  "GenMsgRequestable" INT 0 1;
BA_DEF_ BO_  "GenMsgSendType" ENUM  "cyclic","NotUsed","NotUsed","NotUsed","NotUsed","NotUsed","NotUsed","IfActive","noMsgSendType";
BA_DEF_ BO_  "VFrameFormat" ENUM  "StandardCAN","ExtendedCAN","reserved","J1939PG","reserved","reserved","reserved","reserved","reserved","reserved","reserved","reserved","reserved","reserved","StandardCAN_FD","ExtendedCAN_FD";
BA_DEF_ BO_  "SingleFrame" INT 0 1;
BA_DEF_ BO_  "GenMsgCycleTime" INT 0 3600000;
BA_DEF_ SG_  "SystemSignalLongSymbol" STRING ;
BA_DEF_DEF_  "GenSigInactiveValue" 0;
BA_DEF_DEF_  "SigType" "Default";
BA_DEF_DEF_  "GenSigStartValue" 0;
BA_DEF_DEF_  "GenSigSendType" "NoSigSendType";
BA_DEF_DEF_  "GenSigILSupport" "Yes";
BA_DEF_DEF_  "SPN" 0;
BA_DEF_DEF_  "J1939CPgSendTimeout" -1;
BA_DEF_DEF_  "J1939CPgTOS" 2;
BA_DEF_DEF_  "J1939PgAppearanceOnBus" "Default";
BA_DEF_DEF_  "FsJ1939UseCrcAndCounter" "";
BA_DEF_DEF_  "TpJ1939VarDlc" "No";
BA_DEF_DEF_  "GenMsgNrOfRepetition" 0;
BA_DEF_DEF_  "GenMsgCycleTimeFast" 0;
BA_DEF_DEF_  "GenMsgFastOnStart" 0;
BA_DEF_DEF_  "GenMsgStartDelayTime" 0;
BA_DEF_DEF_  "GenMsgILSupport" "Yes";
BA_DEF_DEF_  "GenMsgDelayTime" 0;
BA_DEF_DEF_  "GenMsgRequestable" 1;
BA_DEF_DEF_  "GenMsgSendType" "noMsgSendType";
BA_DEF_DEF_  "VFrameFormat" "J1939PG";
BA_DEF_DEF_  "SingleFrame" 1;
BA_DEF_DEF_  "GenMsgCycleTime" 0;
BA_DEF_DEF_  "SystemSignalLongSymbol" "";
BA_ "GenMsgSendType" BO_ 2566554622 0;
BA_ "GenMsgCycleTime" BO_ 2566554622 1000;
BA_ "GenMsgSendType" BO_ 2566554366 0;
BA_ "GenMsgCycleTime" BO_ 2566554366 1000;
BA_ "GenMsgSendType" BO_ 2365227518 0;
BA_ "GenMsgCycleTime" BO_ 2365227518 1000;
BA_ "GenMsgSendType" BO_ 2365227262 0;
BA_ "GenMsgCycleTime" BO_ 2365227262 1000;
BA_ "GenMsgSendType" BO_ 2365227006 0;
BA_ "GenMsgCycleTime" BO_ 2365227006 1000;
BA_ "GenMsgSendType" BO_ 2566553342 0;
BA_ "GenMsgCycleTime" BO_ 2566553342 1000;
BA_ "GenMsgSendType" BO_ 2365226494 0;
BA_ "GenMsgCycleTime" BO_ 2365226494 1000;
BA_ "GenMsgSendType" BO_ 2365226238 0;
BA_ "GenMsgCycleTime" BO_ 2365226238 1000;
BA_ "GenMsgSendType" BO_ 2365225982 0;
BA_ "GenMsgCycleTime" BO_ 2365225982 1000;
BA_ "GenMsgSendType" BO_ 2365225726 0;
BA_ "GenMsgCycleTime" BO_ 2365225726 1000;
BA_ "FsJ1939UseCrcAndCounter" BO_ 2365225470 "Bc";
BA_ "GenMsgSendType" BO_ 2365225470 0;
BA_ "GenMsgCycleTime" BO_ 2365225470 1000;
BA_ "FsJ1939UseCrcAndCounter" BO_ 2365225214 "Bc";
BA_ "GenMsgSendType" BO_ 2365225214 0;
BA_ "GenMsgCycleTime" BO_ 2365225214 1000;
BA_ "GenMsgSendType" BO_ 2566551550 0;
BA_ "GenMsgCycleTime" BO_ 2566551550 1000;
BA_ "GenMsgSendType" BO_ 2566551294 0;
BA_ "GenMsgCycleTime" BO_ 2566551294 1000;
BA_ "FsJ1939UseCrcAndCounter" BO_ 2365224446 "Bc";
BA_ "GenMsgSendType" BO_ 2365224446 0;
BA_ "GenMsgCycleTime" BO_ 2365224446 1000;
BA_ "FsJ1939UseCrcAndCounter" BO_ 2365224190 "Bc";
BA_ "GenMsgSendType" BO_ 2365224190 0;
BA_ "GenMsgCycleTime" BO_ 2365224190 1000;
BA_ "GenMsgDelayTime" BO_ 2566550526 100;
BA_ "GenMsgSendType" BO_ 2566550526 0;
BA_ "GenMsgCycleTime" BO_ 2566550526 1000;
BA_ "GenMsgDelayTime" BO_ 2566550270 100;
BA_ "GenMsgSendType" BO_ 2566550270 0;
BA_ "GenMsgCycleTime" BO_ 2566550270 1000;
BA_ "FsJ1939UseCrcAndCounter" BO_ 2566549502 "Bc";
BA_ "GenMsgSendType" BO_ 2566549502 0;
BA_ "GenMsgCycleTime" BO_ 2566549502 1000;
BA_ "FsJ1939UseCrcAndCounter" BO_ 2566549246 "Bc";
BA_ "GenMsgSendType" BO_ 2566549246 0;
BA_ "GenMsgCycleTime" BO_ 2566549246 1000;
BA_ "FsJ1939UseCrcAndCounter" BO_ 2566548990 "Bc";
BA_ "GenMsgSendType" BO_ 2566548990 0;
BA_ "GenMsgCycleTime" BO_ 2566548990 1000;
BA_ "FsJ1939UseCrcAndCounter" BO_ 2566548734 "Bc";
BA_ "GenMsgSendType" BO_ 2566548734 0;
BA_ "GenMsgCycleTime" BO_ 2566548734 1000;
BA_ "FsJ1939UseCrcAndCounter" BO_ 2566548478 "Bc";
BA_ "GenMsgSendType" BO_ 2566548478 0;
BA_ "GenMsgCycleTime" BO_ 2566548478 1000;
BA_ "FsJ1939UseCrcAndCounter" BO_ 2566548222 "Bc";
BA_ "GenMsgSendType" BO_ 2566548222 0;
BA_ "GenMsgCycleTime" BO_ 2566548222 1000;
BA_ "GenMsgSendType" BO_ 2633656318 0;
BA_ "GenMsgCycleTime" BO_ 2633656318 30000;
BA_ "GenMsgDelayTime" BO_ 2365219838 100;
BA_ "GenMsgSendType" BO_ 2365219838 0;
BA_ "GenMsgCycleTime" BO_ 2365219838 1000;
BA_ "GenMsgDelayTime" BO_ 2566545662 100;
BA_ "GenMsgSendType" BO_ 2566545662 0;
BA_ "GenMsgCycleTime" BO_ 2566545662 10000;
BA_ "TpJ1939VarDlc" BO_ 2566545150 1;
BA_ "TpJ1939VarDlc" BO_ 2566544894 1;
BA_ "SigType" SG_ 2633669886 TotalEnergyOut 1;
BA_ "SPN" SG_ 2633669886 TotalEnergyOut 17104;
BA_ "SigType" SG_ 2633669886 TotalEnergyInput 1;
BA_ "SPN" SG_ 2633669886 TotalEnergyInput 17103;
BA_ "SigType" SG_ 2633669886 TotalAccumulatedCharge 1;
BA_ "SPN" SG_ 2633669886 TotalAccumulatedCharge 17102;
BA_ "SigType" SG_ 2633669886 TotalEnergyThroughput 1;
BA_ "SPN" SG_ 2633669886 TotalEnergyThroughput 17101;
BA_ "SigType" SG_ 2633669886 ContactorOpenUnderLoadCount 1;
BA_ "SPN" SG_ 2633669886 ContactorOpenUnderLoadCount 17100;
BA_ "SigType" SG_ 2633669886 StOfHealth 1;
BA_ "SPN" SG_ 2633669886 StOfHealth 17099;
BA_ "SPN" SG_ 2566560766 NomRatedCapacity 16972;
BA_ "SigType" SG_ 2566560766 CellMinVLmt 1;
BA_ "SPN" SG_ 2566560766 CellMinVLmt 16971;
BA_ "SigType" SG_ 2566560766 CellMaxVLmt 1;
BA_ "SPN" SG_ 2566560766 CellMaxVLmt 16970;
BA_ "SigType" SG_ 2566560766 RecommendedMinOperatingTemp 1;
BA_ "SPN" SG_ 2566560766 RecommendedMinOperatingTemp 16969;
BA_ "SigType" SG_ 2566560766 RecommendedMaxOperatingTemp 1;
BA_ "SPN" SG_ 2566560766 RecommendedMaxOperatingTemp 16968;
BA_ "SigType" SG_ 2566560766 RecommendedMaxStOfCharge 1;
BA_ "SPN" SG_ 2566560766 RecommendedMaxStOfCharge 16967;
BA_ "SigType" SG_ 2566560766 RecommendedMinStOfCharge 1;
BA_ "SPN" SG_ 2566560766 RecommendedMinStOfCharge 16966;
BA_ "SigType" SG_ 2566560766 RecommendedMaxOperatingV 1;
BA_ "SPN" SG_ 2566560766 RecommendedMaxOperatingV 16965;
BA_ "SigType" SG_ 2566560766 RecommendedMinOperatingV 1;
BA_ "SPN" SG_ 2566560766 RecommendedMinOperatingV 16964;
BA_ "SigType" SG_ 2566560766 NomV 1;
BA_ "SPN" SG_ 2566560766 NomV 16963;
BA_ "SigType" SG_ 2633669374 TotalEnergyOut 1;
BA_ "SPN" SG_ 2633669374 TotalEnergyOut 16962;
BA_ "SigType" SG_ 2633669374 TotalEnergyInput 1;
BA_ "SPN" SG_ 2633669374 TotalEnergyInput 16961;
BA_ "SigType" SG_ 2633669374 TotalAccumulatedCharge 1;
BA_ "SPN" SG_ 2633669374 TotalAccumulatedCharge 16960;
BA_ "SigType" SG_ 2633669374 TotalEnergyThroughput 1;
BA_ "SPN" SG_ 2633669374 TotalEnergyThroughput 16959;
BA_ "SigType" SG_ 2633669374 ContactorOpenUnderLoadCount 1;
BA_ "SPN" SG_ 2633669374 ContactorOpenUnderLoadCount 16958;
BA_ "SigType" SG_ 2633669374 StOfHealth 1;
BA_ "SPN" SG_ 2633669374 StOfHealth 16957;
BA_ "SPN" SG_ 2566560254 NomRatedCapacity 16830;
BA_ "SigType" SG_ 2566560254 CellMinVLmt 1;
BA_ "SPN" SG_ 2566560254 CellMinVLmt 16829;
BA_ "SigType" SG_ 2566560254 CellMaxVLmt 1;
BA_ "SPN" SG_ 2566560254 CellMaxVLmt 16828;
BA_ "SigType" SG_ 2566560254 RecommendedMinOperatingTemp 1;
BA_ "SPN" SG_ 2566560254 RecommendedMinOperatingTemp 16827;
BA_ "SigType" SG_ 2566560254 RecommendedMaxOperatingTemp 1;
BA_ "SPN" SG_ 2566560254 RecommendedMaxOperatingTemp 16826;
BA_ "SigType" SG_ 2566560254 RecommendedMaxStOfCharge 1;
BA_ "SPN" SG_ 2566560254 RecommendedMaxStOfCharge 16825;
BA_ "SigType" SG_ 2566560254 RecommendedMinStOfCharge 1;
BA_ "SPN" SG_ 2566560254 RecommendedMinStOfCharge 16824;
BA_ "SigType" SG_ 2566560254 RecommendedMaxOperatingV 1;
BA_ "SPN" SG_ 2566560254 RecommendedMaxOperatingV 16823;
BA_ "SigType" SG_ 2566560254 RecommendedMinOperatingV 1;
BA_ "SPN" SG_ 2566560254 RecommendedMinOperatingV 16822;
BA_ "SigType" SG_ 2566560254 NomV 1;
BA_ "SPN" SG_ 2566560254 NomV 16821;
BA_ "SigType" SG_ 2633668862 TotalEnergyOut 1;
BA_ "SPN" SG_ 2633668862 TotalEnergyOut 16820;
BA_ "SigType" SG_ 2633668862 TotalEnergyInput 1;
BA_ "SPN" SG_ 2633668862 TotalEnergyInput 16819;
BA_ "SigType" SG_ 2633668862 TotalAccumulatedCharge 1;
BA_ "SPN" SG_ 2633668862 TotalAccumulatedCharge 16818;
BA_ "SigType" SG_ 2633668862 TotalEnergyThroughput 1;
BA_ "SPN" SG_ 2633668862 TotalEnergyThroughput 16817;
BA_ "SigType" SG_ 2633668862 ContactorOpenUnderLoadCount 1;
BA_ "SPN" SG_ 2633668862 ContactorOpenUnderLoadCount 16816;
BA_ "SigType" SG_ 2633668862 StOfHealth 1;
BA_ "SPN" SG_ 2633668862 StOfHealth 16815;
BA_ "SPN" SG_ 2566559742 NomRatedCapacity 16688;
BA_ "SigType" SG_ 2566559742 CellMinVLmt 1;
BA_ "SPN" SG_ 2566559742 CellMinVLmt 16687;
BA_ "SigType" SG_ 2566559742 CellMaxVLmt 1;
BA_ "SPN" SG_ 2566559742 CellMaxVLmt 16686;
BA_ "SigType" SG_ 2566559742 RecommendedMinOperatingTemp 1;
BA_ "SPN" SG_ 2566559742 RecommendedMinOperatingTemp 16685;
BA_ "SigType" SG_ 2566559742 RecommendedMaxOperatingTemp 1;
BA_ "SPN" SG_ 2566559742 RecommendedMaxOperatingTemp 16684;
BA_ "SigType" SG_ 2566559742 RecommendedMaxStOfCharge 1;
BA_ "SPN" SG_ 2566559742 RecommendedMaxStOfCharge 16683;
BA_ "SigType" SG_ 2566559742 RecommendedMinStOfCharge 1;
BA_ "SPN" SG_ 2566559742 RecommendedMinStOfCharge 16682;
BA_ "SigType" SG_ 2566559742 RecommendedMaxOperatingV 1;
BA_ "SPN" SG_ 2566559742 RecommendedMaxOperatingV 16681;
BA_ "SigType" SG_ 2566559742 RecommendedMinOperatingV 1;
BA_ "SPN" SG_ 2566559742 RecommendedMinOperatingV 16680;
BA_ "SigType" SG_ 2566559742 NomV 1;
BA_ "SPN" SG_ 2566559742 NomV 16679;
BA_ "SigType" SG_ 2633668350 TotalEnergyOut 1;
BA_ "SPN" SG_ 2633668350 TotalEnergyOut 16678;
BA_ "SigType" SG_ 2633668350 TotalEnergyInput 1;
BA_ "SPN" SG_ 2633668350 TotalEnergyInput 16677;
BA_ "SigType" SG_ 2633668350 TotalAccumulatedCharge 1;
BA_ "SPN" SG_ 2633668350 TotalAccumulatedCharge 16676;
BA_ "SigType" SG_ 2633668350 TotalEnergyThroughput 1;
BA_ "SPN" SG_ 2633668350 TotalEnergyThroughput 16675;
BA_ "SigType" SG_ 2633668350 ContactorOpenUnderLoadCount 1;
BA_ "SPN" SG_ 2633668350 ContactorOpenUnderLoadCount 16674;
BA_ "SigType" SG_ 2633668350 StOfHealth 1;
BA_ "SPN" SG_ 2633668350 StOfHealth 16673;
BA_ "SPN" SG_ 2566559230 NomRatedCapacity 16546;
BA_ "SigType" SG_ 2566559230 CellMinVLmt 1;
BA_ "SPN" SG_ 2566559230 CellMinVLmt 16545;
BA_ "SigType" SG_ 2566559230 CellMaxVLmt 1;
BA_ "SPN" SG_ 2566559230 CellMaxVLmt 16544;
BA_ "SigType" SG_ 2566559230 RecommendedMinOperatingTemp 1;
BA_ "SPN" SG_ 2566559230 RecommendedMinOperatingTemp 16543;
BA_ "SigType" SG_ 2566559230 RecommendedMaxOperatingTemp 1;
BA_ "SPN" SG_ 2566559230 RecommendedMaxOperatingTemp 16542;
BA_ "SigType" SG_ 2566559230 RecommendedMaxStOfCharge 1;
BA_ "SPN" SG_ 2566559230 RecommendedMaxStOfCharge 16541;
BA_ "SigType" SG_ 2566559230 RecommendedMinStOfCharge 1;
BA_ "SPN" SG_ 2566559230 RecommendedMinStOfCharge 16540;
BA_ "SigType" SG_ 2566559230 RecommendedMaxOperatingV 1;
BA_ "SPN" SG_ 2566559230 RecommendedMaxOperatingV 16539;
BA_ "SigType" SG_ 2566559230 RecommendedMinOperatingV 1;
BA_ "SPN" SG_ 2566559230 RecommendedMinOperatingV 16538;
BA_ "SigType" SG_ 2566559230 NomV 1;
BA_ "SPN" SG_ 2566559230 NomV 16537;
BA_ "SigType" SG_ 2633667838 TotalEnergyOut 1;
BA_ "SPN" SG_ 2633667838 TotalEnergyOut 16536;
BA_ "SigType" SG_ 2633667838 TotalEnergyInput 1;
BA_ "SPN" SG_ 2633667838 TotalEnergyInput 16535;
BA_ "SigType" SG_ 2633667838 TotalAccumulatedCharge 1;
BA_ "SPN" SG_ 2633667838 TotalAccumulatedCharge 16534;
BA_ "SigType" SG_ 2633667838 TotalEnergyThroughput 1;
BA_ "SPN" SG_ 2633667838 TotalEnergyThroughput 16533;
BA_ "SigType" SG_ 2633667838 ContactorOpenUnderLoadCount 1;
BA_ "SPN" SG_ 2633667838 ContactorOpenUnderLoadCount 16532;
BA_ "SigType" SG_ 2633667838 StOfHealth 1;
BA_ "SPN" SG_ 2633667838 StOfHealth 16531;
BA_ "SPN" SG_ 2566558718 NomRatedCapacity 16404;
BA_ "SigType" SG_ 2566558718 CellMinVLmt 1;
BA_ "SPN" SG_ 2566558718 CellMinVLmt 16403;
BA_ "SigType" SG_ 2566558718 CellMaxVLmt 1;
BA_ "SPN" SG_ 2566558718 CellMaxVLmt 16402;
BA_ "SigType" SG_ 2566558718 RecommendedMinOperatingTemp 1;
BA_ "SPN" SG_ 2566558718 RecommendedMinOperatingTemp 16401;
BA_ "SigType" SG_ 2566558718 RecommendedMaxOperatingTemp 1;
BA_ "SPN" SG_ 2566558718 RecommendedMaxOperatingTemp 16400;
BA_ "SigType" SG_ 2566558718 RecommendedMaxStOfCharge 1;
BA_ "SPN" SG_ 2566558718 RecommendedMaxStOfCharge 16399;
BA_ "SigType" SG_ 2566558718 RecommendedMinStOfCharge 1;
BA_ "SPN" SG_ 2566558718 RecommendedMinStOfCharge 16398;
BA_ "SigType" SG_ 2566558718 RecommendedMaxOperatingV 1;
BA_ "SPN" SG_ 2566558718 RecommendedMaxOperatingV 16397;
BA_ "SigType" SG_ 2566558718 RecommendedMinOperatingV 1;
BA_ "SPN" SG_ 2566558718 RecommendedMinOperatingV 16396;
BA_ "SigType" SG_ 2566558718 NomV 1;
BA_ "SPN" SG_ 2566558718 NomV 16395;
BA_ "SigType" SG_ 2633667326 TotalEnergyOut 1;
BA_ "SPN" SG_ 2633667326 TotalEnergyOut 16394;
BA_ "SigType" SG_ 2633667326 TotalEnergyInput 1;
BA_ "SPN" SG_ 2633667326 TotalEnergyInput 16393;
BA_ "SigType" SG_ 2633667326 TotalAccumulatedCharge 1;
BA_ "SPN" SG_ 2633667326 TotalAccumulatedCharge 16392;
BA_ "SigType" SG_ 2633667326 TotalEnergyThroughput 1;
BA_ "SPN" SG_ 2633667326 TotalEnergyThroughput 16391;
BA_ "SigType" SG_ 2633667326 ContactorOpenUnderLoadCount 1;
BA_ "SPN" SG_ 2633667326 ContactorOpenUnderLoadCount 16390;
BA_ "SigType" SG_ 2633667326 StOfHealth 1;
BA_ "SPN" SG_ 2633667326 StOfHealth 16389;
BA_ "SPN" SG_ 2566558206 NomRatedCapacity 16262;
BA_ "SigType" SG_ 2566558206 CellMinVLmt 1;
BA_ "SPN" SG_ 2566558206 CellMinVLmt 16261;
BA_ "SigType" SG_ 2566558206 CellMaxVLmt 1;
BA_ "SPN" SG_ 2566558206 CellMaxVLmt 16260;
BA_ "SigType" SG_ 2566558206 RecommendedMinOperatingTemp 1;
BA_ "SPN" SG_ 2566558206 RecommendedMinOperatingTemp 16259;
BA_ "SigType" SG_ 2566558206 RecommendedMaxOperatingTemp 1;
BA_ "SPN" SG_ 2566558206 RecommendedMaxOperatingTemp 16258;
BA_ "SigType" SG_ 2566558206 RecommendedMaxStOfCharge 1;
BA_ "SPN" SG_ 2566558206 RecommendedMaxStOfCharge 16257;
BA_ "SigType" SG_ 2566558206 RecommendedMinStOfCharge 1;
BA_ "SPN" SG_ 2566558206 RecommendedMinStOfCharge 16256;
BA_ "SigType" SG_ 2566558206 RecommendedMaxOperatingV 1;
BA_ "SPN" SG_ 2566558206 RecommendedMaxOperatingV 16255;
BA_ "SigType" SG_ 2566558206 RecommendedMinOperatingV 1;
BA_ "SPN" SG_ 2566558206 RecommendedMinOperatingV 16254;
BA_ "SigType" SG_ 2566558206 NomV 1;
BA_ "SPN" SG_ 2566558206 NomV 16253;
BA_ "SigType" SG_ 2633666814 TotalEnergyOut 1;
BA_ "SPN" SG_ 2633666814 TotalEnergyOut 16252;
BA_ "SigType" SG_ 2633666814 TotalEnergyInput 1;
BA_ "SPN" SG_ 2633666814 TotalEnergyInput 16251;
BA_ "SigType" SG_ 2633666814 TotalAccumulatedCharge 1;
BA_ "SPN" SG_ 2633666814 TotalAccumulatedCharge 16250;
BA_ "SigType" SG_ 2633666814 TotalEnergyThroughput 1;
BA_ "SPN" SG_ 2633666814 TotalEnergyThroughput 16249;
BA_ "SigType" SG_ 2633666814 ContactorOpenUnderLoadCount 1;
BA_ "SPN" SG_ 2633666814 ContactorOpenUnderLoadCount 16248;
BA_ "SigType" SG_ 2633666814 StOfHealth 1;
BA_ "SPN" SG_ 2633666814 StOfHealth 16247;
BA_ "SPN" SG_ 2566557694 NomRatedCapacity 16120;
BA_ "SigType" SG_ 2566557694 CellMinVLmt 1;
BA_ "SPN" SG_ 2566557694 CellMinVLmt 16119;
BA_ "SigType" SG_ 2566557694 CellMaxVLmt 1;
BA_ "SPN" SG_ 2566557694 CellMaxVLmt 16118;
BA_ "SigType" SG_ 2566557694 RecommendedMinOperatingTemp 1;
BA_ "SPN" SG_ 2566557694 RecommendedMinOperatingTemp 16117;
BA_ "SigType" SG_ 2566557694 RecommendedMaxOperatingTemp 1;
BA_ "SPN" SG_ 2566557694 RecommendedMaxOperatingTemp 16116;
BA_ "SigType" SG_ 2566557694 RecommendedMaxStOfCharge 1;
BA_ "SPN" SG_ 2566557694 RecommendedMaxStOfCharge 16115;
BA_ "SigType" SG_ 2566557694 RecommendedMinStOfCharge 1;
BA_ "SPN" SG_ 2566557694 RecommendedMinStOfCharge 16114;
BA_ "SigType" SG_ 2566557694 RecommendedMaxOperatingV 1;
BA_ "SPN" SG_ 2566557694 RecommendedMaxOperatingV 16113;
BA_ "SigType" SG_ 2566557694 RecommendedMinOperatingV 1;
BA_ "SPN" SG_ 2566557694 RecommendedMinOperatingV 16112;
BA_ "SigType" SG_ 2566557694 NomV 1;
BA_ "SPN" SG_ 2566557694 NomV 16111;
BA_ "SigType" SG_ 2633666302 TotalEnergyOut 1;
BA_ "SPN" SG_ 2633666302 TotalEnergyOut 16110;
BA_ "SigType" SG_ 2633666302 TotalEnergyInput 1;
BA_ "SPN" SG_ 2633666302 TotalEnergyInput 16109;
BA_ "SigType" SG_ 2633666302 TotalAccumulatedCharge 1;
BA_ "SPN" SG_ 2633666302 TotalAccumulatedCharge 16108;
BA_ "SigType" SG_ 2633666302 TotalEnergyThroughput 1;
BA_ "SPN" SG_ 2633666302 TotalEnergyThroughput 16107;
BA_ "SigType" SG_ 2633666302 ContactorOpenUnderLoadCount 1;
BA_ "SPN" SG_ 2633666302 ContactorOpenUnderLoadCount 16106;
BA_ "SigType" SG_ 2633666302 StOfHealth 1;
BA_ "SPN" SG_ 2633666302 StOfHealth 16105;
BA_ "SPN" SG_ 2566557182 NomRatedCapacity 15978;
BA_ "SigType" SG_ 2566557182 CellMinVLmt 1;
BA_ "SPN" SG_ 2566557182 CellMinVLmt 15977;
BA_ "SigType" SG_ 2566557182 CellMaxVLmt 1;
BA_ "SPN" SG_ 2566557182 CellMaxVLmt 15976;
BA_ "SigType" SG_ 2566557182 RecommendedMinOperatingTemp 1;
BA_ "SPN" SG_ 2566557182 RecommendedMinOperatingTemp 15975;
BA_ "SigType" SG_ 2566557182 RecommendedMaxOperatingTemp 1;
BA_ "SPN" SG_ 2566557182 RecommendedMaxOperatingTemp 15974;
BA_ "SigType" SG_ 2566557182 RecommendedMaxStOfCharge 1;
BA_ "SPN" SG_ 2566557182 RecommendedMaxStOfCharge 15973;
BA_ "SigType" SG_ 2566557182 RecommendedMinStOfCharge 1;
BA_ "SPN" SG_ 2566557182 RecommendedMinStOfCharge 15972;
BA_ "SigType" SG_ 2566557182 RecommendedMaxOperatingV 1;
BA_ "SPN" SG_ 2566557182 RecommendedMaxOperatingV 15971;
BA_ "SigType" SG_ 2566557182 RecommendedMinOperatingV 1;
BA_ "SPN" SG_ 2566557182 RecommendedMinOperatingV 15970;
BA_ "SigType" SG_ 2566557182 NomV 1;
BA_ "SPN" SG_ 2566557182 NomV 15969;
BA_ "SigType" SG_ 2633665790 TotalEnergyOut 1;
BA_ "SPN" SG_ 2633665790 TotalEnergyOut 15968;
BA_ "SigType" SG_ 2633665790 TotalEnergyInput 1;
BA_ "SPN" SG_ 2633665790 TotalEnergyInput 15967;
BA_ "SigType" SG_ 2633665790 TotalAccumulatedCharge 1;
BA_ "SPN" SG_ 2633665790 TotalAccumulatedCharge 15966;
BA_ "SigType" SG_ 2633665790 TotalEnergyThroughput 1;
BA_ "SPN" SG_ 2633665790 TotalEnergyThroughput 15965;
BA_ "SigType" SG_ 2633665790 ContactorOpenUnderLoadCount 1;
BA_ "SPN" SG_ 2633665790 ContactorOpenUnderLoadCount 15964;
BA_ "SigType" SG_ 2633665790 StOfHealth 1;
BA_ "SPN" SG_ 2633665790 StOfHealth 15963;
BA_ "SPN" SG_ 2566556670 NomRatedCapacity 15836;
BA_ "SigType" SG_ 2566556670 CellMinVLmt 1;
BA_ "SPN" SG_ 2566556670 CellMinVLmt 15835;
BA_ "SigType" SG_ 2566556670 CellMaxVLmt 1;
BA_ "SPN" SG_ 2566556670 CellMaxVLmt 15834;
BA_ "SigType" SG_ 2566556670 RecommendedMinOperatingTemp 1;
BA_ "SPN" SG_ 2566556670 RecommendedMinOperatingTemp 15833;
BA_ "SigType" SG_ 2566556670 RecommendedMaxOperatingTemp 1;
BA_ "SPN" SG_ 2566556670 RecommendedMaxOperatingTemp 15832;
BA_ "SigType" SG_ 2566556670 RecommendedMaxStOfCharge 1;
BA_ "SPN" SG_ 2566556670 RecommendedMaxStOfCharge 15831;
BA_ "SigType" SG_ 2566556670 RecommendedMinStOfCharge 1;
BA_ "SPN" SG_ 2566556670 RecommendedMinStOfCharge 15830;
BA_ "SigType" SG_ 2566556670 RecommendedMaxOperatingV 1;
BA_ "SPN" SG_ 2566556670 RecommendedMaxOperatingV 15829;
BA_ "SigType" SG_ 2566556670 RecommendedMinOperatingV 1;
BA_ "SPN" SG_ 2566556670 RecommendedMinOperatingV 15828;
BA_ "SigType" SG_ 2566556670 NomV 1;
BA_ "SPN" SG_ 2566556670 NomV 15827;
BA_ "SigType" SG_ 2633665278 TotalEnergyOut 1;
BA_ "SPN" SG_ 2633665278 TotalEnergyOut 15826;
BA_ "SigType" SG_ 2633665278 TotalEnergyInput 1;
BA_ "SPN" SG_ 2633665278 TotalEnergyInput 15825;
BA_ "SigType" SG_ 2633665278 TotalAccumulatedCharge 1;
BA_ "SPN" SG_ 2633665278 TotalAccumulatedCharge 15824;
BA_ "SigType" SG_ 2633665278 TotalEnergyThroughput 1;
BA_ "SPN" SG_ 2633665278 TotalEnergyThroughput 15823;
BA_ "SigType" SG_ 2633665278 ContactorOpenUnderLoadCount 1;
BA_ "SPN" SG_ 2633665278 ContactorOpenUnderLoadCount 15822;
BA_ "SigType" SG_ 2633665278 StOfHealth 1;
BA_ "SPN" SG_ 2633665278 StOfHealth 15821;
BA_ "SPN" SG_ 2566556158 NomRatedCapacity 15694;
BA_ "SigType" SG_ 2566556158 CellMinVLmt 1;
BA_ "SPN" SG_ 2566556158 CellMinVLmt 15693;
BA_ "SigType" SG_ 2566556158 CellMaxVLmt 1;
BA_ "SPN" SG_ 2566556158 CellMaxVLmt 15692;
BA_ "SigType" SG_ 2566556158 RecommendedMinOperatingTemp 1;
BA_ "SPN" SG_ 2566556158 RecommendedMinOperatingTemp 15691;
BA_ "SigType" SG_ 2566556158 RecommendedMaxOperatingTemp 1;
BA_ "SPN" SG_ 2566556158 RecommendedMaxOperatingTemp 15690;
BA_ "SigType" SG_ 2566556158 RecommendedMaxStOfCharge 1;
BA_ "SPN" SG_ 2566556158 RecommendedMaxStOfCharge 15689;
BA_ "SigType" SG_ 2566556158 RecommendedMinStOfCharge 1;
BA_ "SPN" SG_ 2566556158 RecommendedMinStOfCharge 15688;
BA_ "SigType" SG_ 2566556158 RecommendedMaxOperatingV 1;
BA_ "SPN" SG_ 2566556158 RecommendedMaxOperatingV 15687;
BA_ "SigType" SG_ 2566556158 RecommendedMinOperatingV 1;
BA_ "SPN" SG_ 2566556158 RecommendedMinOperatingV 15686;
BA_ "SigType" SG_ 2566556158 NomV 1;
BA_ "SPN" SG_ 2566556158 NomV 15685;
BA_ "SigType" SG_ 2633664766 TotalEnergyOut 1;
BA_ "SPN" SG_ 2633664766 TotalEnergyOut 15684;
BA_ "SigType" SG_ 2633664766 TotalEnergyInput 1;
BA_ "SPN" SG_ 2633664766 TotalEnergyInput 15683;
BA_ "SigType" SG_ 2633664766 TotalAccumulatedCharge 1;
BA_ "SPN" SG_ 2633664766 TotalAccumulatedCharge 15682;
BA_ "SigType" SG_ 2633664766 TotalEnergyThroughput 1;
BA_ "SPN" SG_ 2633664766 TotalEnergyThroughput 15681;
BA_ "SigType" SG_ 2633664766 ContactorOpenUnderLoadCount 1;
BA_ "SPN" SG_ 2633664766 ContactorOpenUnderLoadCount 15680;
BA_ "SigType" SG_ 2633664766 StOfHealth 1;
BA_ "SPN" SG_ 2633664766 StOfHealth 15679;
BA_ "SPN" SG_ 2566555646 NomRatedCapacity 15552;
BA_ "SigType" SG_ 2566555646 CellMinVLmt 1;
BA_ "SPN" SG_ 2566555646 CellMinVLmt 15551;
BA_ "SigType" SG_ 2566555646 CellMaxVLmt 1;
BA_ "SPN" SG_ 2566555646 CellMaxVLmt 15550;
BA_ "SigType" SG_ 2566555646 RecommendedMinOperatingTemp 1;
BA_ "SPN" SG_ 2566555646 RecommendedMinOperatingTemp 15549;
BA_ "SigType" SG_ 2566555646 RecommendedMaxOperatingTemp 1;
BA_ "SPN" SG_ 2566555646 RecommendedMaxOperatingTemp 15548;
BA_ "SigType" SG_ 2566555646 RecommendedMaxStOfCharge 1;
BA_ "SPN" SG_ 2566555646 RecommendedMaxStOfCharge 15547;
BA_ "SigType" SG_ 2566555646 RecommendedMinStOfCharge 1;
BA_ "SPN" SG_ 2566555646 RecommendedMinStOfCharge 15546;
BA_ "SigType" SG_ 2566555646 RecommendedMaxOperatingV 1;
BA_ "SPN" SG_ 2566555646 RecommendedMaxOperatingV 15545;
BA_ "SigType" SG_ 2566555646 RecommendedMinOperatingV 1;
BA_ "SPN" SG_ 2566555646 RecommendedMinOperatingV 15544;
BA_ "SigType" SG_ 2566555646 NomV 1;
BA_ "SPN" SG_ 2566555646 NomV 15543;
BA_ "SigType" SG_ 2633664254 TotalEnergyOut 1;
BA_ "SPN" SG_ 2633664254 TotalEnergyOut 15542;
BA_ "SigType" SG_ 2633664254 TotalEnergyInput 1;
BA_ "SPN" SG_ 2633664254 TotalEnergyInput 15541;
BA_ "SigType" SG_ 2633664254 TotalAccumulatedCharge 1;
BA_ "SPN" SG_ 2633664254 TotalAccumulatedCharge 15540;
BA_ "SigType" SG_ 2633664254 TotalEnergyThroughput 1;
BA_ "SPN" SG_ 2633664254 TotalEnergyThroughput 15539;
BA_ "SigType" SG_ 2633664254 ContactorOpenUnderLoadCount 1;
BA_ "SPN" SG_ 2633664254 ContactorOpenUnderLoadCount 15538;
BA_ "SigType" SG_ 2633664254 StOfHealth 1;
BA_ "SPN" SG_ 2633664254 StOfHealth 15537;
BA_ "SPN" SG_ 2566555134 NomRatedCapacity 15410;
BA_ "SigType" SG_ 2566555134 CellMinVLmt 1;
BA_ "SPN" SG_ 2566555134 CellMinVLmt 15409;
BA_ "SigType" SG_ 2566555134 CellMaxVLmt 1;
BA_ "SPN" SG_ 2566555134 CellMaxVLmt 15408;
BA_ "SigType" SG_ 2566555134 RecommendedMinOperatingTemp 1;
BA_ "SPN" SG_ 2566555134 RecommendedMinOperatingTemp 15407;
BA_ "SigType" SG_ 2566555134 RecommendedMaxOperatingTemp 1;
BA_ "SPN" SG_ 2566555134 RecommendedMaxOperatingTemp 15406;
BA_ "SigType" SG_ 2566555134 RecommendedMaxStOfCharge 1;
BA_ "SPN" SG_ 2566555134 RecommendedMaxStOfCharge 15405;
BA_ "SigType" SG_ 2566555134 RecommendedMinStOfCharge 1;
BA_ "SPN" SG_ 2566555134 RecommendedMinStOfCharge 15404;
BA_ "SigType" SG_ 2566555134 RecommendedMaxOperatingV 1;
BA_ "SPN" SG_ 2566555134 RecommendedMaxOperatingV 15403;
BA_ "SigType" SG_ 2566555134 RecommendedMinOperatingV 1;
BA_ "SPN" SG_ 2566555134 RecommendedMinOperatingV 15402;
BA_ "SigType" SG_ 2566555134 NomV 1;
BA_ "SPN" SG_ 2566555134 NomV 15401;
BA_ "SigType" SG_ 2633663742 TotalEnergyOut 1;
BA_ "SPN" SG_ 2633663742 TotalEnergyOut 15400;
BA_ "SigType" SG_ 2633663742 TotalEnergyInput 1;
BA_ "SPN" SG_ 2633663742 TotalEnergyInput 15399;
BA_ "SigType" SG_ 2633663742 TotalAccumulatedCharge 1;
BA_ "SPN" SG_ 2633663742 TotalAccumulatedCharge 15398;
BA_ "SigType" SG_ 2633663742 TotalEnergyThroughput 1;
BA_ "SPN" SG_ 2633663742 TotalEnergyThroughput 15397;
BA_ "SigType" SG_ 2633663742 ContactorOpenUnderLoadCount 1;
BA_ "SPN" SG_ 2633663742 ContactorOpenUnderLoadCount 15396;
BA_ "SigType" SG_ 2633663742 StOfHealth 1;
BA_ "SPN" SG_ 2633663742 StOfHealth 15395;
BA_ "SigType" SG_ 2566554622 ElectricPumpOperatingStatus 4;
BA_ "SPN" SG_ 2566554622 ElectricPumpOperatingStatus 20183;
BA_ "SigType" SG_ 2566554622 ElectricPumpServiceInd 4;
BA_ "SPN" SG_ 2566554622 ElectricPumpServiceInd 20182;
BA_ "SigType" SG_ 2566554622 ElectricPumpPwr 1;
BA_ "SPN" SG_ 2566554622 ElectricPumpPwr 20181;
BA_ "SigType" SG_ 2566554622 ElectricPumpCtrlTemp 1;
BA_ "SPN" SG_ 2566554622 ElectricPumpCtrlTemp 20180;
BA_ "SigType" SG_ 2566554622 ElectricPumpMotorSpd 1;
BA_ "SPN" SG_ 2566554622 ElectricPumpMotorSpd 20179;
BA_ "SigType" SG_ 2566554622 ElectricPumpCtrlCmdStatus 4;
BA_ "SPN" SG_ 2566554622 ElectricPumpCtrlCmdStatus 20176;
BA_ "SPN" SG_ 2566554622 ElectricPumpCtrlStatusReason 20177;
BA_ "SigType" SG_ 2566554622 ElectricPumpEnableStatus 4;
BA_ "SPN" SG_ 2566554622 ElectricPumpEnableStatus 20178;
BA_ "SigType" SG_ 2566554366 TwoPhaseWTemp 1;
BA_ "SPN" SG_ 2566554366 TwoPhaseWTemp 20736;
BA_ "SigType" SG_ 2566554366 TwoPhaseVTemp 1;
BA_ "SPN" SG_ 2566554366 TwoPhaseVTemp 20735;
BA_ "SigType" SG_ 2566554366 TwoPhaseUTemp 1;
BA_ "SPN" SG_ 2566554366 TwoPhaseUTemp 20734;
BA_ "SigType" SG_ 2566554366 OnePhaseWTemp 1;
BA_ "SPN" SG_ 2566554366 OnePhaseWTemp 20733;
BA_ "SigType" SG_ 2566554366 OnePhaseVTemp 1;
BA_ "SPN" SG_ 2566554366 OnePhaseVTemp 20732;
BA_ "SigType" SG_ 2566554366 OnePhaseUTemp 1;
BA_ "SPN" SG_ 2566554366 OnePhaseUTemp 20731;
BA_ "SigType" SG_ 2365227518 TwoPwrConvPwrModuleSwTemp 1;
BA_ "SPN" SG_ 2365227518 TwoPwrConvPwrModuleSwTemp 20730;
BA_ "SigType" SG_ 2365227518 OnePwrConvPwrModuleSwTemp 1;
BA_ "SPN" SG_ 2365227518 OnePwrConvPwrModuleSwTemp 20729;
BA_ "SigType" SG_ 2365227518 TwoPwrConvACCurOut 1;
BA_ "SPN" SG_ 2365227518 TwoPwrConvACCurOut 20728;
BA_ "SigType" SG_ 2365227518 OnePwrConvACCurOut 1;
BA_ "SPN" SG_ 2365227518 OnePwrConvACCurOut 20727;
BA_ "SigType" SG_ 2365227262 ConvPhaseWPwrModuleSwPwrSupplyV 1;
BA_ "SPN" SG_ 2365227262 ConvPhaseWPwrModuleSwPwrSupplyV 20726;
BA_ "SigType" SG_ 2365227262 ConvPhaseVPwrModuleSwPwrSupplyV 1;
BA_ "SPN" SG_ 2365227262 ConvPhaseVPwrModuleSwPwrSupplyV 20725;
BA_ "SigType" SG_ 2365227262 ConvPhaseUPwrModuleSwPwrSupplyV 1;
BA_ "SPN" SG_ 2365227262 ConvPhaseUPwrModuleSwPwrSupplyV 20724;
BA_ "SigType" SG_ 2365227006 ConvPhaseWPwrModuleSwPwrSupplyV 1;
BA_ "SPN" SG_ 2365227006 ConvPhaseWPwrModuleSwPwrSupplyV 20723;
BA_ "SigType" SG_ 2365227006 ConvPhaseVPwrModuleSwPwrSupplyV 1;
BA_ "SPN" SG_ 2365227006 ConvPhaseVPwrModuleSwPwrSupplyV 20722;
BA_ "SigType" SG_ 2365227006 ConvPhaseUPwrModuleSwPwrSupplyV 1;
BA_ "SPN" SG_ 2365227006 ConvPhaseUPwrModuleSwPwrSupplyV 20721;
BA_ "SigType" SG_ 2566553342 TwoPwrConvPhaseWPwrModuleSwTemp 1;
BA_ "SPN" SG_ 2566553342 TwoPwrConvPhaseWPwrModuleSwTemp 20720;
BA_ "SigType" SG_ 2566553342 TwoPwrConvPhaseVPwrModuleSwTemp 1;
BA_ "SPN" SG_ 2566553342 TwoPwrConvPhaseVPwrModuleSwTemp 20719;
BA_ "SigType" SG_ 2566553342 TwoPwrConvPhaseUPwrModuleSwTemp 1;
BA_ "SPN" SG_ 2566553342 TwoPwrConvPhaseUPwrModuleSwTemp 20718;
BA_ "SigType" SG_ 2566553342 OnePwrConvPhaseWPwrModuleSwTemp 1;
BA_ "SPN" SG_ 2566553342 OnePwrConvPhaseWPwrModuleSwTemp 20717;
BA_ "SigType" SG_ 2566553342 OnePwrConvPhaseVPwrModuleSwTemp 1;
BA_ "SPN" SG_ 2566553342 OnePwrConvPhaseVPwrModuleSwTemp 20716;
BA_ "SigType" SG_ 2566553342 OnePwrConvPhaseUPwrModuleSwTemp 1;
BA_ "SPN" SG_ 2566553342 OnePwrConvPhaseUPwrModuleSwTemp 20715;
BA_ "SigType" SG_ 2365226494 PwrConvPhaseWV 1;
BA_ "SPN" SG_ 2365226494 PwrConvPhaseWV 20714;
BA_ "SigType" SG_ 2365226494 PwrConvPhaseVV 1;
BA_ "SPN" SG_ 2365226494 PwrConvPhaseVV 20713;
BA_ "SigType" SG_ 2365226494 PwrConvPhaseUV 1;
BA_ "SPN" SG_ 2365226494 PwrConvPhaseUV 20712;
BA_ "SigType" SG_ 2365226238 PwrConvPhaseWV 1;
BA_ "SPN" SG_ 2365226238 PwrConvPhaseWV 20711;
BA_ "SigType" SG_ 2365226238 PwrConvPhaseVV 1;
BA_ "SPN" SG_ 2365226238 PwrConvPhaseVV 20710;
BA_ "SigType" SG_ 2365226238 PwrConvPhaseUV 1;
BA_ "SPN" SG_ 2365226238 PwrConvPhaseUV 20709;
BA_ "SigType" SG_ 2365225982 PwrConvPhaseWCur 1;
BA_ "SPN" SG_ 2365225982 PwrConvPhaseWCur 20708;
BA_ "SigType" SG_ 2365225982 PwrConvPhaseVCur 1;
BA_ "SPN" SG_ 2365225982 PwrConvPhaseVCur 20707;
BA_ "SigType" SG_ 2365225982 PwrConvPhaseUCur 1;
BA_ "SPN" SG_ 2365225982 PwrConvPhaseUCur 20706;
BA_ "SigType" SG_ 2365225726 PwrConvPhaseWCur 1;
BA_ "SPN" SG_ 2365225726 PwrConvPhaseWCur 20705;
BA_ "SigType" SG_ 2365225726 PwrConvPhaseVCur 1;
BA_ "SPN" SG_ 2365225726 PwrConvPhaseVCur 20704;
BA_ "SigType" SG_ 2365225726 PwrConvPhaseUCur 1;
BA_ "SPN" SG_ 2365225726 PwrConvPhaseUCur 20703;
BA_ "SigType" SG_ 2365225470 Pwr 1;
BA_ "SPN" SG_ 2365225470 Pwr 20702;
BA_ "SigType" SG_ 2365225470 Freq 1;
BA_ "SPN" SG_ 2365225470 Freq 20701;
BA_ "SigType" SG_ 2365225470 Cur 1;
BA_ "SPN" SG_ 2365225470 Cur 20700;
BA_ "SigType" SG_ 2365225470 Counter 11;
BA_ "SPN" SG_ 2365225470 Counter 20699;
BA_ "SigType" SG_ 2365225470 CRC 12;
BA_ "SPN" SG_ 2365225470 CRC 20698;
BA_ "SigType" SG_ 2365225214 V 1;
BA_ "SPN" SG_ 2365225214 V 20691;
BA_ "SigType" SG_ 2365225214 Cur 1;
BA_ "SPN" SG_ 2365225214 Cur 20690;
BA_ "SigType" SG_ 2365225214 Counter 11;
BA_ "SPN" SG_ 2365225214 Counter 20689;
BA_ "SigType" SG_ 2365225214 CRC 12;
BA_ "SPN" SG_ 2365225214 CRC 20688;
BA_ "SigType" SG_ 2566551550 Four 1;
BA_ "SPN" SG_ 2566551550 Four 20687;
BA_ "SigType" SG_ 2566551550 Three 1;
BA_ "SPN" SG_ 2566551550 Three 20686;
BA_ "SigType" SG_ 2566551550 Two 1;
BA_ "SPN" SG_ 2566551550 Two 20685;
BA_ "SigType" SG_ 2566551550 One 1;
BA_ "SPN" SG_ 2566551550 One 20684;
BA_ "SigType" SG_ 2566551294 Four 1;
BA_ "SPN" SG_ 2566551294 Four 20683;
BA_ "SigType" SG_ 2566551294 Three 1;
BA_ "SPN" SG_ 2566551294 Three 20682;
BA_ "SigType" SG_ 2566551294 Two 1;
BA_ "SPN" SG_ 2566551294 Two 20681;
BA_ "SigType" SG_ 2566551294 One 1;
BA_ "SPN" SG_ 2566551294 One 20680;
BA_ "SigType" SG_ 2365224446 V 1;
BA_ "SPN" SG_ 2365224446 V 20679;
BA_ "SigType" SG_ 2365224446 Cur 1;
BA_ "SPN" SG_ 2365224446 Cur 20678;
BA_ "SigType" SG_ 2365224446 Counter 11;
BA_ "SPN" SG_ 2365224446 Counter 20677;
BA_ "SigType" SG_ 2365224446 CRC 12;
BA_ "SPN" SG_ 2365224446 CRC 20676;
BA_ "SigType" SG_ 2365224190 Pwr 1;
BA_ "SPN" SG_ 2365224190 Pwr 20669;
BA_ "SigType" SG_ 2365224190 Freq 1;
BA_ "SPN" SG_ 2365224190 Freq 20668;
BA_ "SigType" SG_ 2365224190 Cur 1;
BA_ "SPN" SG_ 2365224190 Cur 20667;
BA_ "SigType" SG_ 2365224190 Counter 11;
BA_ "SPN" SG_ 2365224190 Counter 20666;
BA_ "SigType" SG_ 2365224190 CRC 12;
BA_ "SPN" SG_ 2365224190 CRC 20665;
BA_ "SigType" SG_ 2566550526 CurLimDueToMachineCharac 4;
BA_ "SPN" SG_ 2566550526 CurLimDueToMachineCharac 20657;
BA_ "SigType" SG_ 2566550526 PLedDueToActiveCurRateLmt 4;
BA_ "SPN" SG_ 2566550526 PLedDueToActiveCurRateLmt 20656;
BA_ "SigType" SG_ 2566550526 PLedDueToFaultCondition 4;
BA_ "SPN" SG_ 2566550526 PLedDueToFaultCondition 20655;
BA_ "SigType" SG_ 2566550526 PLedDueToTemp 4;
BA_ "SPN" SG_ 2566550526 PLedDueToTemp 20654;
BA_ "SigType" SG_ 2566550526 PLedDueToInvTemp 4;
BA_ "SPN" SG_ 2566550526 PLedDueToInvTemp 20653;
BA_ "SigType" SG_ 2566550526 PLedDueToFreqMin 4;
BA_ "SPN" SG_ 2566550526 PLedDueToFreqMin 20652;
BA_ "SigType" SG_ 2566550526 PLedDueToFreqMax 4;
BA_ "SPN" SG_ 2566550526 PLedDueToFreqMax 20651;
BA_ "SigType" SG_ 2566550526 PLedDueToCurMin 4;
BA_ "SPN" SG_ 2566550526 PLedDueToCurMin 20650;
BA_ "SigType" SG_ 2566550526 PLedDueToCurMax 4;
BA_ "SPN" SG_ 2566550526 PLedDueToCurMax 20649;
BA_ "SigType" SG_ 2566550526 PLedDueToDCES1PwrMin 4;
BA_ "SPN" SG_ 2566550526 PLedDueToDCES1PwrMin 20648;
BA_ "SigType" SG_ 2566550526 PLedDueToDCES1PwrMax 4;
BA_ "SPN" SG_ 2566550526 PLedDueToDCES1PwrMax 20647;
BA_ "SigType" SG_ 2566550526 PLedDueToElectricalPwrMin 4;
BA_ "SPN" SG_ 2566550526 PLedDueToElectricalPwrMin 20646;
BA_ "SigType" SG_ 2566550526 PLedDueToElectricalPwrMax 4;
BA_ "SPN" SG_ 2566550526 PLedDueToElectricalPwrMax 20645;
BA_ "SigType" SG_ 2566550526 PLedDueToDCES1VMin 4;
BA_ "SPN" SG_ 2566550526 PLedDueToDCES1VMin 20644;
BA_ "SigType" SG_ 2566550526 PLedDueToDCES1VMax 4;
BA_ "SPN" SG_ 2566550526 PLedDueToDCES1VMax 20643;
BA_ "SigType" SG_ 2566550526 PLedDueToDCES1CurMin 4;
BA_ "SPN" SG_ 2566550526 PLedDueToDCES1CurMin 20642;
BA_ "SigType" SG_ 2566550526 PLedDueToDCES1CurMax 4;
BA_ "SPN" SG_ 2566550526 PLedDueToDCES1CurMax 20641;
BA_ "SigType" SG_ 2566550526 PLedDueToUndefinedReason 4;
BA_ "SPN" SG_ 2566550526 PLedDueToUndefinedReason 20640;
BA_ "SigType" SG_ 2566550270 CurLimDueToMachineCharac 4;
BA_ "SPN" SG_ 2566550270 CurLimDueToMachineCharac 20632;
BA_ "SigType" SG_ 2566550270 PLedDueToActiveCurRateLmt 4;
BA_ "SPN" SG_ 2566550270 PLedDueToActiveCurRateLmt 20631;
BA_ "SigType" SG_ 2566550270 PLedDueToFaultCondition 4;
BA_ "SPN" SG_ 2566550270 PLedDueToFaultCondition 20630;
BA_ "SigType" SG_ 2566550270 PLedDueToTemp 4;
BA_ "SPN" SG_ 2566550270 PLedDueToTemp 20629;
BA_ "SigType" SG_ 2566550270 PLedDueToInvTemp 4;
BA_ "SPN" SG_ 2566550270 PLedDueToInvTemp 20628;
BA_ "SigType" SG_ 2566550270 PLedDueToFreqMin 4;
BA_ "SPN" SG_ 2566550270 PLedDueToFreqMin 20627;
BA_ "SigType" SG_ 2566550270 PLedDueToFreqMax 4;
BA_ "SPN" SG_ 2566550270 PLedDueToFreqMax 20626;
BA_ "SigType" SG_ 2566550270 PLedDueToCurMin 4;
BA_ "SPN" SG_ 2566550270 PLedDueToCurMin 20625;
BA_ "SigType" SG_ 2566550270 PLedDueToCurMax 4;
BA_ "SPN" SG_ 2566550270 PLedDueToCurMax 20624;
BA_ "SigType" SG_ 2566550270 PLedDueToDCES1PwrMin 4;
BA_ "SPN" SG_ 2566550270 PLedDueToDCES1PwrMin 20623;
BA_ "SigType" SG_ 2566550270 PLedDueToDCES1PwrMax 4;
BA_ "SPN" SG_ 2566550270 PLedDueToDCES1PwrMax 20622;
BA_ "SigType" SG_ 2566550270 PLedDueToElectricalPwrMin 4;
BA_ "SPN" SG_ 2566550270 PLedDueToElectricalPwrMin 20621;
BA_ "SigType" SG_ 2566550270 PLedDueToElectricalPwrMax 4;
BA_ "SPN" SG_ 2566550270 PLedDueToElectricalPwrMax 20620;
BA_ "SigType" SG_ 2566550270 PLedDueToDCES1VMin 4;
BA_ "SPN" SG_ 2566550270 PLedDueToDCES1VMin 20619;
BA_ "SigType" SG_ 2566550270 PLedDueToDCES1VMax 4;
BA_ "SPN" SG_ 2566550270 PLedDueToDCES1VMax 20618;
BA_ "SigType" SG_ 2566550270 PLedDueToDCES1CurMin 4;
BA_ "SPN" SG_ 2566550270 PLedDueToDCES1CurMin 20617;
BA_ "SigType" SG_ 2566550270 PLedDueToDCES1CurMax 4;
BA_ "SPN" SG_ 2566550270 PLedDueToDCES1CurMax 20616;
BA_ "SigType" SG_ 2566550270 PLedDueToUndefinedReason 4;
BA_ "SPN" SG_ 2566550270 PLedDueToUndefinedReason 20615;
BA_ "SigType" SG_ 2566550014 PwrConv2TotalChargeGenerated 1;
BA_ "SPN" SG_ 2566550014 PwrConv2TotalChargeGenerated 20614;
BA_ "SigType" SG_ 2566550014 PwrConv2TotalChargeConsumed 1;
BA_ "SPN" SG_ 2566550014 PwrConv2TotalChargeConsumed 20613;
BA_ "SigType" SG_ 2566550014 PwrConv2TotalEnergyGenerated 1;
BA_ "SPN" SG_ 2566550014 PwrConv2TotalEnergyGenerated 20612;
BA_ "SigType" SG_ 2566550014 PwrConv2TotalEnergyConsumed 1;
BA_ "SPN" SG_ 2566550014 PwrConv2TotalEnergyConsumed 20611;
BA_ "SigType" SG_ 2566549758 PwrConv1TotalChargeGenerated 1;
BA_ "SPN" SG_ 2566549758 PwrConv1TotalChargeGenerated 20610;
BA_ "SigType" SG_ 2566549758 PwrConv1TotalChargeConsumed 1;
BA_ "SPN" SG_ 2566549758 PwrConv1TotalChargeConsumed 20609;
BA_ "SigType" SG_ 2566549758 PwrConv1TotalEnergyGenerated 1;
BA_ "SPN" SG_ 2566549758 PwrConv1TotalEnergyGenerated 20608;
BA_ "SigType" SG_ 2566549758 PwrConv1TotalEnergyConsumed 1;
BA_ "SPN" SG_ 2566549758 PwrConv1TotalEnergyConsumed 20607;
BA_ "SPN" SG_ 2566549502 DCES1PwrMin 20542;
BA_ "SPN" SG_ 2566549502 DCES1PwrMax 20541;
BA_ "SPN" SG_ 2566549502 ElectricalPwrMin 20540;
BA_ "SPN" SG_ 2566549502 ElectricalPwrMax 20539;
BA_ "SigType" SG_ 2566549502 Counter 11;
BA_ "SPN" SG_ 2566549502 Counter 20538;
BA_ "SigType" SG_ 2566549502 CRC 12;
BA_ "SPN" SG_ 2566549502 CRC 20537;
BA_ "SPN" SG_ 2566549246 FreqMin 20536;
BA_ "SPN" SG_ 2566549246 FreqMax 20535;
BA_ "SPN" SG_ 2566549246 CurMin 20534;
BA_ "SPN" SG_ 2566549246 CurMax 20533;
BA_ "SigType" SG_ 2566549246 Counter 11;
BA_ "SPN" SG_ 2566549246 Counter 20532;
BA_ "SigType" SG_ 2566549246 CRC 12;
BA_ "SPN" SG_ 2566549246 CRC 20531;
BA_ "SPN" SG_ 2566548990 CurMin 20530;
BA_ "SPN" SG_ 2566548990 CurMax 20529;
BA_ "SPN" SG_ 2566548990 VMin 20528;
BA_ "SPN" SG_ 2566548990 VMax 20527;
BA_ "SigType" SG_ 2566548990 Counter 11;
BA_ "SPN" SG_ 2566548990 Counter 20526;
BA_ "SigType" SG_ 2566548990 CRC 12;
BA_ "SPN" SG_ 2566548990 CRC 20525;
BA_ "SPN" SG_ 2566548734 CurMin 20524;
BA_ "SPN" SG_ 2566548734 CurMax 20523;
BA_ "SPN" SG_ 2566548734 VMin 20522;
BA_ "SPN" SG_ 2566548734 VMax 20521;
BA_ "SigType" SG_ 2566548734 Counter 11;
BA_ "SPN" SG_ 2566548734 Counter 20520;
BA_ "SigType" SG_ 2566548734 CRC 12;
BA_ "SPN" SG_ 2566548734 CRC 20519;
BA_ "SPN" SG_ 2566548478 FreqMin 20518;
BA_ "SPN" SG_ 2566548478 FreqMax 20517;
BA_ "SPN" SG_ 2566548478 CurMin 20516;
BA_ "SPN" SG_ 2566548478 CurMax 20515;
BA_ "SigType" SG_ 2566548478 Counter 11;
BA_ "SPN" SG_ 2566548478 Counter 20514;
BA_ "SigType" SG_ 2566548478 CRC 12;
BA_ "SPN" SG_ 2566548478 CRC 20513;
BA_ "SPN" SG_ 2566548222 DCES1PwrMin 20512;
BA_ "SPN" SG_ 2566548222 DCES1PwrMax 20511;
BA_ "SPN" SG_ 2566548222 ElectricalPwrMin 20510;
BA_ "SPN" SG_ 2566548222 ElectricalPwrMax 20509;
BA_ "SigType" SG_ 2566548222 Counter 11;
BA_ "SPN" SG_ 2566548222 Counter 20508;
BA_ "SigType" SG_ 2566548222 CRC 12;
BA_ "SPN" SG_ 2566548222 CRC 20507;
BA_ "SigType" SG_ 2566547966 HVBusLowSideResistorConnectReq 5;
BA_ "SPN" SG_ 2566547966 HVBusLowSideResistorConnectReq 20506;
BA_ "SigType" SG_ 2566547966 HVBusHiSideResistorConnectReq 5;
BA_ "SPN" SG_ 2566547966 HVBusHiSideResistorConnectReq 20505;
BA_ "SigType" SG_ 2566547966 HVBusPassiveIsolTestCmd 5;
BA_ "SPN" SG_ 2566547966 HVBusPassiveIsolTestCmd 20504;
BA_ "SigType" SG_ 2566547966 HVBusActiveIsolTestCmd 5;
BA_ "SPN" SG_ 2566547966 HVBusActiveIsolTestCmd 20503;
BA_ "SigType" SG_ 2566547710 HVBusLowSideResistorConnectReq 5;
BA_ "SPN" SG_ 2566547710 HVBusLowSideResistorConnectReq 20502;
BA_ "SigType" SG_ 2566547710 HVBusHiSideResistorConnectReq 5;
BA_ "SPN" SG_ 2566547710 HVBusHiSideResistorConnectReq 20501;
BA_ "SigType" SG_ 2566547710 HVBusPassiveIsolTestCmd 4;
BA_ "SPN" SG_ 2566547710 HVBusPassiveIsolTestCmd 20500;
BA_ "SigType" SG_ 2566547710 HVBusActiveIsolTestCmd 4;
BA_ "SPN" SG_ 2566547710 HVBusActiveIsolTestCmd 20499;
BA_ "SigType" SG_ 2633656318 HydOilRes 1;
BA_ "SPN" SG_ 2633656318 HydOilRes 20786;
BA_ "SigType" SG_ 2633656318 EngOilRes 1;
BA_ "SPN" SG_ 2633656318 EngOilRes 20785;
BA_ "SigType" SG_ 2566547198 DEFQualityMalfunctionCount 1;
BA_ "SPN" SG_ 2566547198 DEFQualityMalfunctionCount 20793;
BA_ "SigType" SG_ 2566547198 DEFTank1EmptyCount 1;
BA_ "SPN" SG_ 2566547198 DEFTank1EmptyCount 20792;
BA_ "SigType" SG_ 2566546942 DEFFrozenCount 1;
BA_ "SPN" SG_ 2566546942 DEFFrozenCount 20795;
BA_ "SigType" SG_ 2566546942 SCRMalfunctionCount 1;
BA_ "SPN" SG_ 2566546942 SCRMalfunctionCount 20794;
BA_ "SigType" SG_ 2566546686 OneTotalEventCountWithNoDEFDel 1;
BA_ "SPN" SG_ 2566546686 OneTotalEventCountWithNoDEFDel 20797;
BA_ "SigType" SG_ 2566546686 OneSCRInHiTempCount 1;
BA_ "SPN" SG_ 2566546686 OneSCRInHiTempCount 20796;
BA_ "SigType" SG_ 2365219838 TractorHazardLightsCmd 5;
BA_ "SPN" SG_ 2365219838 TractorHazardLightsCmd 20799;
BA_ "SigType" SG_ 2365219838 Data2ReqCmd 5;
BA_ "SPN" SG_ 2365219838 Data2ReqCmd 20798;
BA_ "SigType" SG_ 2566546174 TractorHazardLights 5;
BA_ "SPN" SG_ 2566546174 TractorHazardLights 20800;
BA_ "SigType" SG_ 2566545662 DepTime 1;
BA_ "SPN" SG_ 2566545662 DepTime 21083;
BA_ "SigType" SG_ 2566545662 FullChargeTimeRemaining 1;
BA_ "SPN" SG_ 2566545662 FullChargeTimeRemaining 21082;
BA_ "SigType" SG_ 2566545662 BulkChargeTimeRemaining 1;
BA_ "SPN" SG_ 2566545662 BulkChargeTimeRemaining 21081;
BA_ "SigType" SG_ 2566545662 FullChargingComplete 4;
BA_ "SPN" SG_ 2566545662 FullChargingComplete 21080;
BA_ "SigType" SG_ 2566545662 BulkChargingComplete 4;
BA_ "SPN" SG_ 2566545662 BulkChargingComplete 21079;
BA_ "SigType" SG_ 2566545406 EnergyReq 1;
BA_ "SPN" SG_ 2566545406 EnergyReq 21078;
BA_ "SigType" SG_ 2566545406 EnergyCapacity 1;
BA_ "SPN" SG_ 2566545406 EnergyCapacity 21077;
BA_ "SigType" SG_ 2566545406 FullStOfCharge 1;
BA_ "SPN" SG_ 2566545406 FullStOfCharge 21076;
BA_ "SigType" SG_ 2566545406 BulkStOfCharge 1;
BA_ "SPN" SG_ 2566545406 BulkStOfCharge 21075;
BA_ "SigType" SG_ 2566545150 ProfileEntryStart 1;
BA_ "SPN" SG_ 2566545150 ProfileEntryStart 21074;
BA_ "SigType" SG_ 2566545150 ProfileEntryMaxPwr 1;
BA_ "SPN" SG_ 2566545150 ProfileEntryMaxPwr 21073;
BA_ "SPN" SG_ 2566545150 SelectedScheduleID 21072;
BA_ "SigType" SG_ 2566544894 EntryDur 1;
BA_ "SPN" SG_ 2566544894 EntryDur 21071;
BA_ "SigType" SG_ 2566544894 EntryStartTime 1;
BA_ "SPN" SG_ 2566544894 EntryStartTime 21070;
BA_ "SigType" SG_ 2566544894 EntryPwrMax 1;
BA_ "SPN" SG_ 2566544894 EntryPwrMax 21069;
BA_ "SPN" SG_ 2566544894 PMaxScheduleId 21068;
BA_ "SPN" SG_ 2566544894 ScheduleId 21067;
BA_ "SigType" SG_ 2566544894 MaxScheduleIndex 1;
BA_ "SPN" SG_ 2566544894 MaxScheduleIndex 21066;
BA_ "SigType" SG_ 2566544894 ScheduleIndex 1;
BA_ "SPN" SG_ 2566544894 ScheduleIndex 21065;
BA_ "SPN" SG_ 2566544638 EnergyToBeDelivered 21064;
VAL_ 2566554622 ElectricPumpOperatingStatus 3 "Not Available" 2 "Not Operable" 1 "Derated Operation" 0 "Normal Operation" ;
VAL_ 2566554622 ElectricPumpServiceInd 3 "Not Available" 2 "Reserved" 1 "Service Required" 0 "Service Not Required" ;
VAL_ 2566554622 ElectricPumpCtrlCmdStatus 3 "Not Available" 2 "Default Command" 1 "External Command" 0 "Internal Command" ;
VAL_ 2566554622 ElectricPumpCtrlStatusReason 15 "Not Available" 14 "Reserved" 13 "Reserved" 12 "Reserved" 11 "Reserved" 10 "Reserved" 9 "Exceeding commanded speed due to external force" 8 "Speed limited due to over-temperature protection" 7 "Speed limited due to torque limit" 6 "Speed limited due to maximum system design capability" 5 "Speed Limited due to current" 4 "Over-Temperature Protection Shutdown" 3 "Under-Voltage Protection Shutdown" 2 "Over-Voltage Protection Shutdown" 1 "Unable to Start" 0 "Normal Operation" ;
VAL_ 2566554622 ElectricPumpEnableStatus 3 "Not available" 2 "Motor On, Reverse Direction" 1 "Motor On, Normal" 0 "Motor Off" ;
VAL_ 2566550526 CurLimDueToMachineCharac 3 "Not Available" 2 "Error" 1 "Current limited for this reason" 0 "No current limit for this reason" ;
VAL_ 2566550526 PLedDueToActiveCurRateLmt 3 "Not Available" 2 "Error" 1 "Power limited for this reason" 0 "No power limit for this reason" ;
VAL_ 2566550526 PLedDueToFaultCondition 3 "Not Available" 2 "Error" 1 "Power limited for this reason" 0 "No power limit for this reason" ;
VAL_ 2566550526 PLedDueToTemp 3 "Not Available" 2 "Error" 1 "Power limited for this reason" 0 "No power limit for this reason" ;
VAL_ 2566550526 PLedDueToInvTemp 3 "Not Available" 2 "Error" 1 "Power limited for this reason" 0 "No power limit for this reason" ;
VAL_ 2566550526 PLedDueToFreqMin 3 "Not Available" 2 "Error" 1 "Power limited for this reason" 0 "No power limit for this reason" ;
VAL_ 2566550526 PLedDueToFreqMax 3 "Not Available" 2 "Error" 1 "Power limited for this reason" 0 "No power limit for this reason" ;
VAL_ 2566550526 PLedDueToCurMin 3 "Not Available" 2 "Error" 1 "Power limited for this reason" 0 "No power limit for this reason" ;
VAL_ 2566550526 PLedDueToCurMax 3 "Not Available" 2 "Error" 1 "Power limited for this reason" 0 "No power limit for this reason" ;
VAL_ 2566550526 PLedDueToDCES1PwrMin 3 "Not Available" 2 "Error" 1 "Power limited for this reason" 0 "No power limit for this reason" ;
VAL_ 2566550526 PLedDueToDCES1PwrMax 3 "Not Available" 2 "Error" 1 "Power limited for this reason" 0 "No power limit for this reason" ;
VAL_ 2566550526 PLedDueToElectricalPwrMin 3 "Not Available" 2 "Error" 1 "Power limited for this reason" 0 "No power limit for this reason" ;
VAL_ 2566550526 PLedDueToElectricalPwrMax 3 "Not Available" 2 "Error" 1 "Power limited for this reason" 0 "No power limit for this reason" ;
VAL_ 2566550526 PLedDueToDCES1VMin 3 "Not Available" 2 "Error" 1 "Power limited for this reason" 0 "No power limit for this reason" ;
VAL_ 2566550526 PLedDueToDCES1VMax 3 "Not Available" 2 "Error" 1 "Power limited for this reason" 0 "No power limit for this reason" ;
VAL_ 2566550526 PLedDueToDCES1CurMin 3 "Not Available" 2 "Error" 1 "Power limited for this reason" 0 "No power limit for this reason" ;
VAL_ 2566550526 PLedDueToDCES1CurMax 3 "Not Available" 2 "Error" 1 "Power limited for this reason" 0 "No power limit for this reason" ;
VAL_ 2566550526 PLedDueToUndefinedReason 3 "Not Available" 2 "Error" 1 "Power limited for this reason" 0 "No power limit for this reason" ;
VAL_ 2566550270 CurLimDueToMachineCharac 3 "Not Available" 2 "Error" 1 "Current limited for this reason" 0 "No current limit for this reason" ;
VAL_ 2566550270 PLedDueToActiveCurRateLmt 3 "Not Available" 2 "Error" 1 "Power limited for this reason" 0 "No power limit for this reason" ;
VAL_ 2566550270 PLedDueToFaultCondition 3 "Not Available" 2 "Error" 1 "Power limited for this reason" 0 "No power limit for this reason" ;
VAL_ 2566550270 PLedDueToTemp 3 "Not Available" 2 "Error" 1 "Power limited for this reason" 0 "No power limit for this reason" ;
VAL_ 2566550270 PLedDueToInvTemp 3 "Not Available" 2 "Error" 1 "Power limited for this reason" 0 "No power limit for this reason" ;
VAL_ 2566550270 PLedDueToFreqMin 3 "Not Available" 2 "Error" 1 "Power limited for this reason" 0 "No power limit for this reason" ;
VAL_ 2566550270 PLedDueToFreqMax 3 "Not Available" 2 "Error" 1 "Power limited for this reason" 0 "No power limit for this reason" ;
VAL_ 2566550270 PLedDueToCurMin 3 "Not Available" 2 "Error" 1 "Power limited for this reason" 0 "No power limit for this reason" ;
VAL_ 2566550270 PLedDueToCurMax 3 "Not Available" 2 "Error" 1 "Power limited for this reason" 0 "No power limit for this reason" ;
VAL_ 2566550270 PLedDueToDCES1PwrMin 3 "Not Available" 2 "Error" 1 "Power limited for this reason" 0 "No power limit for this reason" ;
VAL_ 2566550270 PLedDueToDCES1PwrMax 3 "Not Available" 2 "Error" 1 "Power limited for this reason" 0 "No power limit for this reason" ;
VAL_ 2566550270 PLedDueToElectricalPwrMin 3 "Not Available" 2 "Error" 1 "Power limited for this reason" 0 "No power limit for this reason" ;
VAL_ 2566550270 PLedDueToElectricalPwrMax 3 "Not Available" 2 "Error" 1 "Power limited for this reason" 0 "No power limit for this reason" ;
VAL_ 2566550270 PLedDueToDCES1VMin 3 "Not Available" 2 "Error" 1 "Power limited for this reason" 0 "No power limit for this reason" ;
VAL_ 2566550270 PLedDueToDCES1VMax 3 "Not Available" 2 "Error" 1 "Power limited for this reason" 0 "No power limit for this reason" ;
VAL_ 2566550270 PLedDueToDCES1CurMin 3 "Not Available" 2 "Error" 1 "Power limited for this reason" 0 "No power limit for this reason" ;
VAL_ 2566550270 PLedDueToDCES1CurMax 3 "Not Available" 2 "Error" 1 "Power limited for this reason" 0 "No power limit for this reason" ;
VAL_ 2566550270 PLedDueToUndefinedReason 3 "Not Available" 2 "Error" 1 "Power limited for this reason" 0 "No power limit for this reason" ;
VAL_ 2566547966 HVBusLowSideResistorConnectReq 3 "Don't care/take no action" 2 "Reserved" 1 "Connection Requested" 0 "Connection not Requested" ;
VAL_ 2566547966 HVBusHiSideResistorConnectReq 3 "Don't care/take no action" 2 "Reserved" 1 "Connection Requested" 0 "Connection not Requested" ;
VAL_ 2566547966 HVBusPassiveIsolTestCmd 3 "Don't care/Take no action" 2 "Inhibit Passive Isolation Test" 1 "Passive Isolation Test request" 0 "Passive Isolation Test not requested" ;
VAL_ 2566547966 HVBusActiveIsolTestCmd 3 "Don't care/Take no action" 2 "Inhibit Active Isolation Test" 1 "Active Isolation Test request" 0 "Active Isolation Test not requested" ;
VAL_ 2566547710 HVBusLowSideResistorConnectReq 3 "Don't care/take no action" 2 "Reserved" 1 "Connection Requested" 0 "Connection not Requested" ;
VAL_ 2566547710 HVBusHiSideResistorConnectReq 3 "Don't care/take no action" 2 "Reserved" 1 "Connection Requested" 0 "Connection not Requested" ;
VAL_ 2566547710 HVBusPassiveIsolTestCmd 3 "Don't care/Take no action" 2 "Inhibit Passive Isolation Test" 1 "Passive Isolation Test request" 0 "Passive Isolation Test not requested" ;
VAL_ 2566547710 HVBusActiveIsolTestCmd 3 "Don't care/Take no action" 2 "Inhibit Active Isolation Test" 1 "Active Isolation Test request" 0 "Active Isolation Test not requested" ;
VAL_ 2365219838 TractorHazardLightsCmd 3 "Don't Care" 2 "Reserved" 1 "Activate" 0 "De-activate" ;
VAL_ 2365219838 Data2ReqCmd 3 "Don't Care" 2 "Reserved" 1 "Response requested" 0 "Response not requested" ;
VAL_ 2566546174 TractorHazardLights 3 "Not Available" 2 "Fault Detected" 1 "Activated" 0 "De-activated" ;
VAL_ 2566545662 FullChargingComplete 3 "Not available" 2 "Error" 1 "Full charging complete" 0 "Full charging not complete" ;
VAL_ 2566545662 BulkChargingComplete 3 "Not available" 2 "Error" 1 "Bulk charging complete" 0 "Bulk charging not complete" ;
